VERSION "created by canmatrix"

NS_ :

BS_:

BU_: BDC_Body CHC DME1 EME FLA NiVi ZGW Kombi Kombi_Basis Diagnosetool_FA_CAN CDC_ZGW DME2 ELV Gliwa_T1_Host FA_CAN_Dummy

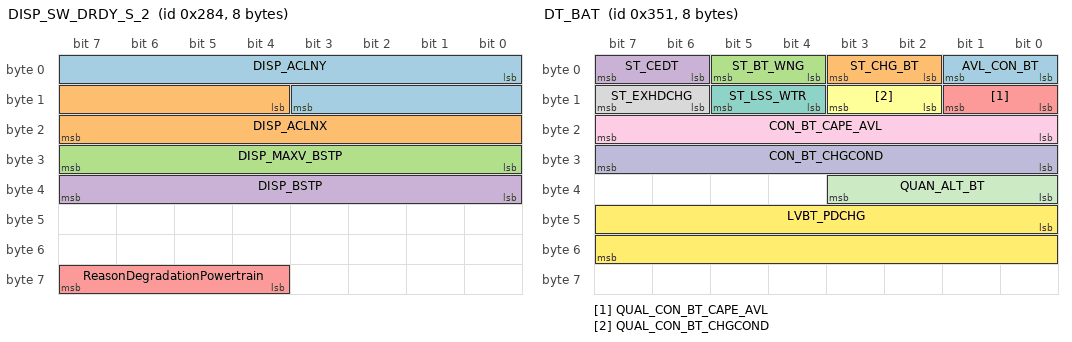
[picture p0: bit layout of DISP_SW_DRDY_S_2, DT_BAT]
BO_ 644 DISP_SW_DRDY_S_2: 8 DME1
 SG_ DISP_ACLNY : 0|12@1+ (0.5,-100) [-150|-50] "%" ZGW
 SG_ DISP_ACLNX : 12|12@1+ (0.5,-100) [-150|-50] "%" ZGW
 SG_ DISP_MAXV_BSTP : 24|8@1+ (0.05,0) [0.00|0.635] "bar" ZGW
 SG_ DISP_BSTP : 32|8@1+ (0.5,0) [0|50] "%" ZGW
 SG_ ReasonDegradationPowertrain : 60|4@1+ (1,0) [0|15] "" Kombi

BO_ 1062 DISP_SW_DRDY_TECGY_EXPI: 4 ZGW
 SG_ ST_SAIL_DRV : 24|4@1+ (1,0) [0|15] "" Kombi,Kombi_Basis

BO_ 1080 DISP_SW_DRDY_TECGY_EXPI_B: 4 ZGW
 SG_ ST_SAIL_DRV : 24|4@1+ (1,0) [0|15] "" Kombi

BO_ 849 DT_BAT: 8 DME1
 SG_ AVL_CON_BT : 0|2@1+ (1,0) [0|3] "" BDC_Body
 SG_ ST_CHG_BT : 2|2@1+ (1,0) [0|3] "" ZGW,BDC_Body
 SG_ ST_BT_WNG : 4|2@1+ (1,0) [0|3] "" ZGW,BDC_Body
 SG_ ST_CEDT : 6|2@1+ (1,0) [0|3] "" BDC_Body
 SG_ QUAL_CON_BT_CAPE_AVL : 8|2@1+ (1,0) [0|3] "" BDC_Body
 SG_ QUAL_CON_BT_CHGCOND : 10|2@1+ (1,0) [0|3] "" ZGW,BDC_Body
 SG_ ST_LSS_WTR : 12|2@1+ (1,0) [0|3] "" BDC_Body
 SG_ ST_EXHDCHG : 14|2@1+ (1,0) [0|3] "" ZGW,BDC_Body
 SG_ CON_BT_CAPE_AVL : 16|8@1+ (1,0) [0|150] "%" ZGW,BDC_Body
 SG_ CON_BT_CHGCOND : 24|8@1+ (1,0) [0|150] "%" ZGW,BDC_Body
 SG_ QUAN_ALT_BT : 32|4@1+ (1,0) [0|14] "This unit fulfills the required AUTOSAR reference to a unit. No real unit is defined." ZGW,BDC_Body
 SG_ LVBT_PDCHG : 40|16@1+ (0.001,-32.766) [-32.798766|-32.733234] "Ah" BDC_Body

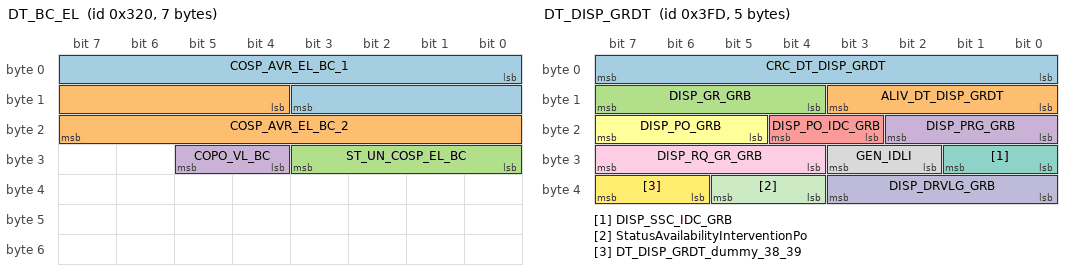
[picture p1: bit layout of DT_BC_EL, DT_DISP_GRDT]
BO_ 800 DT_BC_EL: 7 Kombi
 SG_ COSP_AVR_EL_BC_1 : 0|12@1+ (1,-999) [-1998|0] "This unit fulfills the required AUTOSAR reference to a unit. No real unit is defined." ZGW
 SG_ COSP_AVR_EL_BC_2 : 12|12@1+ (1,-999) [-1998|0] "This unit fulfills the required AUTOSAR reference to a unit. No real unit is defined." ZGW
 SG_ ST_UN_COSP_EL_BC : 24|4@1+ (1,0) [0|15] "" ZGW
 SG_ COPO_VL_BC : 28|2@1+ (1,0) [0|3] "" ZGW

BO_ 1021 DT_DISP_GRDT: 5 DME1
 SG_ CRC_DT_DISP_GRDT : 0|8@1+ (1,0) [0|255] "This unit fulfills the required AUTOSAR reference to a unit. No real unit is defined." Vector__XXX
 SG_ ALIV_DT_DISP_GRDT : 8|4@1+ (1,0) [0|14] "This unit fulfills the required AUTOSAR reference to a unit. No real unit is defined." Vector__XXX
 SG_ DISP_GR_GRB : 12|4@1+ (1,0) [0|15] "" Vector__XXX
 SG_ DISP_PRG_GRB : 16|3@1+ (1,0) [0|7] "" Vector__XXX
 SG_ DISP_PO_IDC_GRB : 19|2@1+ (1,0) [0|3] "" Vector__XXX
 SG_ DISP_PO_GRB : 21|3@1+ (1,0) [0|7] "" Vector__XXX
 SG_ DISP_SSC_IDC_GRB : 24|2@1+ (1,0) [0|3] "" Vector__XXX
 SG_ GEN_IDLI : 26|2@1+ (1,0) [0|3] "" Vector__XXX
 SG_ DISP_RQ_GR_GRB : 28|4@1+ (1,0) [0|15] "" Vector__XXX
 SG_ DISP_DRVLG_GRB : 32|4@1+ (1,0) [0|15] "" Vector__XXX
 SG_ StatusAvailabilityInterventionPo : 36|2@1+ (1,0) [0|3] "" Vector__XXX
 SG_ DT_DISP_GRDT_dummy_38_39 : 38|2@1+ (1,0) [-2|1] "" Vector__XXX

BO_ 996 DT_EL_GEY: 6 ZGW
 SG_ AVL_PWR_EL_GEY : 0|8@1+ (0.04,0) [0.00|0.4064] "kW" DME2,EME,DME1
 SG_ AVL_I_EL_GEY : 8|8@1+ (0.2,0) [0|10.16] "A" CDC_ZGW,EME

BO_ 1042 DT_EWS_1: 8 BDC_Body
 SG_ EWS_COMM_1_1 : 0|32@1+ (1,0) [0|4294967295] "This unit fulfills the required AUTOSAR reference to a unit. No real unit is defined." DME2,DME1
 SG_ EWS_COMM_1_2 : 32|32@1+ (1,0) [0|4294967295] "This unit fulfills the required AUTOSAR reference to a unit. No real unit is defined." DME2,DME1

BO_ 1043 DT_EWS_2: 8 DME1
 SG_ EWS_COMM_2_1 : 0|32@1+ (1,0) [0|4294967295] "This unit fulfills the required AUTOSAR reference to a unit. No real unit is defined." BDC_Body
 SG_ EWS_COMM_2_2 : 32|32@1+ (1,0) [0|4294967295] "This unit fulfills the required AUTOSAR reference to a unit. No real unit is defined." BDC_Body

BO_ 1044 DT_EWS_7: 8 BDC_Body
 SG_ EWS_COMM_7_1 : 0|32@1+ (1,0) [0|4294967295] "This unit fulfills the required AUTOSAR reference to a unit. No real unit is defined." ELV
 SG_ EWS_COMM_7_2 : 32|32@1+ (1,0) [0|4294967295] "This unit fulfills the required AUTOSAR reference to a unit. No real unit is defined." ELV

BO_ 1045 DT_EWS_8: 8 ELV
 SG_ EWS_COMM_8_1 : 0|32@1+ (1,0) [0|4294967295] "This unit fulfills the required AUTOSAR reference to a unit. No real unit is defined." BDC_Body
 SG_ EWS_COMM_8_2 : 32|32@1+ (1,0) [0|4294967295] "This unit fulfills the required AUTOSAR reference to a unit. No real unit is defined." BDC_Body

BO_ 200 DT_FN_HDC: 8 ZGW
 SG_ QU_FN_HDC : 0|8@1+ (1,0) [0|255] "" BDC_Body

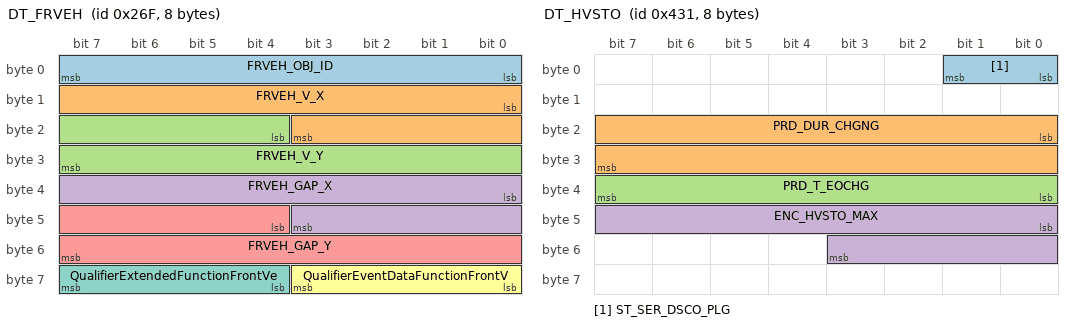
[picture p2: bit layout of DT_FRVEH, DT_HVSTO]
BO_ 623 DT_FRVEH: 8 ZGW
 SG_ FRVEH_OBJ_ID : 0|8@1+ (1,0) [0|252] "This unit fulfills the required AUTOSAR reference to a unit. No real unit is defined." DME2,DME1
 SG_ FRVEH_V_X : 8|12@1+ (0.1,-150) [-165|-135] "m/s" DME2,DME1
 SG_ FRVEH_V_Y : 20|12@1+ (0.1,-150) [-165|-135] "m/s" DME2,DME1
 SG_ FRVEH_GAP_X : 32|12@1+ (0.1,0) [0|30] "m" DME2,DME1
 SG_ FRVEH_GAP_Y : 44|12@1+ (0.2,-300) [-360|-240] "m" DME2,DME1
 SG_ QualifierEventDataFunctionFrontV : 56|4@1+ (1,0) [0|15] "" DME1
 SG_ QualifierExtendedFunctionFrontVe : 60|4@1+ (1,0) [0|15] "" DME1

BO_ 624 DT_FRVEH_EXT: 8 ZGW
 SG_ FRVEH_EXT_OBJ_ID : 0|8@1+ (1,0) [0|252] "This unit fulfills the required AUTOSAR reference to a unit. No real unit is defined." DME2,DME1
 SG_ FRVEH_EXT_OBJ_TYP : 8|8@1+ (1,0) [0|255] "" DME2,DME1
 SG_ FRVEH_EXT_ST_MOV : 16|8@1+ (1,0) [0|255] "" DME2,DME1
 SG_ FRVEH_EXT_WID : 24|8@1+ (0.1,0) [0|2.52] "m" DME2,DME1

BO_ 1073 DT_HVSTO: 8 EME
 SG_ ST_SER_DSCO_PLG : 0|2@1+ (1,0) [0|3] "" CDC_ZGW,ZGW
 SG_ PRD_DUR_CHGNG : 16|16@1+ (1,0) [0|65532] "min" ZGW
 SG_ PRD_T_EOCHG : 32|8@1+ (5,0) [0|6350] "min" ZGW
 SG_ ENC_HVSTO_MAX : 40|12@1+ (0.02,0) [0.00|1.6376] "kWh" ZGW

BO_ 569 DT_HVSTO_2: 8 EME
 SG_ PRD_ENERG_CHGCOND_2_COS : 8|16@1+ (1,0) [0|65534] "Wh" CDC_ZGW,ZGW
 SG_ PRD_ENERG_CHGTAR_2_HVSTO : 24|16@1+ (0.02,0) [0.00|26.2128] "kWh" ZGW
 SG_ AVL_ISRE : 40|8@1+ (10,0) [0|20470] "kOhm" CDC_ZGW

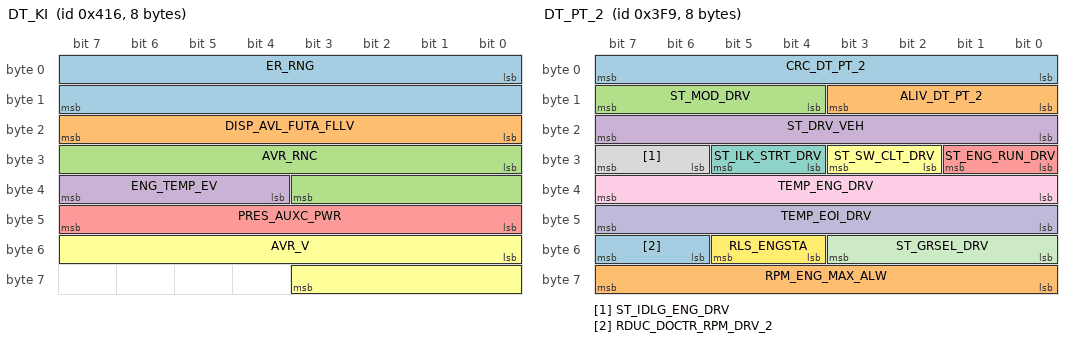
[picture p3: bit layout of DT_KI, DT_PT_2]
BO_ 1046 DT_KI: 8 Kombi
 SG_ ER_RNG : 0|16@1+ (1,0) [0|4000] "km" ZGW
 SG_ DISP_AVL_FUTA_FLLV : 16|8@1+ (0.5,0) [0|50] "%" ZGW,BDC_Body
 SG_ AVR_RNC : 24|12@1+ (0.05,0) [0.00|5.00] "kWh/100km" ZGW
 SG_ ENG_TEMP_EV : 36|4@1+ (1,0) [0|15] "" ZGW
 SG_ PRES_AUXC_PWR : 40|8@1+ (0.25,0) [0.00|5.00] "kW" ZGW
 SG_ AVR_V : 48|12@1+ (0.1,0) [0|30] "km/h" ZGW

BO_ 1017 DT_PT_2: 8 DME1
 SG_ CRC_DT_PT_2 : 0|8@1+ (1,0) [0|255] "This unit fulfills the required AUTOSAR reference to a unit. No real unit is defined." Vector__XXX
 SG_ ALIV_DT_PT_2 : 8|4@1+ (1,0) [0|14] "This unit fulfills the required AUTOSAR reference to a unit. No real unit is defined." Vector__XXX
 SG_ ST_MOD_DRV : 12|4@1+ (1,0) [0|15] "" Vector__XXX
 SG_ ST_DRV_VEH : 16|8@1+ (1,0) [0|255] "" Vector__XXX
 SG_ ST_ENG_RUN_DRV : 24|2@1+ (1,0) [0|3] "" Vector__XXX
 SG_ ST_SW_CLT_DRV : 26|2@1+ (1,0) [0|3] "" Vector__XXX
 SG_ ST_ILK_STRT_DRV : 28|2@1+ (1,0) [0|3] "" Vector__XXX
 SG_ ST_IDLG_ENG_DRV : 30|2@1+ (1,0) [0|3] "" Vector__XXX
 SG_ TEMP_ENG_DRV : 32|8@1+ (1,-48) [-48|144] "°C" Vector__XXX
 SG_ TEMP_EOI_DRV : 40|8@1+ (1,-48) [-48|170] "°C" Vector__XXX
 SG_ ST_GRSEL_DRV : 48|4@1+ (1,0) [0|15] "" Vector__XXX
 SG_ RLS_ENGSTA : 52|2@1+ (1,0) [0|3] "" Vector__XXX
 SG_ RDUC_DOCTR_RPM_DRV_2 : 54|2@1+ (1,0) [0|3] "" Vector__XXX
 SG_ RPM_ENG_MAX_ALW : 56|8@1+ (50,0) [0|635000] "1/min" Vector__XXX

BO_ 811 DT_RNG_CALC: 8 EME
 SG_ AVL_ENERG_COSP_MOT_TRCT : 0|16@1+ (100,0) [0|655340000] "Ws" Kombi
 SG_ AVL_ENERG_MOT_RECUP : 16|16@1+ (1,0) [0|65534] "Ws" Kombi

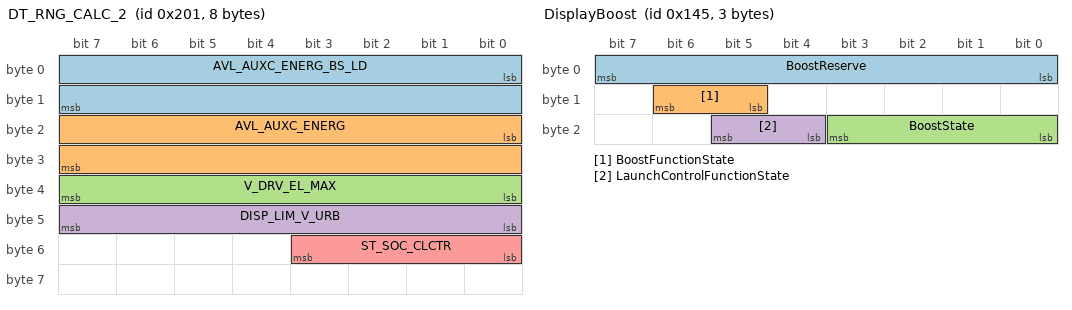
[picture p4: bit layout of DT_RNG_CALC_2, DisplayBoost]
BO_ 513 DT_RNG_CALC_2: 8 EME
 SG_ AVL_AUXC_ENERG_BS_LD : 0|16@1+ (1,0) [0|65534] "Ws" Kombi
 SG_ AVL_AUXC_ENERG : 16|16@1+ (1,0) [0|65534] "Ws" Kombi
 SG_ V_DRV_EL_MAX : 32|8@1+ (1,0) [0|252] "km/h" Kombi
 SG_ DISP_LIM_V_URB : 40|8@1+ (0.5,0) [0|62.5] "km/h" Kombi
 SG_ ST_SOC_CLCTR : 48|4@1+ (1,0) [0|15] "" Kombi,Kombi_Basis

BO_ 984 DXP_MOD: 8 ZGW
 SG_ RQ_SW_DXP_KDIS : 4|2@1+ (1,0) [0|3] "" Kombi,Kombi_Basis
 SG_ AVL_MOD_DXP : 8|6@1+ (1,0) [0|63] "" Kombi,Kombi_Basis

BO_ 325 DisplayBoost: 3 DME1
 SG_ BoostReserve : 0|8@1+ (0.5,0) [0|50] "%" Kombi
 SG_ BoostFunctionState : 13|2@1+ (1,0) [0|3] "" Kombi
 SG_ BoostState : 16|4@1+ (1,0) [0|15] "" Kombi
 SG_ LaunchControlFunctionState : 20|2@1+ (1,0) [0|3] "" Kombi

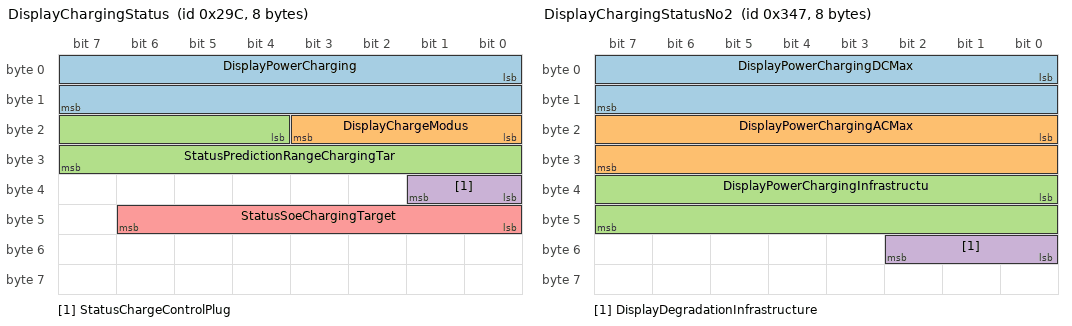
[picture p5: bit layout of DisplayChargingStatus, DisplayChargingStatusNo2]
BO_ 668 DisplayChargingStatus: 8 Diagnosetool_FA_CAN
 SG_ DisplayPowerCharging : 0|16@1+ (10,0) [0|6553200] "W" ZGW,Kombi
 SG_ DisplayChargeModus : 16|4@1+ (1,0) [0|15] "" Kombi
 SG_ StatusPredictionRangeChargingTar : 20|12@1+ (1,0) [0|4092] "km" Kombi
 SG_ StatusChargeControlPlug : 32|2@1+ (1,0) [0|3] "" Kombi
 SG_ StatusSoeChargingTarget : 40|7@1+ (1,0) [0|100] "%" Kombi

BO_ 839 DisplayChargingStatusNo2: 8 EME
 SG_ DisplayPowerChargingDCMax : 0|16@1+ (10,0) [0|6553200] "W" Kombi
 SG_ DisplayPowerChargingACMax : 16|16@1+ (1,0) [0|65532] "W" Kombi
 SG_ DisplayPowerChargingInfrastructu : 32|16@1+ (10,0) [0|6553200] "W" Kombi
 SG_ DisplayDegradationInfrastructure : 48|3@1+ (1,0) [0|7] "" Kombi

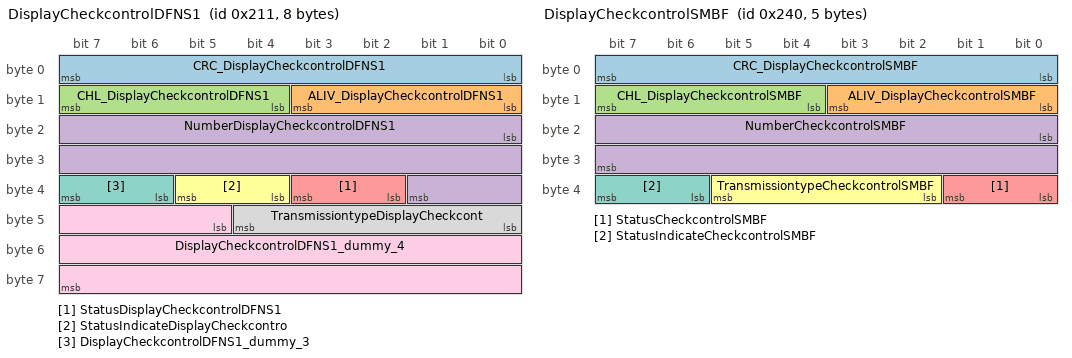
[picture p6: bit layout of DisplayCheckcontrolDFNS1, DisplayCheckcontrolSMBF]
BO_ 529 DisplayCheckcontrolDFNS1: 8 DME1
 SG_ CRC_DisplayCheckcontrolDFNS1 : 0|8@1+ (1,0) [0|255] "This unit fulfills the required AUTOSAR reference to a unit. No real unit is defined." Vector__XXX
 SG_ ALIV_DisplayCheckcontrolDFNS1 : 8|4@1+ (1,0) [0|14] "This unit fulfills the required AUTOSAR reference to a unit. No real unit is defined." Vector__XXX
 SG_ CHL_DisplayCheckcontrolDFNS1 : 12|4@1+ (1,0) [0|14] "This unit fulfills the required AUTOSAR reference to a unit. No real unit is defined." Vector__XXX
 SG_ NumberDisplayCheckcontrolDFNS1 : 16|18@1+ (1,0) [0|65534] "This unit fulfills the required AUTOSAR reference to a unit. No real unit is defined." Vector__XXX
 SG_ StatusDisplayCheckcontrolDFNS1 : 34|2@1+ (1,0) [0|3] "" Vector__XXX
 SG_ StatusIndicateDisplayCheckcontro : 36|2@1+ (1,0) [0|3] "" Vector__XXX
 SG_ DisplayCheckcontrolDFNS1_dummy_3 : 38|2@1+ (1,0) [-2|1] "" Vector__XXX
 SG_ TransmissiontypeDisplayCheckcont : 40|5@1+ (1,0) [0|14] "s" Vector__XXX
 SG_ DisplayCheckcontrolDFNS1_dummy_4 : 45|19@1+ (1,0) [-262144|262143] "" Vector__XXX

BO_ 576 DisplayCheckcontrolSMBF: 5 ZGW
 SG_ CRC_DisplayCheckcontrolSMBF : 0|8@1+ (1,0) [0|255] "This unit fulfills the required AUTOSAR reference to a unit. No real unit is defined." Vector__XXX
 SG_ ALIV_DisplayCheckcontrolSMBF : 8|4@1+ (1,0) [0|14] "This unit fulfills the required AUTOSAR reference to a unit. No real unit is defined." Vector__XXX
 SG_ CHL_DisplayCheckcontrolSMBF : 12|4@1+ (1,0) [0|14] "This unit fulfills the required AUTOSAR reference to a unit. No real unit is defined." Vector__XXX
 SG_ NumberCheckcontrolSMBF : 16|16@1+ (1,0) [0|65534] "This unit fulfills the required AUTOSAR reference to a unit. No real unit is defined." Vector__XXX
 SG_ StatusCheckcontrolSMBF : 32|2@1+ (1,0) [0|3] "" Vector__XXX
 SG_ TransmissiontypeCheckcontrolSMBF : 34|4@1+ (1,0) [0|14] "s" Vector__XXX
 SG_ StatusIndicateCheckcontrolSMBF : 38|2@1+ (1,0) [0|3] "" Vector__XXX

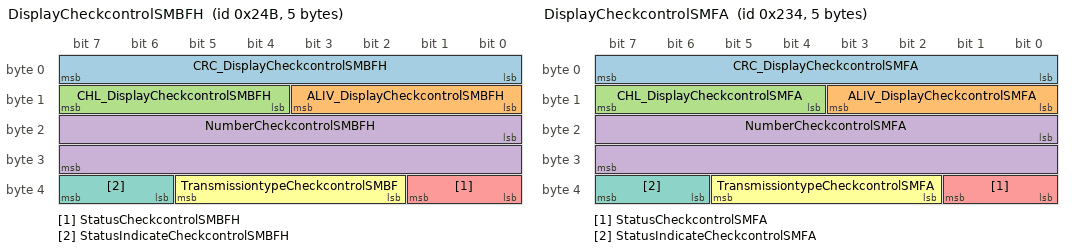
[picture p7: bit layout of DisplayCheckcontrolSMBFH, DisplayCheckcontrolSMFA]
BO_ 587 DisplayCheckcontrolSMBFH: 5 ZGW
 SG_ CRC_DisplayCheckcontrolSMBFH : 0|8@1+ (1,0) [0|255] "This unit fulfills the required AUTOSAR reference to a unit. No real unit is defined." Vector__XXX
 SG_ ALIV_DisplayCheckcontrolSMBFH : 8|4@1+ (1,0) [0|14] "This unit fulfills the required AUTOSAR reference to a unit. No real unit is defined." Vector__XXX
 SG_ CHL_DisplayCheckcontrolSMBFH : 12|4@1+ (1,0) [0|14] "This unit fulfills the required AUTOSAR reference to a unit. No real unit is defined." Vector__XXX
 SG_ NumberCheckcontrolSMBFH : 16|16@1+ (1,0) [0|65534] "This unit fulfills the required AUTOSAR reference to a unit. No real unit is defined." Vector__XXX
 SG_ StatusCheckcontrolSMBFH : 32|2@1+ (1,0) [0|3] "" Vector__XXX
 SG_ TransmissiontypeCheckcontrolSMBF : 34|4@1+ (1,0) [0|14] "s" Vector__XXX
 SG_ StatusIndicateCheckcontrolSMBFH : 38|2@1+ (1,0) [0|3] "" Vector__XXX

BO_ 564 DisplayCheckcontrolSMFA: 5 ZGW
 SG_ CRC_DisplayCheckcontrolSMFA : 0|8@1+ (1,0) [0|255] "This unit fulfills the required AUTOSAR reference to a unit. No real unit is defined." Vector__XXX
 SG_ ALIV_DisplayCheckcontrolSMFA : 8|4@1+ (1,0) [0|14] "This unit fulfills the required AUTOSAR reference to a unit. No real unit is defined." Vector__XXX
 SG_ CHL_DisplayCheckcontrolSMFA : 12|4@1+ (1,0) [0|14] "This unit fulfills the required AUTOSAR reference to a unit. No real unit is defined." Vector__XXX
 SG_ NumberCheckcontrolSMFA : 16|16@1+ (1,0) [0|65534] "This unit fulfills the required AUTOSAR reference to a unit. No real unit is defined." Vector__XXX
 SG_ StatusCheckcontrolSMFA : 32|2@1+ (1,0) [0|3] "" Vector__XXX
 SG_ TransmissiontypeCheckcontrolSMFA : 34|4@1+ (1,0) [0|14] "s" Vector__XXX
 SG_ StatusIndicateCheckcontrolSMFA : 38|2@1+ (1,0) [0|3] "" Vector__XXX

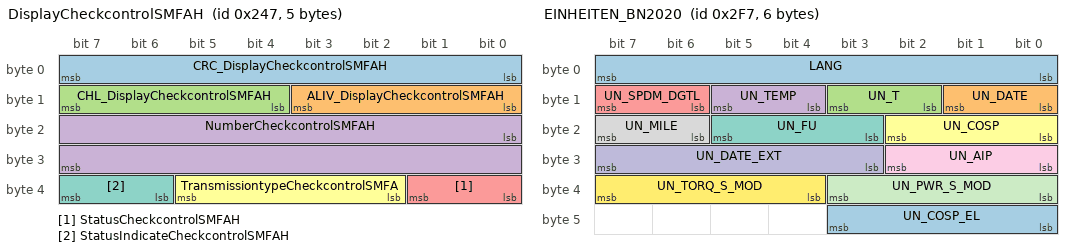
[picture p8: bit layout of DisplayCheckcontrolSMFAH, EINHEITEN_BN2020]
BO_ 583 DisplayCheckcontrolSMFAH: 5 ZGW
 SG_ CRC_DisplayCheckcontrolSMFAH : 0|8@1+ (1,0) [0|255] "This unit fulfills the required AUTOSAR reference to a unit. No real unit is defined." Vector__XXX
 SG_ ALIV_DisplayCheckcontrolSMFAH : 8|4@1+ (1,0) [0|14] "This unit fulfills the required AUTOSAR reference to a unit. No real unit is defined." Vector__XXX
 SG_ CHL_DisplayCheckcontrolSMFAH : 12|4@1+ (1,0) [0|14] "This unit fulfills the required AUTOSAR reference to a unit. No real unit is defined." Vector__XXX
 SG_ NumberCheckcontrolSMFAH : 16|16@1+ (1,0) [0|65534] "This unit fulfills the required AUTOSAR reference to a unit. No real unit is defined." Vector__XXX
 SG_ StatusCheckcontrolSMFAH : 32|2@1+ (1,0) [0|3] "" Vector__XXX
 SG_ TransmissiontypeCheckcontrolSMFA : 34|4@1+ (1,0) [0|14] "s" Vector__XXX
 SG_ StatusIndicateCheckcontrolSMFAH : 38|2@1+ (1,0) [0|3] "" Vector__XXX

BO_ 1174 DisplayDataWaterInjection: 4 DME1
 SG_ DisplayRefillVolumeWaterInjectio : 0|8@1+ (0.1,0) [0|2.5] "l" ZGW
 SG_ DisplayFluidLevelWaterInjection : 8|4@1+ (10,0) [0|1200] "%" ZGW
 SG_ DispAvailabilityWaterInjection : 14|10@1+ (1,0) [0|1023] "" ZGW

BO_ 180 ECU_DOM_CHAS: 4 ZGW
 SG_ CTR_ECU_CHAS : 0|32@1+ (1,0) [0|4294967295] "" FLA,ELV,Kombi_Basis,Diagnosetool_FA_CAN,CHC,Kombi

BO_ 182 ECU_DOM_ENTAI: 8 ZGW
 SG_ CTR_ECU_ENTAI : 0|24@1+ (1,0) [0|16777215] "" Diagnosetool_FA_CAN

BO_ 806 EFFY_INFO_DT: 8 Kombi
 SG_ Multiplexor M : 0|8@1+ (1,0) [-128|127] "" Vector__XXX

BO_ 759 EINHEITEN_BN2020: 6 Kombi
 SG_ LANG : 0|8@1+ (1,0) [0|255] "" ZGW,BDC_Body
 SG_ UN_DATE : 8|2@1+ (1,0) [0|3] "" ZGW
 SG_ UN_T : 10|2@1+ (1,0) [0|3] "" ZGW,BDC_Body
 SG_ UN_TEMP : 12|2@1+ (1,0) [0|3] "" ZGW,BDC_Body
 SG_ UN_SPDM_DGTL : 14|2@1+ (1,0) [0|3] "" ZGW
 SG_ UN_COSP : 16|3@1+ (1,0) [0|7] "" ZGW,BDC_Body
 SG_ UN_FU : 19|3@1+ (1,0) [0|7] "" ZGW,BDC_Body
 SG_ UN_MILE : 22|2@1+ (1,0) [0|3] "" ZGW,BDC_Body
 SG_ UN_AIP : 24|3@1+ (1,0) [0|7] "" ZGW,BDC_Body
 SG_ UN_DATE_EXT : 27|5@1+ (1,0) [0|31] "" ZGW,BDC_Body
 SG_ UN_PWR_S_MOD : 32|4@1+ (1,0) [0|15] "" ZGW
 SG_ UN_TORQ_S_MOD : 36|4@1+ (1,0) [0|15] "" ZGW
 SG_ UN_COSP_EL : 40|4@1+ (1,0) [0|15] "" ZGW,BDC_Body

BO_ 589 ERRM_BN_U: 2 ZGW
 SG_ CTR_ERRM_BN_U : 0|6@1+ (1,0) [0|63] "" CDC_ZGW,ELV

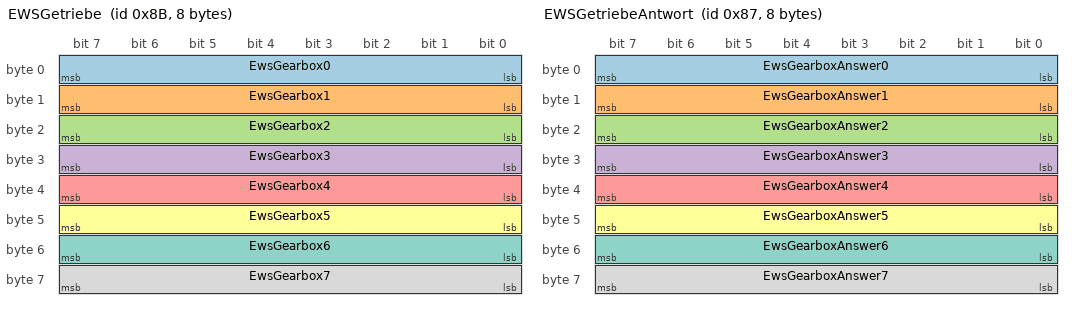
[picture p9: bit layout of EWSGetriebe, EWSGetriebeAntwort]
BO_ 139 EWSGetriebe: 8 DME1
 SG_ EwsGearbox0 : 0|8@1+ (1,0) [0|255] "This unit fulfills the required AUTOSAR reference to a unit. No real unit is defined." BDC_Body
 SG_ EwsGearbox1 : 8|8@1+ (1,0) [0|255] "This unit fulfills the required AUTOSAR reference to a unit. No real unit is defined." BDC_Body
 SG_ EwsGearbox2 : 16|8@1+ (1,0) [0|255] "This unit fulfills the required AUTOSAR reference to a unit. No real unit is defined." BDC_Body
 SG_ EwsGearbox3 : 24|8@1+ (1,0) [0|255] "This unit fulfills the required AUTOSAR reference to a unit. No real unit is defined." BDC_Body
 SG_ EwsGearbox4 : 32|8@1+ (1,0) [0|255] "This unit fulfills the required AUTOSAR reference to a unit. No real unit is defined." BDC_Body
 SG_ EwsGearbox5 : 40|8@1+ (1,0) [0|255] "This unit fulfills the required AUTOSAR reference to a unit. No real unit is defined." BDC_Body
 SG_ EwsGearbox6 : 48|8@1+ (1,0) [0|255] "This unit fulfills the required AUTOSAR reference to a unit. No real unit is defined." BDC_Body
 SG_ EwsGearbox7 : 56|8@1+ (1,0) [0|255] "This unit fulfills the required AUTOSAR reference to a unit. No real unit is defined." BDC_Body

BO_ 135 EWSGetriebeAntwort: 8 BDC_Body
 SG_ EwsGearboxAnswer0 : 0|8@1+ (1,0) [0|255] "This unit fulfills the required AUTOSAR reference to a unit. No real unit is defined." DME1
 SG_ EwsGearboxAnswer1 : 8|8@1+ (1,0) [0|255] "This unit fulfills the required AUTOSAR reference to a unit. No real unit is defined." DME1
 SG_ EwsGearboxAnswer2 : 16|8@1+ (1,0) [0|255] "This unit fulfills the required AUTOSAR reference to a unit. No real unit is defined." DME1
 SG_ EwsGearboxAnswer3 : 24|8@1+ (1,0) [0|255] "This unit fulfills the required AUTOSAR reference to a unit. No real unit is defined." DME1
 SG_ EwsGearboxAnswer4 : 32|8@1+ (1,0) [0|255] "This unit fulfills the required AUTOSAR reference to a unit. No real unit is defined." DME1
 SG_ EwsGearboxAnswer5 : 40|8@1+ (1,0) [0|255] "This unit fulfills the required AUTOSAR reference to a unit. No real unit is defined." DME1
 SG_ EwsGearboxAnswer6 : 48|8@1+ (1,0) [0|255] "This unit fulfills the required AUTOSAR reference to a unit. No real unit is defined." DME1
 SG_ EwsGearboxAnswer7 : 56|8@1+ (1,0) [0|255] "This unit fulfills the required AUTOSAR reference to a unit. No real unit is defined." DME1

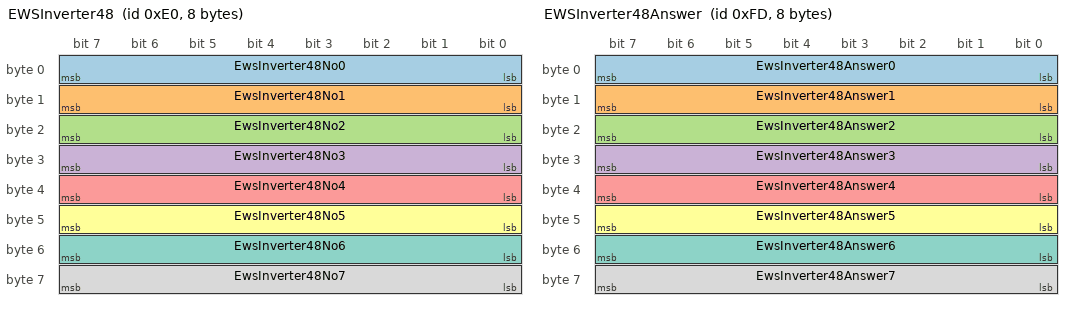
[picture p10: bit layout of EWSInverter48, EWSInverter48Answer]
BO_ 224 EWSInverter48: 8 DME1
 SG_ EwsInverter48No0 : 0|8@1+ (1,0) [0|255] "This unit fulfills the required AUTOSAR reference to a unit. No real unit is defined." BDC_Body
 SG_ EwsInverter48No1 : 8|8@1+ (1,0) [0|255] "This unit fulfills the required AUTOSAR reference to a unit. No real unit is defined." BDC_Body
 SG_ EwsInverter48No2 : 16|8@1+ (1,0) [0|255] "This unit fulfills the required AUTOSAR reference to a unit. No real unit is defined." BDC_Body
 SG_ EwsInverter48No3 : 24|8@1+ (1,0) [0|255] "This unit fulfills the required AUTOSAR reference to a unit. No real unit is defined." BDC_Body
 SG_ EwsInverter48No4 : 32|8@1+ (1,0) [0|255] "This unit fulfills the required AUTOSAR reference to a unit. No real unit is defined." BDC_Body
 SG_ EwsInverter48No5 : 40|8@1+ (1,0) [0|255] "This unit fulfills the required AUTOSAR reference to a unit. No real unit is defined." BDC_Body
 SG_ EwsInverter48No6 : 48|8@1+ (1,0) [0|255] "This unit fulfills the required AUTOSAR reference to a unit. No real unit is defined." BDC_Body
 SG_ EwsInverter48No7 : 56|8@1+ (1,0) [0|255] "This unit fulfills the required AUTOSAR reference to a unit. No real unit is defined." BDC_Body

BO_ 253 EWSInverter48Answer: 8 BDC_Body
 SG_ EwsInverter48Answer0 : 0|8@1+ (1,0) [0|255] "This unit fulfills the required AUTOSAR reference to a unit. No real unit is defined." DME1
 SG_ EwsInverter48Answer1 : 8|8@1+ (1,0) [0|255] "This unit fulfills the required AUTOSAR reference to a unit. No real unit is defined." DME1
 SG_ EwsInverter48Answer2 : 16|8@1+ (1,0) [0|255] "This unit fulfills the required AUTOSAR reference to a unit. No real unit is defined." DME1
 SG_ EwsInverter48Answer3 : 24|8@1+ (1,0) [0|255] "This unit fulfills the required AUTOSAR reference to a unit. No real unit is defined." DME1
 SG_ EwsInverter48Answer4 : 32|8@1+ (1,0) [0|255] "This unit fulfills the required AUTOSAR reference to a unit. No real unit is defined." DME1
 SG_ EwsInverter48Answer5 : 40|8@1+ (1,0) [0|255] "This unit fulfills the required AUTOSAR reference to a unit. No real unit is defined." DME1
 SG_ EwsInverter48Answer6 : 48|8@1+ (1,0) [0|255] "This unit fulfills the required AUTOSAR reference to a unit. No real unit is defined." DME1
 SG_ EwsInverter48Answer7 : 56|8@1+ (1,0) [0|255] "This unit fulfills the required AUTOSAR reference to a unit. No real unit is defined." DME1

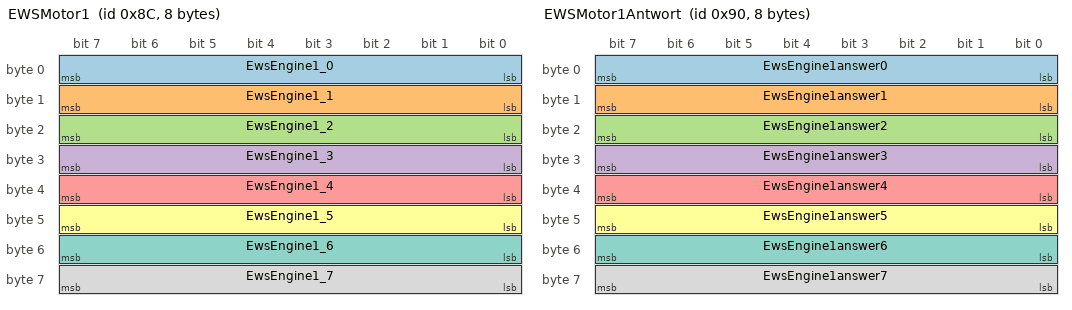
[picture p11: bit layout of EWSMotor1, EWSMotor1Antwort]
BO_ 140 EWSMotor1: 8 DME1
 SG_ EwsEngine1_0 : 0|8@1+ (1,0) [0|255] "This unit fulfills the required AUTOSAR reference to a unit. No real unit is defined." BDC_Body
 SG_ EwsEngine1_1 : 8|8@1+ (1,0) [0|255] "This unit fulfills the required AUTOSAR reference to a unit. No real unit is defined." BDC_Body
 SG_ EwsEngine1_2 : 16|8@1+ (1,0) [0|255] "This unit fulfills the required AUTOSAR reference to a unit. No real unit is defined." BDC_Body
 SG_ EwsEngine1_3 : 24|8@1+ (1,0) [0|255] "This unit fulfills the required AUTOSAR reference to a unit. No real unit is defined." BDC_Body
 SG_ EwsEngine1_4 : 32|8@1+ (1,0) [0|255] "This unit fulfills the required AUTOSAR reference to a unit. No real unit is defined." BDC_Body
 SG_ EwsEngine1_5 : 40|8@1+ (1,0) [0|255] "This unit fulfills the required AUTOSAR reference to a unit. No real unit is defined." BDC_Body
 SG_ EwsEngine1_6 : 48|8@1+ (1,0) [0|255] "This unit fulfills the required AUTOSAR reference to a unit. No real unit is defined." BDC_Body
 SG_ EwsEngine1_7 : 56|8@1+ (1,0) [0|255] "This unit fulfills the required AUTOSAR reference to a unit. No real unit is defined." BDC_Body

BO_ 144 EWSMotor1Antwort: 8 BDC_Body
 SG_ EwsEngine1answer0 : 0|8@1+ (1,0) [0|255] "This unit fulfills the required AUTOSAR reference to a unit. No real unit is defined." DME1
 SG_ EwsEngine1answer1 : 8|8@1+ (1,0) [0|255] "This unit fulfills the required AUTOSAR reference to a unit. No real unit is defined." DME1
 SG_ EwsEngine1answer2 : 16|8@1+ (1,0) [0|255] "This unit fulfills the required AUTOSAR reference to a unit. No real unit is defined." DME1
 SG_ EwsEngine1answer3 : 24|8@1+ (1,0) [0|255] "This unit fulfills the required AUTOSAR reference to a unit. No real unit is defined." DME1
 SG_ EwsEngine1answer4 : 32|8@1+ (1,0) [0|255] "This unit fulfills the required AUTOSAR reference to a unit. No real unit is defined." DME1
 SG_ EwsEngine1answer5 : 40|8@1+ (1,0) [0|255] "This unit fulfills the required AUTOSAR reference to a unit. No real unit is defined." DME1
 SG_ EwsEngine1answer6 : 48|8@1+ (1,0) [0|255] "This unit fulfills the required AUTOSAR reference to a unit. No real unit is defined." DME1
 SG_ EwsEngine1answer7 : 56|8@1+ (1,0) [0|255] "This unit fulfills the required AUTOSAR reference to a unit. No real unit is defined." DME1

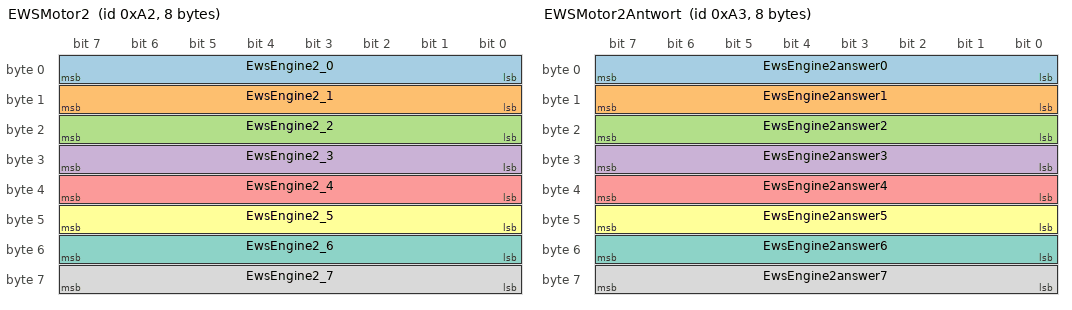
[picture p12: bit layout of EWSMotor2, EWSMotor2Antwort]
BO_ 162 EWSMotor2: 8 DME2
 SG_ EwsEngine2_0 : 0|8@1+ (1,0) [0|255] "This unit fulfills the required AUTOSAR reference to a unit. No real unit is defined." BDC_Body
 SG_ EwsEngine2_1 : 8|8@1+ (1,0) [0|255] "This unit fulfills the required AUTOSAR reference to a unit. No real unit is defined." BDC_Body
 SG_ EwsEngine2_2 : 16|8@1+ (1,0) [0|255] "This unit fulfills the required AUTOSAR reference to a unit. No real unit is defined." BDC_Body
 SG_ EwsEngine2_3 : 24|8@1+ (1,0) [0|255] "This unit fulfills the required AUTOSAR reference to a unit. No real unit is defined." BDC_Body
 SG_ EwsEngine2_4 : 32|8@1+ (1,0) [0|255] "This unit fulfills the required AUTOSAR reference to a unit. No real unit is defined." BDC_Body
 SG_ EwsEngine2_5 : 40|8@1+ (1,0) [0|255] "This unit fulfills the required AUTOSAR reference to a unit. No real unit is defined." BDC_Body
 SG_ EwsEngine2_6 : 48|8@1+ (1,0) [0|255] "This unit fulfills the required AUTOSAR reference to a unit. No real unit is defined." BDC_Body
 SG_ EwsEngine2_7 : 56|8@1+ (1,0) [0|255] "This unit fulfills the required AUTOSAR reference to a unit. No real unit is defined." BDC_Body

BO_ 163 EWSMotor2Antwort: 8 BDC_Body
 SG_ EwsEngine2answer0 : 0|8@1+ (1,0) [0|255] "This unit fulfills the required AUTOSAR reference to a unit. No real unit is defined." DME2
 SG_ EwsEngine2answer1 : 8|8@1+ (1,0) [0|255] "This unit fulfills the required AUTOSAR reference to a unit. No real unit is defined." DME2
 SG_ EwsEngine2answer2 : 16|8@1+ (1,0) [0|255] "This unit fulfills the required AUTOSAR reference to a unit. No real unit is defined." DME2
 SG_ EwsEngine2answer3 : 24|8@1+ (1,0) [0|255] "This unit fulfills the required AUTOSAR reference to a unit. No real unit is defined." DME2
 SG_ EwsEngine2answer4 : 32|8@1+ (1,0) [0|255] "This unit fulfills the required AUTOSAR reference to a unit. No real unit is defined." DME2
 SG_ EwsEngine2answer5 : 40|8@1+ (1,0) [0|255] "This unit fulfills the required AUTOSAR reference to a unit. No real unit is defined." DME2
 SG_ EwsEngine2answer6 : 48|8@1+ (1,0) [0|255] "This unit fulfills the required AUTOSAR reference to a unit. No real unit is defined." DME2
 SG_ EwsEngine2answer7 : 56|8@1+ (1,0) [0|255] "This unit fulfills the required AUTOSAR reference to a unit. No real unit is defined." DME2

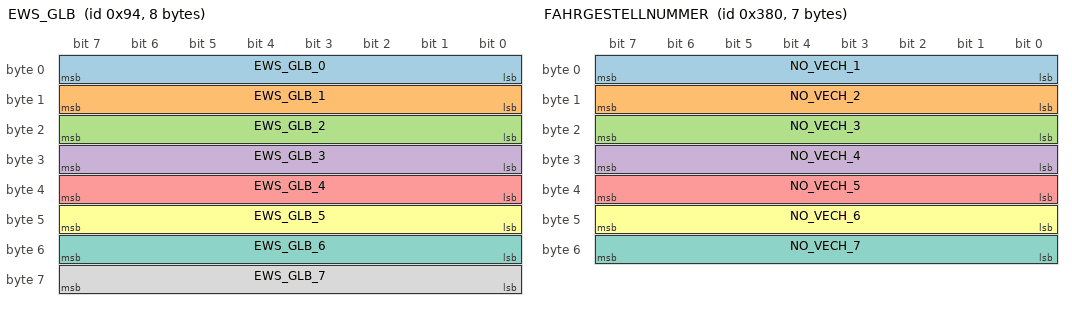
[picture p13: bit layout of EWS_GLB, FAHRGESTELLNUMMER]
BO_ 148 EWS_GLB: 8 BDC_Body
 SG_ EWS_GLB_0 : 0|8@1+ (1,0) [0|255] "This unit fulfills the required AUTOSAR reference to a unit. No real unit is defined." DME2,DME1
 SG_ EWS_GLB_1 : 8|8@1+ (1,0) [0|255] "This unit fulfills the required AUTOSAR reference to a unit. No real unit is defined." DME2,DME1
 SG_ EWS_GLB_2 : 16|8@1+ (1,0) [0|255] "This unit fulfills the required AUTOSAR reference to a unit. No real unit is defined." DME2,DME1
 SG_ EWS_GLB_3 : 24|8@1+ (1,0) [0|255] "This unit fulfills the required AUTOSAR reference to a unit. No real unit is defined." DME2,DME1
 SG_ EWS_GLB_4 : 32|8@1+ (1,0) [0|255] "This unit fulfills the required AUTOSAR reference to a unit. No real unit is defined." DME2,DME1
 SG_ EWS_GLB_5 : 40|8@1+ (1,0) [0|255] "This unit fulfills the required AUTOSAR reference to a unit. No real unit is defined." DME2,DME1
 SG_ EWS_GLB_6 : 48|8@1+ (1,0) [0|255] "This unit fulfills the required AUTOSAR reference to a unit. No real unit is defined." DME2,DME1
 SG_ EWS_GLB_7 : 56|8@1+ (1,0) [0|255] "This unit fulfills the required AUTOSAR reference to a unit. No real unit is defined." DME2,DME1

BO_ 896 FAHRGESTELLNUMMER: 7 BDC_Body
 SG_ NO_VECH_1 : 0|8@1+ (1,0) [0|255] "This unit fulfills the required AUTOSAR reference to a unit. No real unit is defined." Vector__XXX
 SG_ NO_VECH_2 : 8|8@1+ (1,0) [0|255] "This unit fulfills the required AUTOSAR reference to a unit. No real unit is defined." Vector__XXX
 SG_ NO_VECH_3 : 16|8@1+ (1,0) [0|255] "This unit fulfills the required AUTOSAR reference to a unit. No real unit is defined." Vector__XXX
 SG_ NO_VECH_4 : 24|8@1+ (1,0) [0|255] "This unit fulfills the required AUTOSAR reference to a unit. No real unit is defined." Vector__XXX
 SG_ NO_VECH_5 : 32|8@1+ (1,0) [0|255] "This unit fulfills the required AUTOSAR reference to a unit. No real unit is defined." Vector__XXX
 SG_ NO_VECH_6 : 40|8@1+ (1,0) [0|255] "This unit fulfills the required AUTOSAR reference to a unit. No real unit is defined." Vector__XXX
 SG_ NO_VECH_7 : 48|8@1+ (1,0) [0|255] "This unit fulfills the required AUTOSAR reference to a unit. No real unit is defined." Vector__XXX

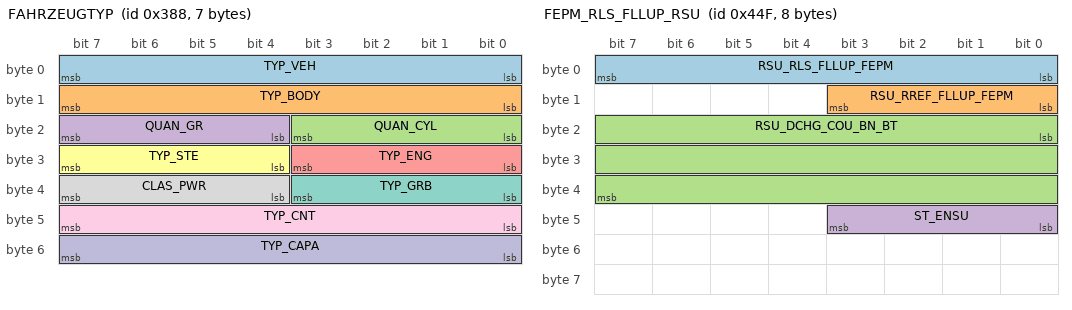
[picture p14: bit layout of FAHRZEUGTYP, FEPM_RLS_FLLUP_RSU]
BO_ 904 FAHRZEUGTYP: 7 BDC_Body
 SG_ TYP_VEH : 0|8@1+ (1,0) [0|255] "" ZGW,DME2,DME1
 SG_ TYP_BODY : 8|8@1+ (1,0) [0|255] "" ZGW,DME2,DME1
 SG_ QUAN_CYL : 16|4@1+ (1,0) [0|15] "" ZGW
 SG_ QUAN_GR : 20|4@1+ (1,0) [0|15] "" ZGW
 SG_ TYP_ENG : 24|4@1+ (1,0) [0|15] "" ZGW
 SG_ TYP_STE : 28|4@1+ (1,0) [0|15] "" ZGW
 SG_ TYP_GRB : 32|4@1+ (1,0) [0|15] "" ZGW
 SG_ CLAS_PWR : 36|4@1+ (1,0) [0|15] "" DME2,DME1
 SG_ TYP_CNT : 40|8@1+ (1,0) [0|255] "" ZGW,DME2,DME1
 SG_ TYP_CAPA : 48|8@1+ (100,0) [0|2540000] "cm³" ZGW,DME1

BO_ 1103 FEPM_RLS_FLLUP_RSU: 8 DME1
 SG_ RSU_RLS_FLLUP_FEPM : 0|8@1+ (1,0) [1|250] "min" ZGW
 SG_ RSU_RREF_FLLUP_FEPM : 8|4@1+ (1,0) [0|15] "" ZGW
 SG_ RSU_DCHG_COU_BN_BT : 16|24@1+ (1,0) [1|16777212] "Ah" ZGW
 SG_ ST_ENSU : 40|4@1+ (1,0) [0|15] "" ZGW

BO_ 1102 FEPM_RQ_FLLUP_RSU: 4 ZGW
 SG_ RSU_RQ_FLLUP_FEPM : 0|8@1+ (1,0) [1|250] "min" DME2,DME1
 SG_ RSU_ST_FLSH_RSLT : 8|3@1+ (1,0) [0|7] "" DME2,DME1

BO_ 958 FLLUPT_GPWSUP: 3 BDC_Body
 SG_ FLLUPT_GPWSUP : 0|12@1+ (10,0) [0|409300] "s" ZGW,DME2,EME,DME1

BO_ 940 FLLUPT_KLEMME_30G_F: 2 BDC_Body
 SG_ FLLUPT_KL_30_ERCTR : 0|12@1+ (10,0) [0|409400] "s" ZGW
 SG_ TYP_DSCO_KL_30_ERCTR : 12|2@1+ (1,0) [0|3] "" Vector__XXX

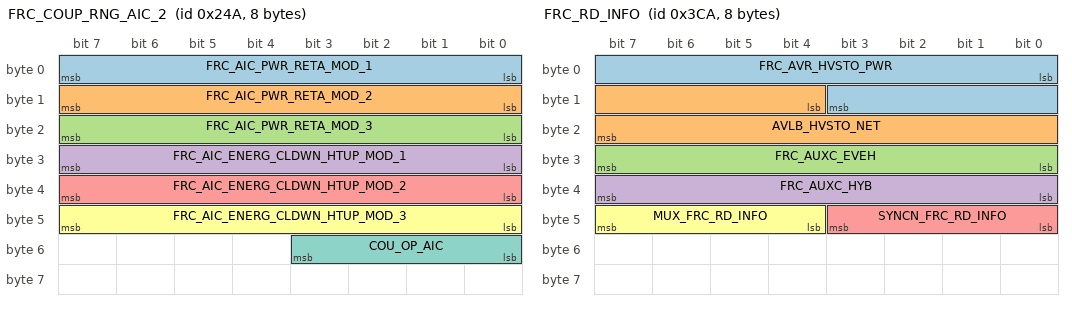
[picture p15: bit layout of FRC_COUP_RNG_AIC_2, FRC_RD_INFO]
BO_ 586 FRC_COUP_RNG_AIC_2: 8 ZGW
 SG_ FRC_AIC_PWR_RETA_MOD_1 : 0|8@1+ (0.05,0) [0.00|0.630] "kW" Kombi
 SG_ FRC_AIC_PWR_RETA_MOD_2 : 8|8@1+ (0.05,0) [0.00|0.630] "kW" Kombi
 SG_ FRC_AIC_PWR_RETA_MOD_3 : 16|8@1+ (0.05,0) [0.00|0.630] "kW" Kombi
 SG_ FRC_AIC_ENERG_CLDWN_HTUP_MOD_1 : 24|8@1+ (0.05,0) [0.00|0.630] "kW" Kombi
 SG_ FRC_AIC_ENERG_CLDWN_HTUP_MOD_2 : 32|8@1+ (0.05,0) [0.00|0.630] "kW" Kombi
 SG_ FRC_AIC_ENERG_CLDWN_HTUP_MOD_3 : 40|8@1+ (0.05,0) [0.00|0.630] "kW" Kombi
 SG_ COU_OP_AIC : 48|4@1+ (1,0) [0|14] "This unit fulfills the required AUTOSAR reference to a unit. No real unit is defined." Kombi

BO_ 970 FRC_RD_INFO: 8 Kombi
 SG_ FRC_AVR_HVSTO_PWR : 0|12@1+ (0.05,0) [0.00|10.235] "kW" ZGW,EME
 SG_ AVLB_HVSTO_NET : 12|12@1+ (20,0) [0|1637600] "Wh" ZGW
 SG_ FRC_AUXC_EVEH : 24|8@1+ (0.05,0) [0.00|0.635] "kW" ZGW
 SG_ FRC_AUXC_HYB : 32|8@1+ (0.05,0) [0.00|0.635] "This unit fulfills the required AUTOSAR reference to a unit. No real unit is defined." ZGW
 SG_ SYNCN_FRC_RD_INFO : 40|4@1+ (1,0) [0|14] "This unit fulfills the required AUTOSAR reference to a unit. No real unit is defined." ZGW,EME
 SG_ MUX_FRC_RD_INFO : 44|4@1+ (1,0) [0|15] "" ZGW,EME

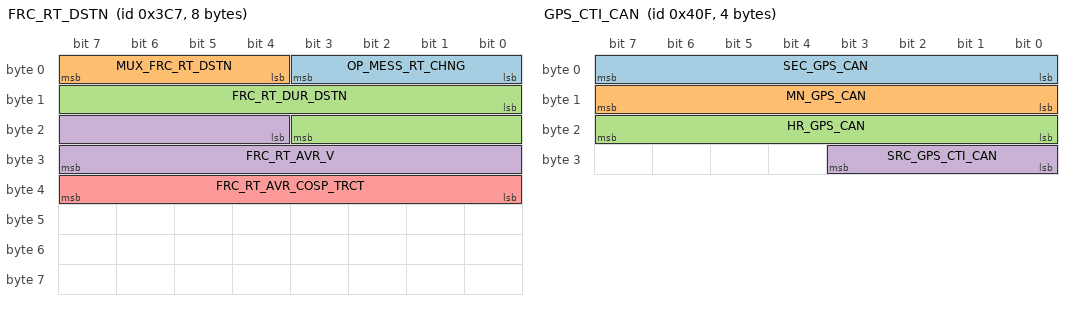
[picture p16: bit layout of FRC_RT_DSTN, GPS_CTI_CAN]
BO_ 967 FRC_RT_DSTN: 8 ZGW
 SG_ OP_MESS_RT_CHNG : 0|4@1+ (1,0) [0|14] "This unit fulfills the required AUTOSAR reference to a unit. No real unit is defined." Kombi,Kombi_Basis
 SG_ MUX_FRC_RT_DSTN : 4|4@1+ (1,0) [0|15] "" Kombi,Kombi_Basis
 SG_ FRC_RT_DUR_DSTN : 8|12@1+ (0.5,0) [0|1023.5] "min" Kombi,Kombi_Basis
 SG_ FRC_RT_AVR_V : 20|12@1+ (0.1,0) [0|32] "km/h" Kombi,Kombi_Basis
 SG_ FRC_RT_AVR_COSP_TRCT : 32|8@1+ (5,0) [0|6350] "Wh/km" Kombi,Kombi_Basis

BO_ 250 FRSG_STREET: 8 ZGW
 SG_ Multiplexor M : 0|8@1+ (1,0) [-128|127] "" Vector__XXX

BO_ 928 FZZSTD: 8 ZGW
 SG_ ST_ENERG_FZM : 16|4@1+ (1,0) [0|15] "" BDC_Body,FLA,EME,DME2,DME1,NiVi
 SG_ ST_ILK_ERRM_FZM : 56|2@1+ (1,0) [0|3] "" BDC_Body,NiVi,FLA,ELV,EME,DME2,DME1,Kombi_Basis,Kombi

BO_ 620 GO_PY_AVAI: 8 ZGW
 SG_ GO_PY_AVAI : 16|2@1+ (1,0) [0|3] "" Kombi,Kombi_Basis

BO_ 1039 GPS_CTI_CAN: 4 ZGW
 SG_ SEC_GPS_CAN : 0|8@1+ (1,0) [0|59] "s" Kombi,Kombi_Basis
 SG_ MN_GPS_CAN : 8|8@1+ (1,0) [0|59] "min" Kombi,Kombi_Basis
 SG_ HR_GPS_CAN : 16|8@1+ (1,0) [0|23] "h" Kombi,Kombi_Basis
 SG_ SRC_GPS_CTI_CAN : 24|4@1+ (1,0) [0|15] "" Kombi,Kombi_Basis

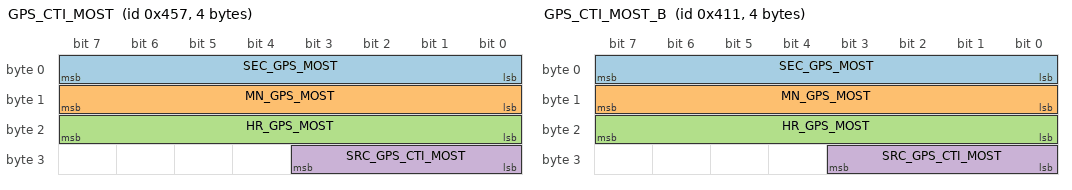
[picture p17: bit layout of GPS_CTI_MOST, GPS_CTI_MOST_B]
BO_ 1111 GPS_CTI_MOST: 4 ZGW
 SG_ SEC_GPS_MOST : 0|8@1+ (1,0) [0|59] "s" Kombi,Kombi_Basis
 SG_ MN_GPS_MOST : 8|8@1+ (1,0) [0|59] "min" Kombi,Kombi_Basis
 SG_ HR_GPS_MOST : 16|8@1+ (1,0) [0|23] "h" Kombi,Kombi_Basis
 SG_ SRC_GPS_CTI_MOST : 24|4@1+ (1,0) [0|15] "" Kombi,Kombi_Basis

BO_ 1041 GPS_CTI_MOST_B: 4 ZGW
 SG_ SEC_GPS_MOST : 0|8@1+ (1,0) [0|59] "s" Kombi
 SG_ MN_GPS_MOST : 8|8@1+ (1,0) [0|59] "min" Kombi
 SG_ HR_GPS_MOST : 16|8@1+ (1,0) [0|23] "h" Kombi
 SG_ SRC_GPS_CTI_MOST : 24|4@1+ (1,0) [0|15] "" Kombi

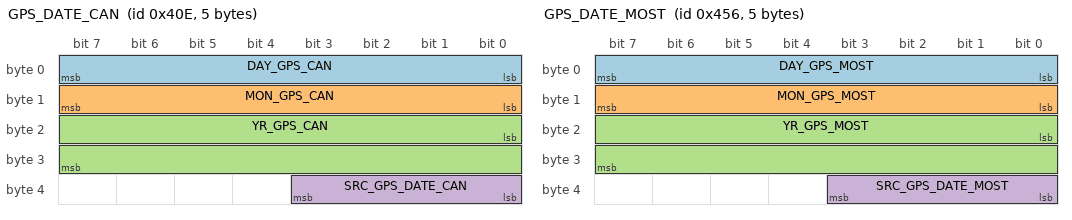
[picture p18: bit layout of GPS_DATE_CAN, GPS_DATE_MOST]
BO_ 1038 GPS_DATE_CAN: 5 ZGW
 SG_ DAY_GPS_CAN : 0|8@1+ (1,0) [0|31] "d" Kombi,Kombi_Basis
 SG_ MON_GPS_CAN : 8|8@1+ (1,0) [0|12] "mon" Kombi,Kombi_Basis
 SG_ YR_GPS_CAN : 16|16@1+ (1,0) [0|65535] "a" Kombi,Kombi_Basis
 SG_ SRC_GPS_DATE_CAN : 32|4@1+ (1,0) [0|15] "" Kombi,Kombi_Basis

BO_ 1110 GPS_DATE_MOST: 5 ZGW
 SG_ DAY_GPS_MOST : 0|8@1+ (1,0) [0|31] "d" Kombi,Kombi_Basis
 SG_ MON_GPS_MOST : 8|8@1+ (1,0) [0|12] "mon" Kombi,Kombi_Basis
 SG_ YR_GPS_MOST : 16|16@1+ (1,0) [0|65535] "a" Kombi,Kombi_Basis
 SG_ SRC_GPS_DATE_MOST : 32|4@1+ (1,0) [0|15] "" Kombi,Kombi_Basis

BO_ 1040 GPS_DATE_MOST_B: 5 ZGW
 SG_ DAY_GPS_MOST : 0|8@1+ (1,0) [0|31] "d" Kombi
 SG_ MON_GPS_MOST : 8|8@1+ (1,0) [0|12] "mon" Kombi
 SG_ YR_GPS_MOST : 16|16@1+ (1,0) [0|65535] "a" Kombi
 SG_ SRC_GPS_DATE_MOST : 32|4@1+ (1,0) [0|15] "" Kombi

BO_ 2675460105 GliwaT1DME1HostTx: 8 Gliwa_T1_Host
 SG_ GliwaDME1HostTxDummysignal : 0|8@1+ (1,0) [0|252] "This unit fulfills the required AUTOSAR reference to a unit. No real unit is defined." DME1

BO_ 2675460106 GliwaT1DME1Tx: 8 DME1
 SG_ GliwaDME1TxDummysignal : 0|8@1+ (1,0) [0|252] "This unit fulfills the required AUTOSAR reference to a unit. No real unit is defined." Gliwa_T1_Host

BO_ 2675461120 GliwaT1DME2HostTx: 8 Gliwa_T1_Host
 SG_ GliwaDME2HostTxDummysignal : 0|8@1+ (1,0) [0|252] "This unit fulfills the required AUTOSAR reference to a unit. No real unit is defined." DME2

BO_ 2675461121 GliwaT1DME2Tx: 8 DME2
 SG_ GliwaDME2TxDummysignal : 0|8@1+ (1,0) [0|252] "This unit fulfills the required AUTOSAR reference to a unit. No real unit is defined." Gliwa_T1_Host

BO_ 207 HDWOBS_FCM: 8 ZGW
 SG_ QU_FN_FCM : 16|4@1+ (1,0) [0|15] "" DME2,DME1

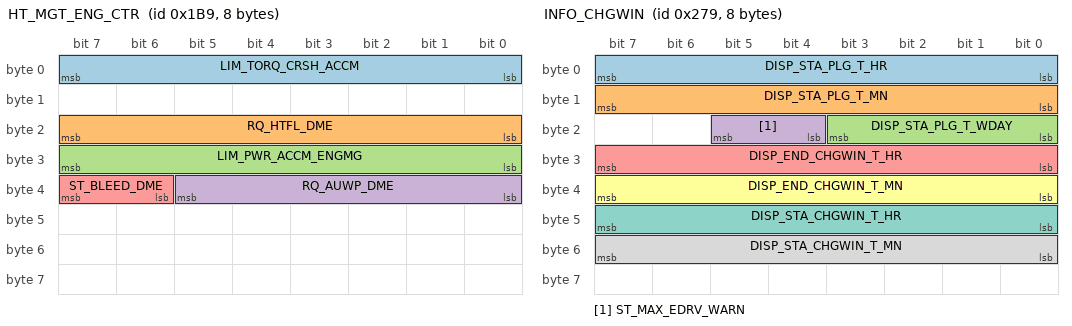
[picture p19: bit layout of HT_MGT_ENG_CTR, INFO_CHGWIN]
BO_ 441 HT_MGT_ENG_CTR: 8 DME1
 SG_ LIM_TORQ_CRSH_ACCM : 0|8@1+ (0.5,0) [0|15] "Nm" ZGW,BDC_Body
 SG_ RQ_HTFL_DME : 16|8@1+ (0.5,0) [0|50] "%" ZGW
 SG_ LIM_PWR_ACCM_ENGMG : 24|8@1+ (0.5,0) [0|63] "kW" ZGW
 SG_ RQ_AUWP_DME : 32|6@1+ (2.5,0) [0|250] "%" ZGW
 SG_ ST_BLEED_DME : 38|2@1+ (1,0) [0|3] "" ZGW

BO_ 1067 HighVoltageStorageInfoToExternal: 4 Vector__XXX
 SG_ EnergyDischargeHighVoltageStorag0 : 0|16@1+ (0.01,-50) [-50.50|-44.00] "kWh" Kombi
 SG_ EnergyDischargeHighVoltageStorag1 : 16|16@1+ (0.01,-50) [-50.50|-44.00] "kWh" Kombi

BO_ 633 INFO_CHGWIN: 8 EME
 SG_ DISP_STA_PLG_T_HR : 0|8@1+ (1,0) [0|23] "h" ZGW
 SG_ DISP_STA_PLG_T_MN : 8|8@1+ (1,0) [0|59] "min" ZGW
 SG_ DISP_STA_PLG_T_WDAY : 16|4@1+ (1,0) [0|15] "" ZGW
 SG_ ST_MAX_EDRV_WARN : 20|2@1+ (1,0) [0|3] "" ZGW
 SG_ DISP_END_CHGWIN_T_HR : 24|8@1+ (1,0) [0|23] "h" ZGW
 SG_ DISP_END_CHGWIN_T_MN : 32|8@1+ (1,0) [0|59] "min" ZGW
 SG_ DISP_STA_CHGWIN_T_HR : 40|8@1+ (1,0) [0|23] "h" ZGW
 SG_ DISP_STA_CHGWIN_T_MN : 48|8@1+ (1,0) [0|59] "min" ZGW

BO_TX_BU_ 800 : Kombi,Kombi_Basis;
BO_TX_BU_ 1021 : DME1,EME;
BO_TX_BU_ 1046 : Kombi,Kombi_Basis;
BO_TX_BU_ 668 : Diagnosetool_FA_CAN,EME;
BO_TX_BU_ 806 : Kombi,Kombi_Basis;
BO_TX_BU_ 759 : Kombi,Kombi_Basis;
CM_ BO_ 800  "In dieser Nachricht werden Bordcomputer-Daten des Elektroantriebes �bertragen.
==========
This message transmits onboard computer data for the electric drive.";
CM_ BO_ 576  "Abgesicherte Checkcontrol Meldungen der Sitzmodul-Beifahrer Funktion an das Kombi Instrument.
Um eine Alive-�berwachung des Sendersteuerger�ts zu erm�glichen ist die Botschaft mit Alive-Z�hler und CRC ausgestattet.
Die Funktionsidentifikation \"SM_BF\" entspricht der Senderfunktion \"Sitzmodul Beifahrer\".
Soll eine CC Meldung auf dem zyklischen Kanal versendet werden, so wird die entsprechende CC ID als NumberCheckcontrolSMBF, mit dem Wert \"Setzen\" als StatusCheckcontrolSMBF und mit einer im Signal TransmissiontypeCheckcontrolSMBF festgelegten \"Wiederholrate\" in Sekunden versendet. Die folgenden Botschaften bis zum Ablauf der als \"Wiederholrate\" festgelegten Zeitspanne werden mit dem Wert \"0xFFFE\" als NumberCheckcontrolSMBF und dem Wert \"R�cksetzen\" als StatusCheckontrolSMBF.
==========
Validated Check Control messages of the front passenger seat module function to the instrument cluster.
To enable Alive monitoring of the electronic sender ECU, the message is equipped with an Alive counter and a CRC.
The function identification \"SM_BF\" corresponds to the sender function \"front passenger seat module\".
If a CC message is to be sent on the cyclical channel, the corresponding CC ID shall be sent as NumberCheckcontrolSMBF with the value \"setting\" as StatusCheckcontrolSMBF and with a \"repetition rate\" defined in seconds in the signal TransmissiontypeCheckcontrolSMBF. The following messages up to the end of the time period defined as \"repetition rate\" are sent with the value \"0xFFFE\" as NumberCheckcontrolSMBF and the value \"reset\" as StatusCheckontrolSMBF.";
CM_ BO_ 587  "Abgesicherte Checkcontrol Meldungen der Sitzmodul-Beifahrer-hinten Funktion an das Kombi Instrument.
Um eine Alive-�berwachung des Sendersteuerger�ts zu erm�glichen ist die Botschaft mit Alive-Z�hler und CRC ausgestattet.
Die Funktionsidentifikation \"SM_BFH\" entspricht der Senderfunktion \"Sitzmodul Beifahrer hinten\".
Soll eine CC Meldung auf dem zyklischen Kanal versendet werden, so wird die entsprechende CC ID als NumberCheckcontrolSMBFH, mit dem Wert \"Setzen\" als StatusCheckcontrolSMBFH und mit einer im Signal TransmissiontypeCheckcontrolSMBFH festgelegten \"Wiederholrate\" in Sekunden versendet. Die folgenden Botschaften bis zum Ablauf der als \"Wiederholrate\" festgelegten Zeitspanne werden mit dem Wert \"0xFFFE\" als NumberCheckcontrolSMBFH und dem Wert \"R�cksetzen\" als StatusCheckontrolSMBFH.
==========
Validated Check Control messages of the passenger side rear passenger seat module function to the instrument cluster.
To enable Alive monitoring of the electronic sender ECU, the message is equipped with an Alive counter and a CRC.
The function identification \"SM_BFH\" corresponds to the sender function \"passenger side rear passenger seat module\".
If a CC message is to be sent on the cyclical channel, the corresponding CC ID shall be sent as NumberCheckcontrolSMBFH, with the value \"setting\" as StatusCheckcontrolSMBFH and with a \"repetition rate\" defined in seconds in the signal TransmissiontypeCheckcontrolSMBFH. The following messages up to the end of the time period defined as \"repetition rate\" are sent as NumberCheckcontrolSMBFH with the value \"0xFFFE\" and with the value \"reset\" as StatusCheckontrolSMBFH.";
CM_ BO_ 564  "Abgesicherte Checkcontrol Meldungen der Sitzmodul-Fahrer Funktion an das Kombi Instrument.
Um eine Alive-�berwachung des Sendersteuerger�ts zu erm�glichen ist die Botschaft mit Alive-Z�hler und CRC ausgestattet.
Die Funktionsidentifikation \"SM_FA\" entspricht der Senderfunktion \"Sitzmodul Fahrer\".
Soll eine CC Meldung auf dem zyklischen Kanal versendet werden, so wird die entsprechende CC ID als NumberCheckcontrolSMFA, mit dem Wert \"Setzen\" als StatusCheckcontrolSMFA und mit einer im Signal TrasmissiontypeCheckcontrolSMFA festgelegten \"Wiederholrate\" in Sekunden versendet. Die folgenden Botschaften bis zum Ablauf der als \"Wiederholrate\" festgelegten Zeitspanne werden mit dem Wert \"0xFFFE\" als NumberCheckcontrolSMFA und dem Wert \"R�cksetzen\" als StatusCheckcontrolSMFA.
==========
Validated Check Control messages of the driver seat module function to the instrument cluster.
To enable Alive monitoring of the electronic sender ECU, the message is equipped with an Alive counter and a CRC.
The function identification \"SM_FA\" corresponds to the sender function \"driver seat module\".
If a CC message is to be sent on the cyclical channel, the corresponding CC ID shall be sent as NumberCheckcontrolSMFA, with the value \"setting\" as StatusCheckcontrolSMFA and with a \"repetition rate\" defined in seconds in the signal TransmissiontypeCheckcontrolSMFA. The following messages up to the end of the time period defined as \"repetition rate\" are sent with the value \"0xFFFE\" as NumberCheckcontrolSMFA and the value \"reset\" as StatusCheckcontrolSMFA.";
CM_ BO_ 583  "Abgesicherte Checkcontrol Meldungen der Sitzmodul-Fahrer-hinten Funktion an das Kombi Instrument.
Um eine Alive-�berwachung des Sendersteuerger�ts zu erm�glichen ist die Botschaft mit Alive-Z�hler und CRC ausgestattet.
Die Funktionsidentifikation \"SM_FAH\" entspricht der Senderfunktion \"Sitzmodul Fahrer hinten\".
Soll eine CC Meldung auf dem zyklischen Kanal versendet werden, so wird die entsprechende CC ID als NumberCheckcontrolSMFAH, mit dem Wert \"Setzen\" als StatusCheckcontrolSMFAH und mit einer im Signal TrasmissiontypeCheckcontrolSMFAH festgelegten \"Wiederholrate\" in Sekunden versendet. Die folgenden Botschaften bis zum Ablauf der als \"Wiederholrate\" festgelegten Zeitspanne werden mit dem Wert \"0xFFFE\" als NumberCheckcontrolSMFAH und dem Wert \"R�cksetzen\" als StatusCheckcontrolSMFAH.
==========
Validated Check Control messages of the driver's side rear passenger seat module function to the instrument cluster.
To enable Alive monitoring of the electronic sender ECU, the message is equipped with an Alive counter and a CRC.
The function identification \"SM_FAH\" corresponds to the sender function \"driver's side rear passenger seat module\".
If a CC message is to be sent on the cyclical channel, the corresponding CC ID shall be sent as NumberCheckcontrolSMFAH, with the value \"setting\" as StatusCheckcontrolSMFAH and with a \"repetition rate\" defined in seconds in the signal TransmissiontypeCheckcontrolSMFAH. The following messages up to the end of the time period defined as \"repetition rate\" are sent with the value \"0xFFFE\" as NumberCheckcontrolSMFAH and the value \"reset\" as StatusCheckcontrolSMFAH.";
CM_ BO_ 1039  "Die Nachricht korrespondiert mit der Nachricht \"GPS Uhrzeit MOST\".
Je nach Verbauvariante des Fahrzeuges werden die Navi-Daten vom MOST in den CAN (Fahrzeug mit Navigation, Signalnamen enth�lt MOST) oder vom CAN in den MOST (Fahrzeug ohne Navigation, Signalnamen enth�lt CAN) gesendet.
Nachricht wird beim Aufstarten, bei erster g�ltiger Signalverf�gbarkeit und anschlie�end bei jedem Wechsel bei den Minuten gesendet (sobald die Sekunde den Wert 00 durchlaufen hat).
Ab ATM2: Die Botschaft enth�lt die Schaltsekunden.
The message corresponds with the message \"GPS Uhrzeit MOST\".
Depending on vehicle option variants, the positioning data is either sent from MOST to CAN (vehicles with navigation, Signal name includes MOST), or from CAN to MOST (vehicles with Telematics but no navigation, Signal name includes CAN).
==========
The message corresponds to the message \"GPS Uhrzeit MOST\".
Depending on the installation variant of the vehicle, the navigation data are sent from the MOST to the CAN (vehicle with navigation system, signal name contains \"MOST\") or from the CAN to the MOST (vehicle without navigation system, signal name contains CAN).
Message is sent during start-up upon first valid signal availability and subsequently upon each minute change (as soon as the second has passed the value 00).
From ATM2: The message contains the switching seconds.
The message corresponds to the message \"GPS Uhrzeit MOST\".
Depending on vehicle option variants, the positioning data is either sent from MOST to CAN (vehicles with navigation, Signal name includes MOST), or from CAN to MOST (vehicles with Telematics but no navigation, Signal name includes CAN).";
CM_ BO_ 1111  "Die Nachricht korrespondiert mit der Nachricht \"GPS Uhrzeit CAN\".
Je nach Verbauvariante des Fahrzeuges werden die Navi-Daten vom MOST in den CAN (Fahrzeug mit Navigation, Signalnamen enth�lt MOST) oder vom CAN in den MOST (Fahrzeug ohne Navigation, Signalnamen enth�lt CAN) gesendet.
Nachricht wird beim Aufstarten, bei erster g�ltiger Signalverf�gbarkeit und anschlie�end bei jedem Wechsel bei den Minuten gesendet (sobald die Sekunde den Wert 00 durchlaufen hat).
The message corresponds with the message \"GPS Datum CAN\".
Depending on vehicle option variants, the positioning data is either sent from MOST to CAN (vehicles with navigation, Signal name includes MOST), or from CAN to MOST (vehicles with Telematics but no navigation, Signal name includes CAN).
MGU: Die Botschaft enth�lt die Schaltsekunden.
==========
The message corresponds to the message \"GPS Uhrzeit MOST\".
Depending on the installation variant of the vehicle, the navigation data are sent from the MOST to the CAN (vehicle with navigation system, signal name contains \"MOST\") or from the CAN to the MOST (vehicle without navigation system, signal name contains CAN).
Message is sent during start-up upon first valid signal availability and subsequently upon each minute change (as soon as the second has passed the value 00).
The message corresponds with the message \"GPS Datum CAN\".
Depending on vehicle option variants, the positioning data is either sent from MOST to CAN (vehicles with navigation, Signal name includes MOST), or from CAN to MOST (vehicles with Telematics but no navigation, Signal name includes CAN).
MGU: The message contains the switching seconds.";
CM_ BO_ 1041  "Die Nachricht korrespondiert mit der Nachricht \"GPS Uhrzeit CAN\".
Je nach Verbauvariante des Fahrzeuges werden die Navi-Daten vom MOST in den CAN (Fahrzeug mit Navigation, Signalnamen enth�lt MOST) oder vom CAN in den MOST (Fahrzeug ohne Navigation, Signalnamen enth�lt CAN) gesendet.
Nachricht wird beim Aufstarten, bei erster g�ltiger Signalverf�gbarkeit und anschlie�end bei jedem Wechsel bei den Minuten gesendet (sobald die Sekunde den Wert 00 durchlaufen hat).
The message corresponds with the message \"GPS Datum CAN\".
Depending on vehicle option variants, the positioning data is either sent from MOST to CAN (vehicles with navigation, Signal name includes MOST), or from CAN to MOST (vehicles with Telematics but no navigation, Signal name includes CAN).
MGU: Die Botschaft enth�lt die Schaltsekunden.";
CM_ BO_ 1038  "Die Nachricht korrespondiert mit der Nachricht \"GPS Datum MOST\".
Je nach Verbauvariante des Fahrzeuges werden die Navi-Daten vom MOST in den CAN (Fahrzeug mit Navigation, Signalnamen enth�lt MOST) oder vom CAN in den MOST (Fahrzeug ohne Navigation, Signalnamen enth�lt CAN) gesendet.
Nachricht wird beim Aufstarten und anschlie�end bei jedem Wechsel beim Tag gesendet.
Ab ATM2: Die Botschaft enth�lt die Schaltsekunden.
The message corresponds with the message \"GPS Datum MOST\".
Depending on vehicle option variants, the positioning data is either sent from MOST to CAN (vehicles with navigation, Signal name includes MOST), or from CAN to MOST (vehicles with Telematics but no navigation, Signal name includes CAN).
==========
The message corresponds with the message \"GPS Datum MOST\".
Depending on the installation variant of the vehicle, the navigation data are sent from the MOST to the CAN (vehicle with navigation system, signal name contains \"MOST\") or from the CAN to the MOST (vehicle without navigation system, signal name contains CAN).
The message is sent upon start-up and subsequently upon each change of the tag.
From ATM2: The message contains the switching seconds.
The message corresponds with the message \"GPS Datum MOST\".
Depending on vehicle option variants, the positioning data is either sent from MOST to CAN (vehicles with navigation, Signal name includes MOST), or from CAN to MOST (vehicles with Telematics but no navigation, Signal name includes CAN).";
CM_ BO_ 1110  "Die Nachricht korrespondiert mit der Nachricht \"GPS Datum CAN\".
Je nach Verbauvariante des Fahrzeuges werden die Navi-Daten vom MOST in den CAN (Fahrzeug mit Navigation, Signalnamen enth�lt MOST) oder vom CAN in den MOST (Fahrzeug ohne Navigation, Signalnamen enth�lt CAN) gesendet.
Nachricht wird beim Aufstarten und anschlie�end bei jedem Wechsel beim Tag gesendet.
The message corresponds with the message \"GPS Datum CAN\".
Depending on vehicle option variants, the positioning data is either sent from MOST to CAN (vehicles with navigation, Signal name includes MOST), or from CAN to MOST (vehicles with Telematics but no navigation, Signal name includes CAN).
MGU: Die Botschaft enth�lt die Schaltsekunden.
==========
The message corresponds to the message \"GPS Datum CAN\".
Depending on the installation variant of the vehicle, the navigation data are sent from the MOST to the CAN (vehicle with navigation system, signal name contains \"MOST\") or from the CAN to the MOST (vehicle without navigation system, signal name contains CAN).
The message is sent upon start-up and subsequently upon each change of the tag.
The message corresponds with the message \"GPS Datum CAN\".
Depending on vehicle option variants, the positioning data is either sent from MOST to CAN (vehicles with navigation, Signal name includes MOST), or from CAN to MOST (vehicles with Telematics but no navigation, Signal name includes CAN).
MGU: The message contains the switching seconds.";
CM_ BO_ 1040  "Die Nachricht korrespondiert mit der Nachricht \"GPS Datum CAN\".
Je nach Verbauvariante des Fahrzeuges werden die Navi-Daten vom MOST in den CAN (Fahrzeug mit Navigation, Signalnamen enth�lt MOST) oder vom CAN in den MOST (Fahrzeug ohne Navigation, Signalnamen enth�lt CAN) gesendet.
Nachricht wird beim Aufstarten und anschlie�end bei jedem Wechsel beim Tag gesendet.
The message corresponds with the message \"GPS Datum CAN\".
Depending on vehicle option variants, the positioning data is either sent from MOST to CAN (vehicles with navigation, Signal name includes MOST), or from CAN to MOST (vehicles with Telematics but no navigation, Signal name includes CAN).
MGU: Die Botschaft enth�lt die Schaltsekunden.";
CM_ BO_ 2675460105  "Gliwa T1 Kommunikation von der T1 Host-SW zu dem DME1 SG
==========
Gliwa T1 communication from the T1 host software to the ECU DME1";
CM_ BO_ 2675460106  "Gliwa T1 Kommunikation von der DME1 zu der T1 Host-SW
==========
Gliwa T1 communication from the DME1 to the T1 host software";
CM_ BO_ 2675461120  "Gliwa T1 Kommunikation von der T1 Host-SW zu dem DME2 SG
==========
Gliwa T1 communication from the T1 host software to the ECU DME2";
CM_ BO_ 2675461121  "Gliwa T1 Kommunikation von der DME2 zu der T1 Host-SW
==========
Gliwa T1 communication from the DME2 to the T1 host software";
CM_ BO_ 1067  "Dieser Frame dient als Empfangsframe zur Aufnahme von Signalen vom AE_CAN_FD / AP_CAN_FD.
==========
This frame is used as a reception frame for recording signals from AE_CAN_FD / AP_CAN_FD.";

BA_DEF_ BO_ "FrameTriggeringName" STRING;
BA_DEF_ BO_ "GenMsgCycleTime" INT 0 65535;
BA_DEF_ BO_ "GenMsgDelayTime" INT 0 65535;
BA_DEF_ BO_ "GenMsgSendType" ENUM  "cyclicX","spontanX","cyclicIfActiveX","spontanWithDelay","cyclicAndSpontanX","cyclicAndSpontanWithDelay","spontanWithRepitition","cyclicIfActiveAndSpontanWD","cyclicIfActiveFast","cyclicWithRepeatOnDemand","none";
BA_DEF_ BO_ "GenMsgStartValue" STRING;
BA_DEF_ BO_ "PduName" STRING;
BA_DEF_ BO_ "SystemMessageLongSymbol" STRING;
BA_DEF_ SG_ "CompuMethodName" STRING;
BA_DEF_ SG_ "GenSigStartValue" FLOAT 0 100000000000;
BA_DEF_ SG_ "ISignalName" STRING;
BA_DEF_ SG_ "LongName" STRING;
BA_DEF_ SG_ "SysSignalName" STRING;
BA_DEF_ SG_ "SystemSignalLongSymbol" STRING;
BA_ "FrameTriggeringName" BO_ 644 "frTrig_CAN_963412151_644_963389585_963411732_963424759_FA_CAN";
BA_ "GenMsgCycleTime" BO_ 644 100;
BA_ "GenMsgSendType" BO_ 644 0;
BA_ "GenMsgStartValue" BO_ 644 "9ccff90000000000";
BA_ "PduName" BO_ 644 "DISP_SW_DRDY_S_2";
BA_ "FrameTriggeringName" BO_ 1062 "frTrig_CAN_963411787_1062_963402910_963411732_963424759_FA_CAN";
BA_ "GenMsgCycleTime" BO_ 1062 1000;
BA_ "GenMsgDelayTime" BO_ 1062 200;
BA_ "GenMsgSendType" BO_ 1062 4;
BA_ "GenMsgStartValue" BO_ 1062 "00000000";
BA_ "PduName" BO_ 1062 "DISP_SW_DRDY_TECGY_EXPI";
BA_ "FrameTriggeringName" BO_ 1080 "frTrig_CAN_963411836_1080_963398899_963411732_963424759_FA_CAN";
BA_ "GenMsgCycleTime" BO_ 1080 1000;
BA_ "GenMsgDelayTime" BO_ 1080 200;
BA_ "GenMsgSendType" BO_ 1080 4;
BA_ "GenMsgStartValue" BO_ 1080 "00000000";
BA_ "PduName" BO_ 1080 "DISP_SW_DRDY_TECGY_EXPI";
BA_ "FrameTriggeringName" BO_ 849 "frTrig_CAN_963411764_849_963391747_963411732_963424759_FA_CAN";
BA_ "GenMsgDelayTime" BO_ 849 100;
BA_ "GenMsgSendType" BO_ 849 1;
BA_ "GenMsgStartValue" BO_ 849 "0000000000dfff00";
BA_ "PduName" BO_ 849 "DT_BAT";
BA_ "FrameTriggeringName" BO_ 800 "frTrig_CAN_963411763_800_963396476_963411732_963424759_FA_CAN";
BA_ "GenMsgCycleTime" BO_ 800 5000;
BA_ "GenMsgDelayTime" BO_ 800 200;
BA_ "GenMsgSendType" BO_ 800 4;
BA_ "GenMsgStartValue" BO_ 800 "e7733e00000000";
BA_ "PduName" BO_ 800 "DT_BC_EL";
BA_ "FrameTriggeringName" BO_ 1021 "frTrig_CAN_963412165_1021_963405069_963411732_963424759_FA_CAN";
BA_ "GenMsgCycleTime" BO_ 1021 100;
BA_ "GenMsgDelayTime" BO_ 1021 50;
BA_ "GenMsgSendType" BO_ 1021 4;
BA_ "GenMsgStartValue" BO_ 1021 "0000000080";
BA_ "PduName" BO_ 1021 "DT_DISP_GRDT";
BA_ "FrameTriggeringName" BO_ 996 "frTrig_CAN_963411998_996_963396681_963411732_963424759_FA_CAN";
BA_ "GenMsgCycleTime" BO_ 996 10000;
BA_ "GenMsgDelayTime" BO_ 996 200;
BA_ "GenMsgSendType" BO_ 996 4;
BA_ "GenMsgStartValue" BO_ 996 "000000000000";
BA_ "PduName" BO_ 996 "DT_EL_GEY";
BA_ "FrameTriggeringName" BO_ 1042 "frTrig_CAN_963411909_1042_963403404_963411732_963424759_FA_CAN";
BA_ "GenMsgCycleTime" BO_ 1042 1000;
BA_ "GenMsgDelayTime" BO_ 1042 0;
BA_ "GenMsgSendType" BO_ 1042 4;
BA_ "GenMsgStartValue" BO_ 1042 "0000000000000000";
BA_ "PduName" BO_ 1042 "DT_EWS_1";
BA_ "FrameTriggeringName" BO_ 1043 "frTrig_CAN_963411808_1043_963398887_963411732_963424759_FA_CAN";
BA_ "GenMsgDelayTime" BO_ 1043 0;
BA_ "GenMsgSendType" BO_ 1043 1;
BA_ "GenMsgStartValue" BO_ 1043 "0000000000000000";
BA_ "PduName" BO_ 1043 "DT_EWS_2";
BA_ "FrameTriggeringName" BO_ 1044 "frTrig_CAN_963411918_1044_963399068_963411732_963424759_FA_CAN";
BA_ "GenMsgCycleTime" BO_ 1044 1000;
BA_ "GenMsgDelayTime" BO_ 1044 0;
BA_ "GenMsgSendType" BO_ 1044 4;
BA_ "GenMsgStartValue" BO_ 1044 "0000000000000000";
BA_ "PduName" BO_ 1044 "DT_EWS_7";
BA_ "FrameTriggeringName" BO_ 1045 "frTrig_CAN_963411775_1045_963398879_963411732_963424759_FA_CAN";
BA_ "GenMsgDelayTime" BO_ 1045 0;
BA_ "GenMsgSendType" BO_ 1045 1;
BA_ "GenMsgStartValue" BO_ 1045 "0000000000000000";
BA_ "PduName" BO_ 1045 "DT_EWS_8";
BA_ "FrameTriggeringName" BO_ 200 "frTrig_CAN_963411805_200_963395910_963411732_963424759_FA_CAN";
BA_ "GenMsgCycleTime" BO_ 200 1000;
BA_ "GenMsgDelayTime" BO_ 200 20;
BA_ "GenMsgSendType" BO_ 200 4;
BA_ "GenMsgStartValue" BO_ 200 "0000000000000000";
BA_ "PduName" BO_ 200 "DT_FN_HDC";
BA_ "FrameTriggeringName" BO_ 623 "frTrig_CAN_963412011_623_963405832_963411732_963424759_FA_CAN";
BA_ "GenMsgCycleTime" BO_ 623 60;
BA_ "GenMsgSendType" BO_ 623 0;
BA_ "GenMsgStartValue" BO_ 623 "006aaff60040ed00";
BA_ "PduName" BO_ 623 "DT_FRVEH";
BA_ "FrameTriggeringName" BO_ 624 "frTrig_CAN_963411895_624_963391931_963411732_963424759_FA_CAN";
BA_ "GenMsgCycleTime" BO_ 624 60;
BA_ "GenMsgSendType" BO_ 624 0;
BA_ "GenMsgStartValue" BO_ 624 "0000000000000000";
BA_ "PduName" BO_ 624 "DT_FRVEH_EXT";
BA_ "FrameTriggeringName" BO_ 1073 "frTrig_CAN_963411793_1073_963401073_963411732_963424759_FA_CAN";
BA_ "GenMsgCycleTime" BO_ 1073 200;
BA_ "GenMsgDelayTime" BO_ 1073 40;
BA_ "GenMsgSendType" BO_ 1073 4;
BA_ "GenMsgStartValue" BO_ 1073 "0000000000000000";
BA_ "PduName" BO_ 1073 "DT_HVSTO";
BA_ "FrameTriggeringName" BO_ 569 "frTrig_CAN_963412000_569_963391952_963411732_963424759_FA_CAN";
BA_ "GenMsgCycleTime" BO_ 569 200;
BA_ "GenMsgDelayTime" BO_ 569 40;
BA_ "GenMsgSendType" BO_ 569 4;
BA_ "GenMsgStartValue" BO_ 569 "0000000000000000";
BA_ "PduName" BO_ 569 "DT_HVSTO_2";
BA_ "FrameTriggeringName" BO_ 1046 "frTrig_CAN_963411923_1046_963394345_963411732_963424759_FA_CAN";
BA_ "GenMsgCycleTime" BO_ 1046 1000;
BA_ "GenMsgDelayTime" BO_ 1046 200;
BA_ "GenMsgSendType" BO_ 1046 4;
BA_ "GenMsgStartValue" BO_ 1046 "0000000000000000";
BA_ "PduName" BO_ 1046 "DT_KI";
BA_ "FrameTriggeringName" BO_ 1017 "frTrig_CAN_963411795_1017_963393645_963411732_963424759_FA_CAN";
BA_ "GenMsgCycleTime" BO_ 1017 1000;
BA_ "GenMsgDelayTime" BO_ 1017 10;
BA_ "GenMsgSendType" BO_ 1017 4;
BA_ "GenMsgStartValue" BO_ 1017 "0000000030300000";
BA_ "PduName" BO_ 1017 "DT_PT_2";
BA_ "FrameTriggeringName" BO_ 811 "frTrig_CAN_963411749_811_963391739_963411732_963424759_FA_CAN";
BA_ "GenMsgCycleTime" BO_ 811 200;
BA_ "GenMsgDelayTime" BO_ 811 100;
BA_ "GenMsgSendType" BO_ 811 4;
BA_ "GenMsgStartValue" BO_ 811 "0000000000000000";
BA_ "PduName" BO_ 811 "DT_RNG_CALC";
BA_ "FrameTriggeringName" BO_ 513 "frTrig_CAN_963412019_513_963401202_963411732_963424759_FA_CAN";
BA_ "GenMsgCycleTime" BO_ 513 250;
BA_ "GenMsgDelayTime" BO_ 513 50;
BA_ "GenMsgSendType" BO_ 513 4;
BA_ "GenMsgStartValue" BO_ 513 "0000000000000000";
BA_ "PduName" BO_ 513 "DT_RNG_CALC_2";
BA_ "FrameTriggeringName" BO_ 984 "frTrig_CAN_963412132_984_963391421_963411732_963424759_FA_CAN";
BA_ "GenMsgCycleTime" BO_ 984 1000;
BA_ "GenMsgDelayTime" BO_ 984 200;
BA_ "GenMsgSendType" BO_ 984 4;
BA_ "GenMsgStartValue" BO_ 984 "0000000000000000";
BA_ "PduName" BO_ 984 "DXP_MOD";
BA_ "FrameTriggeringName" BO_ 325 "frTrig_CAN_963411834_325_963405611_963411732_963424759_FA_CAN";
BA_ "GenMsgCycleTime" BO_ 325 200;
BA_ "GenMsgSendType" BO_ 325 0;
BA_ "GenMsgStartValue" BO_ 325 "000000";
BA_ "PduName" BO_ 325 "DisplayBoost";
BA_ "FrameTriggeringName" BO_ 668 "frTrig_CAN_963411945_668_963396563_963411732_963424759_FA_CAN";
BA_ "GenMsgCycleTime" BO_ 668 1000;
BA_ "GenMsgDelayTime" BO_ 668 100;
BA_ "GenMsgSendType" BO_ 668 4;
BA_ "GenMsgStartValue" BO_ 668 "0000000000000000";
BA_ "PduName" BO_ 668 "DisplayChargingStatus";
BA_ "FrameTriggeringName" BO_ 839 "frTrig_CAN_963411825_839_963391759_963411732_963424759_FA_CAN";
BA_ "GenMsgCycleTime" BO_ 839 1000;
BA_ "GenMsgDelayTime" BO_ 839 100;
BA_ "GenMsgSendType" BO_ 839 4;
BA_ "GenMsgStartValue" BO_ 839 "0000000000000000";
BA_ "PduName" BO_ 839 "DisplayChargingStatusNo2";
BA_ "FrameTriggeringName" BO_ 529 "frTrig_CAN_963412063_529_963405699_963411732_963424759_FA_CAN";
BA_ "GenMsgCycleTime" BO_ 529 2000;
BA_ "GenMsgDelayTime" BO_ 529 50;
BA_ "GenMsgSendType" BO_ 529 4;
BA_ "GenMsgStartValue" BO_ 529 "0000000080000080";
BA_ "PduName" BO_ 529 "DisplayCheckcontrolDFNS1";
BA_ "FrameTriggeringName" BO_ 576 "frTrig_CAN_963411985_576_963388974_963411732_963424759_FA_CAN";
BA_ "GenMsgCycleTime" BO_ 576 2000;
BA_ "GenMsgDelayTime" BO_ 576 60;
BA_ "GenMsgSendType" BO_ 576 4;
BA_ "GenMsgStartValue" BO_ 576 "0000000000";
BA_ "PduName" BO_ 576 "DisplayCheckcontrolSMBF";
BA_ "FrameTriggeringName" BO_ 587 "frTrig_CAN_963411799_587_963405160_963411732_963424759_FA_CAN";
BA_ "GenMsgCycleTime" BO_ 587 2000;
BA_ "GenMsgDelayTime" BO_ 587 60;
BA_ "GenMsgSendType" BO_ 587 4;
BA_ "GenMsgStartValue" BO_ 587 "0000000000";
BA_ "PduName" BO_ 587 "DisplayCheckcontrolSMBFH";
BA_ "FrameTriggeringName" BO_ 564 "frTrig_CAN_963412048_564_963398236_963411732_963424759_FA_CAN";
BA_ "GenMsgCycleTime" BO_ 564 2000;
BA_ "GenMsgDelayTime" BO_ 564 60;
BA_ "GenMsgSendType" BO_ 564 4;
BA_ "GenMsgStartValue" BO_ 564 "0000000000";
BA_ "PduName" BO_ 564 "DisplayCheckcontrolSMFA";
BA_ "FrameTriggeringName" BO_ 583 "frTrig_CAN_963412166_583_963398295_963411732_963424759_FA_CAN";
BA_ "GenMsgCycleTime" BO_ 583 2000;
BA_ "GenMsgDelayTime" BO_ 583 60;
BA_ "GenMsgSendType" BO_ 583 4;
BA_ "GenMsgStartValue" BO_ 583 "0000000000";
BA_ "PduName" BO_ 583 "DisplayCheckcontrolSMFAH";
BA_ "FrameTriggeringName" BO_ 1174 "frTrig_CAN_963412016_1174_963396356_963411732_963424759_FA_CAN";
BA_ "GenMsgCycleTime" BO_ 1174 5000;
BA_ "GenMsgDelayTime" BO_ 1174 500;
BA_ "GenMsgSendType" BO_ 1174 4;
BA_ "GenMsgStartValue" BO_ 1174 "00000000";
BA_ "PduName" BO_ 1174 "DisplayDataWaterInjection";
BA_ "FrameTriggeringName" BO_ 180 "frTrig_CAN_963411784_180_963402775_963411732_963424759_FA_CAN";
BA_ "GenMsgCycleTime" BO_ 180 1000;
BA_ "GenMsgDelayTime" BO_ 180 20;
BA_ "GenMsgSendType" BO_ 180 4;
BA_ "GenMsgStartValue" BO_ 180 "00000000";
BA_ "PduName" BO_ 180 "ECU_DOM_CHAS";
BA_ "FrameTriggeringName" BO_ 182 "frTrig_CAN_963411823_182_963398386_963411732_963424759_FA_CAN";
BA_ "GenMsgCycleTime" BO_ 182 1000;
BA_ "GenMsgDelayTime" BO_ 182 20;
BA_ "GenMsgSendType" BO_ 182 4;
BA_ "GenMsgStartValue" BO_ 182 "0000000000000000";
BA_ "PduName" BO_ 182 "ECU_DOM_ENTAI";
BA_ "FrameTriggeringName" BO_ 806 "frTrig_CAN_963412034_806_963396689_963411732_963424759_FA_CAN";
BA_ "GenMsgSendType" BO_ 806 1;
BA_ "GenMsgStartValue" BO_ 806 "0000000000000000";
BA_ "PduName" BO_ 806 "EFFY_INFO_DT";
BA_ "FrameTriggeringName" BO_ 759 "frTrig_CAN_963412071_759_963389004_963411732_963424759_FA_CAN";
BA_ "GenMsgCycleTime" BO_ 759 1000;
BA_ "GenMsgDelayTime" BO_ 759 100;
BA_ "GenMsgSendType" BO_ 759 4;
BA_ "GenMsgStartValue" BO_ 759 "000000000000";
BA_ "PduName" BO_ 759 "EINHEITEN_BN2020";
BA_ "FrameTriggeringName" BO_ 589 "frTrig_CAN_963411956_589_963395934_963411732_963424759_FA_CAN";
BA_ "GenMsgCycleTime" BO_ 589 5000;
BA_ "GenMsgDelayTime" BO_ 589 10;
BA_ "GenMsgSendType" BO_ 589 4;
BA_ "GenMsgStartValue" BO_ 589 "0000";
BA_ "PduName" BO_ 589 "ERRM_BN_U";
BA_ "FrameTriggeringName" BO_ 139 "frTrig_CAN_963411959_139_963405816_963411732_963424759_FA_CAN";
BA_ "GenMsgDelayTime" BO_ 139 10;
BA_ "GenMsgSendType" BO_ 139 1;
BA_ "GenMsgStartValue" BO_ 139 "0000000000000000";
BA_ "PduName" BO_ 139 "EWSGetriebe";
BA_ "FrameTriggeringName" BO_ 135 "frTrig_CAN_963411883_135_963405807_963411732_963424759_FA_CAN";
BA_ "GenMsgDelayTime" BO_ 135 10;
BA_ "GenMsgSendType" BO_ 135 1;
BA_ "GenMsgStartValue" BO_ 135 "0000000000000000";
BA_ "PduName" BO_ 135 "EWSGetriebeAntwort";
BA_ "FrameTriggeringName" BO_ 224 "frTrig_CAN_963411854_224_963403231_963411732_963424759_FA_CAN";
BA_ "GenMsgDelayTime" BO_ 224 10;
BA_ "GenMsgSendType" BO_ 224 1;
BA_ "GenMsgStartValue" BO_ 224 "0000000000000000";
BA_ "PduName" BO_ 224 "EWSInverter48";
BA_ "FrameTriggeringName" BO_ 253 "frTrig_CAN_963412102_253_963401221_963411732_963424759_FA_CAN";
BA_ "GenMsgDelayTime" BO_ 253 10;
BA_ "GenMsgSendType" BO_ 253 1;
BA_ "GenMsgStartValue" BO_ 253 "0000000000000000";
BA_ "PduName" BO_ 253 "EWSInverter48Answer";
BA_ "FrameTriggeringName" BO_ 140 "frTrig_CAN_963412042_140_963405840_963411732_963424759_FA_CAN";
BA_ "GenMsgDelayTime" BO_ 140 10;
BA_ "GenMsgSendType" BO_ 140 1;
BA_ "GenMsgStartValue" BO_ 140 "0000000000000000";
BA_ "PduName" BO_ 140 "EWSMotor1";
BA_ "FrameTriggeringName" BO_ 144 "frTrig_CAN_963411894_144_963403396_963411732_963424759_FA_CAN";
BA_ "GenMsgDelayTime" BO_ 144 10;
BA_ "GenMsgSendType" BO_ 144 1;
BA_ "GenMsgStartValue" BO_ 144 "0000000000000000";
BA_ "PduName" BO_ 144 "EWSMotor1Antwort";
BA_ "FrameTriggeringName" BO_ 162 "frTrig_CAN_963412079_162_963403431_963411732_963424759_FA_CAN";
BA_ "GenMsgDelayTime" BO_ 162 10;
BA_ "GenMsgSendType" BO_ 162 1;
BA_ "GenMsgStartValue" BO_ 162 "0000000000000000";
BA_ "PduName" BO_ 162 "EWSMotor2";
BA_ "FrameTriggeringName" BO_ 163 "frTrig_CAN_963412148_163_963399101_963411732_963424759_FA_CAN";
BA_ "GenMsgDelayTime" BO_ 163 10;
BA_ "GenMsgSendType" BO_ 163 1;
BA_ "GenMsgStartValue" BO_ 163 "0000000000000000";
BA_ "PduName" BO_ 163 "EWSMotor2Antwort";
BA_ "FrameTriggeringName" BO_ 148 "frTrig_CAN_963411819_148_963405605_963411732_963424759_FA_CAN";
BA_ "GenMsgCycleTime" BO_ 148 1000;
BA_ "GenMsgDelayTime" BO_ 148 10;
BA_ "GenMsgSendType" BO_ 148 4;
BA_ "GenMsgStartValue" BO_ 148 "0000000000000000";
BA_ "PduName" BO_ 148 "EWS_GLB";
BA_ "FrameTriggeringName" BO_ 896 "frTrig_CAN_963411880_896_963388979_963411732_963424759_FA_CAN";
BA_ "GenMsgDelayTime" BO_ 896 100;
BA_ "GenMsgSendType" BO_ 896 1;
BA_ "GenMsgStartValue" BO_ 896 "00000000000000";
BA_ "PduName" BO_ 896 "FAHRGESTELLNUMMER";
BA_ "FrameTriggeringName" BO_ 904 "frTrig_CAN_963411902_904_963395906_963411732_963424759_FA_CAN";
BA_ "GenMsgDelayTime" BO_ 904 100;
BA_ "GenMsgSendType" BO_ 904 1;
BA_ "GenMsgStartValue" BO_ 904 "00000000000000";
BA_ "PduName" BO_ 904 "FAHRZEUGTYP";
BA_ "FrameTriggeringName" BO_ 1103 "frTrig_CAN_963412026_1103_963389535_963411732_963424759_FA_CAN";
BA_ "GenMsgCycleTime" BO_ 1103 10000;
BA_ "GenMsgDelayTime" BO_ 1103 200;
BA_ "GenMsgSendType" BO_ 1103 4;
BA_ "GenMsgStartValue" BO_ 1103 "0100010000000000";
BA_ "PduName" BO_ 1103 "FEPM_RLS_FLLUP_RSU";
BA_ "FrameTriggeringName" BO_ 1102 "frTrig_CAN_963411951_1102_963396637_963411732_963424759_FA_CAN";
BA_ "GenMsgCycleTime" BO_ 1102 10000;
BA_ "GenMsgDelayTime" BO_ 1102 200;
BA_ "GenMsgSendType" BO_ 1102 4;
BA_ "GenMsgStartValue" BO_ 1102 "01000000";
BA_ "PduName" BO_ 1102 "FEPM_RQ_FLLUP_RSU";
BA_ "FrameTriggeringName" BO_ 958 "frTrig_CAN_963411990_958_963391127_963411732_963424759_FA_CAN";
BA_ "GenMsgCycleTime" BO_ 958 10000;
BA_ "GenMsgDelayTime" BO_ 958 100;
BA_ "GenMsgSendType" BO_ 958 4;
BA_ "GenMsgStartValue" BO_ 958 "000000";
BA_ "PduName" BO_ 958 "FLLUPT_GPWSUP";
BA_ "FrameTriggeringName" BO_ 940 "frTrig_CAN_963412138_940_963402613_963411732_963424759_FA_CAN";
BA_ "GenMsgCycleTime" BO_ 940 10000;
BA_ "GenMsgDelayTime" BO_ 940 100;
BA_ "GenMsgSendType" BO_ 940 4;
BA_ "GenMsgStartValue" BO_ 940 "0000";
BA_ "PduName" BO_ 940 "FLLUPT_KLEMME_30G_F";
BA_ "FrameTriggeringName" BO_ 586 "frTrig_CAN_963412116_586_963391810_963411732_963424759_FA_CAN";
BA_ "GenMsgCycleTime" BO_ 586 500;
BA_ "GenMsgDelayTime" BO_ 586 50;
BA_ "GenMsgSendType" BO_ 586 4;
BA_ "GenMsgStartValue" BO_ 586 "0000000000000000";
BA_ "PduName" BO_ 586 "FRC_COUP_RNG_AIC_2";
BA_ "FrameTriggeringName" BO_ 970 "frTrig_CAN_963411843_970_963396502_963411732_963424759_FA_CAN";
BA_ "GenMsgCycleTime" BO_ 970 1000;
BA_ "GenMsgDelayTime" BO_ 970 50;
BA_ "GenMsgSendType" BO_ 970 4;
BA_ "GenMsgStartValue" BO_ 970 "0000000000000000";
BA_ "PduName" BO_ 970 "FRC_RD_INFO";
BA_ "FrameTriggeringName" BO_ 967 "frTrig_CAN_963411779_967_963389413_963411732_963424759_FA_CAN";
BA_ "GenMsgDelayTime" BO_ 967 200;
BA_ "GenMsgSendType" BO_ 967 1;
BA_ "GenMsgStartValue" BO_ 967 "0000000000000000";
BA_ "PduName" BO_ 967 "FRC_RT_DSTN";
BA_ "FrameTriggeringName" BO_ 250 "frTrig_CAN_963411938_250_963391939_963411732_963424759_FA_CAN";
BA_ "GenMsgSendType" BO_ 250 1;
BA_ "GenMsgStartValue" BO_ 250 "0000000000000000";
BA_ "PduName" BO_ 250 "FRSG_STREET";
BA_ "FrameTriggeringName" BO_ 928 "frTrig_CAN_963411877_928_963402627_963411732_963424759_FA_CAN";
BA_ "GenMsgCycleTime" BO_ 928 5000;
BA_ "GenMsgDelayTime" BO_ 928 100;
BA_ "GenMsgSendType" BO_ 928 4;
BA_ "GenMsgStartValue" BO_ 928 "0000000000000000";
BA_ "PduName" BO_ 928 "FZZSTD";
BA_ "FrameTriggeringName" BO_ 620 "frTrig_CAN_963411966_620_963405820_963411732_963424759_FA_CAN";
BA_ "GenMsgCycleTime" BO_ 620 400;
BA_ "GenMsgSendType" BO_ 620 0;
BA_ "GenMsgStartValue" BO_ 620 "0000000000000000";
BA_ "PduName" BO_ 620 "GO_PY_AVAI";
BA_ "FrameTriggeringName" BO_ 1039 "frTrig_CAN_963411994_1039_963401194_963411732_963424759_FA_CAN";
BA_ "GenMsgDelayTime" BO_ 1039 1000;
BA_ "GenMsgSendType" BO_ 1039 1;
BA_ "GenMsgStartValue" BO_ 1039 "00000000";
BA_ "PduName" BO_ 1039 "GPS_CTI_CAN";
BA_ "FrameTriggeringName" BO_ 1111 "frTrig_CAN_963412010_1111_963405827_963411732_963424759_FA_CAN";
BA_ "GenMsgDelayTime" BO_ 1111 1000;
BA_ "GenMsgSendType" BO_ 1111 1;
BA_ "GenMsgStartValue" BO_ 1111 "00000000";
BA_ "PduName" BO_ 1111 "GPS_CTI_MOST";
BA_ "FrameTriggeringName" BO_ 1041 "frTrig_CAN_963411838_1041_963394169_963411732_963424759_FA_CAN";
BA_ "GenMsgDelayTime" BO_ 1041 1000;
BA_ "GenMsgSendType" BO_ 1041 1;
BA_ "GenMsgStartValue" BO_ 1041 "00000000";
BA_ "PduName" BO_ 1041 "GPS_CTI_MOST";
BA_ "FrameTriggeringName" BO_ 1038 "frTrig_CAN_963411865_1038_963405623_963411732_963424759_FA_CAN";
BA_ "GenMsgCycleTime" BO_ 1038 600000;
BA_ "GenMsgDelayTime" BO_ 1038 1000;
BA_ "GenMsgSendType" BO_ 1038 4;
BA_ "GenMsgStartValue" BO_ 1038 "0000000000";
BA_ "PduName" BO_ 1038 "GPS_DATE_CAN";
BA_ "FrameTriggeringName" BO_ 1110 "frTrig_CAN_963412037_1110_963394204_963411732_963424759_FA_CAN";
BA_ "GenMsgDelayTime" BO_ 1110 1000;
BA_ "GenMsgSendType" BO_ 1110 1;
BA_ "GenMsgStartValue" BO_ 1110 "0000000000";
BA_ "PduName" BO_ 1110 "GPS_DATE_MOST";
BA_ "FrameTriggeringName" BO_ 1040 "frTrig_CAN_963411837_1040_963405615_963411732_963424759_FA_CAN";
BA_ "GenMsgDelayTime" BO_ 1040 1000;
BA_ "GenMsgSendType" BO_ 1040 1;
BA_ "GenMsgStartValue" BO_ 1040 "0000000000";
BA_ "PduName" BO_ 1040 "GPS_DATE_MOST";
BA_ "FrameTriggeringName" BO_ 2675460105 "frTrig_CAN_963412117_527976457_963391968_963411732_963424759_FA_CAN";
BA_ "GenMsgDelayTime" BO_ 2675460105 10;
BA_ "GenMsgSendType" BO_ 2675460105 1;
BA_ "GenMsgStartValue" BO_ 2675460105 "0000000000000000";
BA_ "PduName" BO_ 2675460105 "GliwaT1DME1HostTx";
BA_ "FrameTriggeringName" BO_ 2675460106 "frTrig_CAN_963412118_527976458_963396708_963411732_963424759_FA_CAN";
BA_ "GenMsgDelayTime" BO_ 2675460106 10;
BA_ "GenMsgSendType" BO_ 2675460106 1;
BA_ "GenMsgStartValue" BO_ 2675460106 "0000000000000000";
BA_ "PduName" BO_ 2675460106 "GliwaT1DME1Tx";
BA_ "FrameTriggeringName" BO_ 2675461120 "frTrig_CAN_963412119_527977472_963396713_963411732_963424759_FA_CAN";
BA_ "GenMsgDelayTime" BO_ 2675461120 10;
BA_ "GenMsgSendType" BO_ 2675461120 1;
BA_ "GenMsgStartValue" BO_ 2675461120 "0000000000000000";
BA_ "PduName" BO_ 2675461120 "GliwaT1DME2HostTx";
BA_ "FrameTriggeringName" BO_ 2675461121 "frTrig_CAN_963412120_527977473_963396718_963411732_963424759_FA_CAN";
BA_ "GenMsgDelayTime" BO_ 2675461121 10;
BA_ "GenMsgSendType" BO_ 2675461121 1;
BA_ "GenMsgStartValue" BO_ 2675461121 "0000000000000000";
BA_ "PduName" BO_ 2675461121 "GliwaT1DME2Tx";
BA_ "FrameTriggeringName" BO_ 207 "frTrig_CAN_963412020_207_963396624_963411732_963424759_FA_CAN";
BA_ "GenMsgCycleTime" BO_ 207 320;
BA_ "GenMsgDelayTime" BO_ 207 20;
BA_ "GenMsgSendType" BO_ 207 4;
BA_ "GenMsgStartValue" BO_ 207 "0000000000000000";
BA_ "PduName" BO_ 207 "HDWOBS_FCM";
BA_ "FrameTriggeringName" BO_ 441 "frTrig_CAN_963412168_441_963394200_963411732_963424759_FA_CAN";
BA_ "GenMsgCycleTime" BO_ 441 1000;
BA_ "GenMsgDelayTime" BO_ 441 50;
BA_ "GenMsgSendType" BO_ 441 4;
BA_ "GenMsgStartValue" BO_ 441 "0000000000000000";
BA_ "PduName" BO_ 441 "HT_MGT_ENG_CTR";
BA_ "FrameTriggeringName" BO_ 1067 "frTrig_CAN_963411978_1067_963391795_963411732_963424759_FA_CAN";
BA_ "GenMsgSendType" BO_ 1067 1;
BA_ "GenMsgStartValue" BO_ 1067 "ceffceff";
BA_ "PduName" BO_ 1067 "HighVoltageStorageInfoToExternal";
BA_ "FrameTriggeringName" BO_ 633 "frTrig_CAN_963411851_633_963405620_963411732_963424759_FA_CAN";
BA_ "GenMsgCycleTime" BO_ 633 1000;
BA_ "GenMsgDelayTime" BO_ 633 100;
BA_ "GenMsgSendType" BO_ 633 4;
BA_ "GenMsgStartValue" BO_ 633 "0000000000000000";
BA_ "PduName" BO_ 633 "INFO_CHGWIN";
BA_ "CompuMethodName" SG_ 644 DISP_ACLNY "DISP_ACLNY_ACLNX";
BA_ "GenSigStartValue" SG_ 644 DISP_ACLNY -100;
BA_ "ISignalName" SG_ 644 DISP_ACLNY "DISP_ACLNY";
BA_ "LongName" SG_ 644 DISP_ACLNY "Anzeige_Querbeschleunigung";
BA_ "SysSignalName" SG_ 644 DISP_ACLNY "DISP_ACLNY";
BA_ "CompuMethodName" SG_ 644 DISP_ACLNX "DISP_ACLNY_ACLNX";
BA_ "GenSigStartValue" SG_ 644 DISP_ACLNX -100;
BA_ "ISignalName" SG_ 644 DISP_ACLNX "DISP_ACLNX";
BA_ "LongName" SG_ 644 DISP_ACLNX "Anzeige_Längsbeschleunigung";
BA_ "SysSignalName" SG_ 644 DISP_ACLNX "DISP_ACLNX";
BA_ "CompuMethodName" SG_ 644 DISP_MAXV_BSTP "DISP_MAXV_BSTP";
BA_ "ISignalName" SG_ 644 DISP_MAXV_BSTP "DISP_MAXV_BSTP";
BA_ "LongName" SG_ 644 DISP_MAXV_BSTP "Anzeige_Maximalwert_Ladedruck";
BA_ "SysSignalName" SG_ 644 DISP_MAXV_BSTP "DISP_MAXV_BSTP";
BA_ "CompuMethodName" SG_ 644 DISP_BSTP "DISP_BSTP";
BA_ "ISignalName" SG_ 644 DISP_BSTP "DISP_BSTP";
BA_ "LongName" SG_ 644 DISP_BSTP "Anzeige_Ladedruck";
BA_ "SysSignalName" SG_ 644 DISP_BSTP "DISP_BSTP";
BA_ "CompuMethodName" SG_ 644 ReasonDegradationPowertrain "ReasonDegradationPowertrain";
BA_ "ISignalName" SG_ 644 ReasonDegradationPowertrain "ReasonDegradationPowertrain";
BA_ "LongName" SG_ 644 ReasonDegradationPowertrain "ReasonDegradationPowertrain";
BA_ "SysSignalName" SG_ 644 ReasonDegradationPowertrain "ReasonDegradationPowertrain";
BA_ "CompuMethodName" SG_ 1062 ST_SAIL_DRV "ST_SAIL";
BA_ "ISignalName" SG_ 1062 ST_SAIL_DRV "ST_SAIL_DRV";
BA_ "LongName" SG_ 1062 ST_SAIL_DRV "Status_Segeln_Antrieb";
BA_ "SysSignalName" SG_ 1062 ST_SAIL_DRV "ST_SAIL_DRV";
BA_ "CompuMethodName" SG_ 1080 ST_SAIL_DRV "ST_SAIL";
BA_ "ISignalName" SG_ 1080 ST_SAIL_DRV "ST_SAIL_DRV";
BA_ "LongName" SG_ 1080 ST_SAIL_DRV "Status_Segeln_Antrieb";
BA_ "SysSignalName" SG_ 1080 ST_SAIL_DRV "ST_SAIL_DRV";
BA_ "CompuMethodName" SG_ 849 AVL_CON_BT "AVL_CON_BT";
BA_ "ISignalName" SG_ 849 AVL_CON_BT "AVL_CON_BT";
BA_ "LongName" SG_ 849 AVL_CON_BT "Ist_Zustand_Batterie";
BA_ "SysSignalName" SG_ 849 AVL_CON_BT "AVL_CON_BT";
BA_ "CompuMethodName" SG_ 849 ST_CHG_BT "ST_CHG_BT";
BA_ "ISignalName" SG_ 849 ST_CHG_BT "ST_CHG_BT";
BA_ "LongName" SG_ 849 ST_CHG_BT "Status_Ladung_Batterie";
BA_ "SysSignalName" SG_ 849 ST_CHG_BT "ST_CHG_BT";
BA_ "CompuMethodName" SG_ 849 ST_BT_WNG "ST_BT_WNG";
BA_ "ISignalName" SG_ 849 ST_BT_WNG "ST_BT_WNG";
BA_ "LongName" SG_ 849 ST_BT_WNG "Status_Batterie_Falsch";
BA_ "SysSignalName" SG_ 849 ST_BT_WNG "ST_BT_WNG";
BA_ "CompuMethodName" SG_ 849 ST_CEDT "ST_CEDT";
BA_ "ISignalName" SG_ 849 ST_CEDT "ST_CEDT";
BA_ "LongName" SG_ 849 ST_CEDT "Status_Zelldefekt";
BA_ "SysSignalName" SG_ 849 ST_CEDT "ST_CEDT";
BA_ "CompuMethodName" SG_ 849 QUAL_CON_BT_CAPE_AVL "QUAL_CON_BT_CAPE_AVL";
BA_ "ISignalName" SG_ 849 QUAL_CON_BT_CAPE_AVL "QUAL_CON_BT_CAPE_AVL";
BA_ "LongName" SG_ 849 QUAL_CON_BT_CAPE_AVL "Qualität_Zustand_Batterie_Kapazität_Ist";
BA_ "SysSignalName" SG_ 849 QUAL_CON_BT_CAPE_AVL "QUAL_CON_BT_CAPE_AVL";
BA_ "CompuMethodName" SG_ 849 QUAL_CON_BT_CHGCOND "QUAL_CON_BT_CHGCOND";
BA_ "ISignalName" SG_ 849 QUAL_CON_BT_CHGCOND "QUAL_CON_BT_CHGCOND";
BA_ "LongName" SG_ 849 QUAL_CON_BT_CHGCOND "Qualität_Zustand_Batterie_Ladezustand";
BA_ "SysSignalName" SG_ 849 QUAL_CON_BT_CHGCOND "QUAL_CON_BT_CHGCOND";
BA_ "CompuMethodName" SG_ 849 ST_LSS_WTR "ST_LSS_WTR";
BA_ "ISignalName" SG_ 849 ST_LSS_WTR "ST_LSS_WTR";
BA_ "LongName" SG_ 849 ST_LSS_WTR "Status_Verlust_Wasser";
BA_ "SysSignalName" SG_ 849 ST_LSS_WTR "ST_LSS_WTR";
BA_ "CompuMethodName" SG_ 849 ST_EXHDCHG "ST_EXHDCHG";
BA_ "ISignalName" SG_ 849 ST_EXHDCHG "ST_EXHDCHG";
BA_ "LongName" SG_ 849 ST_EXHDCHG "Status_Tiefentladung";
BA_ "SysSignalName" SG_ 849 ST_EXHDCHG "ST_EXHDCHG";
BA_ "CompuMethodName" SG_ 849 CON_BT_CAPE_AVL "CON_BT_CAPE_AVL";
BA_ "ISignalName" SG_ 849 CON_BT_CAPE_AVL "CON_BT_CAPE_AVL";
BA_ "LongName" SG_ 849 CON_BT_CAPE_AVL "Zustand_Batterie_Kapazität_Ist";
BA_ "SysSignalName" SG_ 849 CON_BT_CAPE_AVL "CON_BT_CAPE_AVL";
BA_ "CompuMethodName" SG_ 849 CON_BT_CHGCOND "CON_BT_CHGCOND";
BA_ "ISignalName" SG_ 849 CON_BT_CHGCOND "CON_BT_CHGCOND";
BA_ "LongName" SG_ 849 CON_BT_CHGCOND "Zustand_Batterie_Ladezustand";
BA_ "SysSignalName" SG_ 849 CON_BT_CHGCOND "CON_BT_CHGCOND";
BA_ "CompuMethodName" SG_ 849 QUAN_ALT_BT "QUAN_ALT_BT";
BA_ "ISignalName" SG_ 849 QUAN_ALT_BT "QUAN_ALT_BT";
BA_ "LongName" SG_ 849 QUAN_ALT_BT "Anzahl_Wechsel_Batterie";
BA_ "SysSignalName" SG_ 849 QUAN_ALT_BT "QUAN_ALT_BT";
BA_ "CompuMethodName" SG_ 849 LVBT_PDCHG "LVBT_PDCHG";
BA_ "GenSigStartValue" SG_ 849 LVBT_PDCHG -33;
BA_ "ISignalName" SG_ 849 LVBT_PDCHG "LVBT_PDCHG";
BA_ "LongName" SG_ 849 LVBT_PDCHG "Niedervoltbatterie_Standentladung";
BA_ "SysSignalName" SG_ 849 LVBT_PDCHG "LVBT_PDCHG";
BA_ "CompuMethodName" SG_ 800 COSP_AVR_EL_BC_1 "COSP_AVR_EL_BC_1";
BA_ "GenSigStartValue" SG_ 800 COSP_AVR_EL_BC_1 999;
BA_ "ISignalName" SG_ 800 COSP_AVR_EL_BC_1 "COSP_AVR_EL_BC_1";
BA_ "LongName" SG_ 800 COSP_AVR_EL_BC_1 "Verbrauch_Durchschnitt_Elektrisch_BC_1";
BA_ "SysSignalName" SG_ 800 COSP_AVR_EL_BC_1 "COSP_AVR_EL_BC_1";
BA_ "CompuMethodName" SG_ 800 COSP_AVR_EL_BC_2 "COSP_AVR_EL_BC_2";
BA_ "GenSigStartValue" SG_ 800 COSP_AVR_EL_BC_2 999;
BA_ "ISignalName" SG_ 800 COSP_AVR_EL_BC_2 "COSP_AVR_EL_BC_2";
BA_ "LongName" SG_ 800 COSP_AVR_EL_BC_2 "Verbrauch_Durchschnitt_Elektrisch_BC_2";
BA_ "SysSignalName" SG_ 800 COSP_AVR_EL_BC_2 "COSP_AVR_EL_BC_2";
BA_ "CompuMethodName" SG_ 800 ST_UN_COSP_EL_BC "ST_UN_COSP_EL_BC";
BA_ "ISignalName" SG_ 800 ST_UN_COSP_EL_BC "ST_UN_COSP_EL_BC";
BA_ "LongName" SG_ 800 ST_UN_COSP_EL_BC "Status_Einheit_Verbrauch_Elektrisch_BC";
BA_ "SysSignalName" SG_ 800 ST_UN_COSP_EL_BC "ST_UN_COSP_EL_BC";
BA_ "CompuMethodName" SG_ 800 COPO_VL_BC "COPO_VL_BC";
BA_ "ISignalName" SG_ 800 COPO_VL_BC "COPO_VL_BC";
BA_ "LongName" SG_ 800 COPO_VL_BC "Kommaposition_Wert_BC";
BA_ "SysSignalName" SG_ 800 COPO_VL_BC "COPO_VL_BC";
BA_ "CompuMethodName" SG_ 1021 CRC_DT_DISP_GRDT "CRC8";
BA_ "ISignalName" SG_ 1021 CRC_DT_DISP_GRDT "CRC_DT_DISP_GRDT";
BA_ "LongName" SG_ 1021 CRC_DT_DISP_GRDT "CRC_data_display_gearbox-drive-train";
BA_ "SysSignalName" SG_ 1021 CRC_DT_DISP_GRDT "CRC_DT_DISP_GRDT";
BA_ "CompuMethodName" SG_ 1021 ALIV_DT_DISP_GRDT "Aliv_4";
BA_ "ISignalName" SG_ 1021 ALIV_DT_DISP_GRDT "ALIV_DT_DISP_GRDT";
BA_ "LongName" SG_ 1021 ALIV_DT_DISP_GRDT "Alive_Daten_Anzeige_Getriebestrang";
BA_ "SysSignalName" SG_ 1021 ALIV_DT_DISP_GRDT "ALIV_DT_DISP_GRDT";
BA_ "CompuMethodName" SG_ 1021 DISP_GR_GRB "DISP_GR";
BA_ "ISignalName" SG_ 1021 DISP_GR_GRB "DISP_GR_GRB";
BA_ "LongName" SG_ 1021 DISP_GR_GRB "Anzeige_Gang_Getriebe";
BA_ "SysSignalName" SG_ 1021 DISP_GR_GRB "DISP_GR_GRB";
BA_ "CompuMethodName" SG_ 1021 DISP_PRG_GRB "DISP_PRG_GRB";
BA_ "ISignalName" SG_ 1021 DISP_PRG_GRB "DISP_PRG_GRB";
BA_ "LongName" SG_ 1021 DISP_PRG_GRB "Anzeige_Programm_Getriebe";
BA_ "SysSignalName" SG_ 1021 DISP_PRG_GRB "DISP_PRG_GRB";
BA_ "CompuMethodName" SG_ 1021 DISP_PO_IDC_GRB "DISP_IDC_GRB";
BA_ "ISignalName" SG_ 1021 DISP_PO_IDC_GRB "DISP_PO_IDC_GRB";
BA_ "LongName" SG_ 1021 DISP_PO_IDC_GRB "Anzeige_Position_Blinken_Getriebe";
BA_ "SysSignalName" SG_ 1021 DISP_PO_IDC_GRB "DISP_PO_IDC_GRB";
BA_ "CompuMethodName" SG_ 1021 DISP_PO_GRB "DISP_PO_GRB";
BA_ "ISignalName" SG_ 1021 DISP_PO_GRB "DISP_PO_GRB";
BA_ "LongName" SG_ 1021 DISP_PO_GRB "Anzeige_Position_Getriebe";
BA_ "SysSignalName" SG_ 1021 DISP_PO_GRB "DISP_PO_GRB";
BA_ "CompuMethodName" SG_ 1021 DISP_SSC_IDC_GRB "DISP_IDC_GRB";
BA_ "ISignalName" SG_ 1021 DISP_SSC_IDC_GRB "DISP_SSC_IDC_GRB";
BA_ "LongName" SG_ 1021 DISP_SSC_IDC_GRB "Anzeige_Schaltschema_Blinken_Getriebe";
BA_ "SysSignalName" SG_ 1021 DISP_SSC_IDC_GRB "DISP_SSC_IDC_GRB";
BA_ "CompuMethodName" SG_ 1021 GEN_IDLI "IDLI_GEN";
BA_ "ISignalName" SG_ 1021 GEN_IDLI "GEN_IDLI";
BA_ "LongName" SG_ 1021 GEN_IDLI "Generator_Kontrolleuchte";
BA_ "SysSignalName" SG_ 1021 GEN_IDLI "GEN_IDLI";
BA_ "CompuMethodName" SG_ 1021 DISP_RQ_GR_GRB "DISP_RQ_GR_GRB";
BA_ "ISignalName" SG_ 1021 DISP_RQ_GR_GRB "DISP_RQ_GR_GRB";
BA_ "LongName" SG_ 1021 DISP_RQ_GR_GRB "Anzeige_Anforderung_Gang_Getriebe";
BA_ "SysSignalName" SG_ 1021 DISP_RQ_GR_GRB "DISP_RQ_GR_GRB";
BA_ "CompuMethodName" SG_ 1021 DISP_DRVLG_GRB "DISP_DRVLG_GRB";
BA_ "ISignalName" SG_ 1021 DISP_DRVLG_GRB "DISP_DRVLG_GRB";
BA_ "LongName" SG_ 1021 DISP_DRVLG_GRB "Anzeige_Drive-Logic_Getriebe";
BA_ "SysSignalName" SG_ 1021 DISP_DRVLG_GRB "DISP_DRVLG_GRB";
BA_ "CompuMethodName" SG_ 1021 StatusAvailabilityInterventionPo "StatusAvailabilityInterventionPowertrainGearbox";
BA_ "ISignalName" SG_ 1021 StatusAvailabilityInterventionPo "StatusAvailabilityInterventionPowertrainGearbox";
BA_ "LongName" SG_ 1021 StatusAvailabilityInterventionPo "StatusAvailabilityInterventionPowertrainGearbox";
BA_ "SysSignalName" SG_ 1021 StatusAvailabilityInterventionPo "StatusAvailabilityInterventionPowertrainGearbox";
BA_ "SystemSignalLongSymbol" SG_ 1021 StatusAvailabilityInterventionPo "StatusAvailabilityInterventionPowertrainGearbox";
BA_ "ISignalName" SG_ 1021 DT_DISP_GRDT_dummy_38_39 "DT_DISP_GRDT_dummy_38_39";
BA_ "LongName" SG_ 1021 DT_DISP_GRDT_dummy_38_39 "DT_DISP_GRDT_dummy_38_39";
BA_ "SysSignalName" SG_ 1021 DT_DISP_GRDT_dummy_38_39 "DT_DISP_GRDT_dummy_38_39";
BA_ "CompuMethodName" SG_ 996 AVL_PWR_EL_GEY "AVL_PWR_EL_GEY";
BA_ "ISignalName" SG_ 996 AVL_PWR_EL_GEY "AVL_PWR_EL_GEY";
BA_ "LongName" SG_ 996 AVL_PWR_EL_GEY "Ist_Leistung_Elektrisch_Durchlauferhitzer";
BA_ "SysSignalName" SG_ 996 AVL_PWR_EL_GEY "AVL_PWR_EL_GEY";
BA_ "CompuMethodName" SG_ 996 AVL_I_EL_GEY "AVL_I_EL_GEY";
BA_ "ISignalName" SG_ 996 AVL_I_EL_GEY "AVL_I_EL_GEY";
BA_ "LongName" SG_ 996 AVL_I_EL_GEY "Ist_Strom_Elektrisch_Durchlauferhitzer";
BA_ "SysSignalName" SG_ 996 AVL_I_EL_GEY "AVL_I_EL_GEY";
BA_ "CompuMethodName" SG_ 1042 EWS_COMM_1_1 "EWS_COMM";
BA_ "ISignalName" SG_ 1042 EWS_COMM_1_1 "EWS_COMM_1_1";
BA_ "LongName" SG_ 1042 EWS_COMM_1_1 "EWS_Kommunikation_1_1";
BA_ "SysSignalName" SG_ 1042 EWS_COMM_1_1 "EWS_COMM_1_1";
BA_ "CompuMethodName" SG_ 1042 EWS_COMM_1_2 "EWS_COMM";
BA_ "ISignalName" SG_ 1042 EWS_COMM_1_2 "EWS_COMM_1_2";
BA_ "LongName" SG_ 1042 EWS_COMM_1_2 "EWS_Kommunikation_1_2";
BA_ "SysSignalName" SG_ 1042 EWS_COMM_1_2 "EWS_COMM_1_2";
BA_ "CompuMethodName" SG_ 1043 EWS_COMM_2_1 "EWS_COMM";
BA_ "ISignalName" SG_ 1043 EWS_COMM_2_1 "EWS_COMM_2_1";
BA_ "LongName" SG_ 1043 EWS_COMM_2_1 "EWS_Kommunikation_2_1";
BA_ "SysSignalName" SG_ 1043 EWS_COMM_2_1 "EWS_COMM_2_1";
BA_ "CompuMethodName" SG_ 1043 EWS_COMM_2_2 "EWS_COMM";
BA_ "ISignalName" SG_ 1043 EWS_COMM_2_2 "EWS_COMM_2_2";
BA_ "LongName" SG_ 1043 EWS_COMM_2_2 "EWS_Kommunikation_2_2";
BA_ "SysSignalName" SG_ 1043 EWS_COMM_2_2 "EWS_COMM_2_2";
BA_ "CompuMethodName" SG_ 1044 EWS_COMM_7_1 "EWS_COMM";
BA_ "ISignalName" SG_ 1044 EWS_COMM_7_1 "EWS_COMM_7_1";
BA_ "LongName" SG_ 1044 EWS_COMM_7_1 "EWS_Kommunikation_7_1";
BA_ "SysSignalName" SG_ 1044 EWS_COMM_7_1 "EWS_COMM_7_1";
BA_ "CompuMethodName" SG_ 1044 EWS_COMM_7_2 "EWS_COMM";
BA_ "ISignalName" SG_ 1044 EWS_COMM_7_2 "EWS_COMM_7_2";
BA_ "LongName" SG_ 1044 EWS_COMM_7_2 "EWS_Kommunikation_7_2";
BA_ "SysSignalName" SG_ 1044 EWS_COMM_7_2 "EWS_COMM_7_2";
BA_ "CompuMethodName" SG_ 1045 EWS_COMM_8_1 "EWS_COMM";
BA_ "ISignalName" SG_ 1045 EWS_COMM_8_1 "EWS_COMM_8_1";
BA_ "LongName" SG_ 1045 EWS_COMM_8_1 "EWS_Kommunikation_8_1";
BA_ "SysSignalName" SG_ 1045 EWS_COMM_8_1 "EWS_COMM_8_1";
BA_ "CompuMethodName" SG_ 1045 EWS_COMM_8_2 "EWS_COMM";
BA_ "ISignalName" SG_ 1045 EWS_COMM_8_2 "EWS_COMM_8_2";
BA_ "LongName" SG_ 1045 EWS_COMM_8_2 "EWS_Kommunikation_8_2";
BA_ "SysSignalName" SG_ 1045 EWS_COMM_8_2 "EWS_COMM_8_2";
BA_ "CompuMethodName" SG_ 200 QU_FN_HDC "QU_FN_HDC";
BA_ "ISignalName" SG_ 200 QU_FN_HDC "QU_FN_HDC";
BA_ "LongName" SG_ 200 QU_FN_HDC "Qualifier_function_HDC";
BA_ "SysSignalName" SG_ 200 QU_FN_HDC "QU_FN_HDC";
BA_ "CompuMethodName" SG_ 623 FRVEH_OBJ_ID "FRVEH_OBJ_ID";
BA_ "ISignalName" SG_ 623 FRVEH_OBJ_ID "FRVEH_OBJ_ID";
BA_ "LongName" SG_ 623 FRVEH_OBJ_ID "Vorderfahrzeug_Objekt_ID";
BA_ "SysSignalName" SG_ 623 FRVEH_OBJ_ID "FRVEH_OBJ_ID";
BA_ "CompuMethodName" SG_ 623 FRVEH_V_X "FRVEH_V";
BA_ "GenSigStartValue" SG_ 623 FRVEH_V_X -150;
BA_ "ISignalName" SG_ 623 FRVEH_V_X "FRVEH_V_X";
BA_ "LongName" SG_ 623 FRVEH_V_X "Vorderfahrzeug_Geschwindigkeit_X";
BA_ "SysSignalName" SG_ 623 FRVEH_V_X "FRVEH_V_X";
BA_ "CompuMethodName" SG_ 623 FRVEH_V_Y "FRVEH_V";
BA_ "GenSigStartValue" SG_ 623 FRVEH_V_Y -150;
BA_ "ISignalName" SG_ 623 FRVEH_V_Y "FRVEH_V_Y";
BA_ "LongName" SG_ 623 FRVEH_V_Y "Vorderfahrzeug_Geschwindigkeit_Y";
BA_ "SysSignalName" SG_ 623 FRVEH_V_Y "FRVEH_V_Y";
BA_ "CompuMethodName" SG_ 623 FRVEH_GAP_X "FRVEH_GAP_X";
BA_ "ISignalName" SG_ 623 FRVEH_GAP_X "FRVEH_GAP_X";
BA_ "LongName" SG_ 623 FRVEH_GAP_X "Vorderfahrzeug_Abstand_X";
BA_ "SysSignalName" SG_ 623 FRVEH_GAP_X "FRVEH_GAP_X";
BA_ "CompuMethodName" SG_ 623 FRVEH_GAP_Y "FRVEH_GAP_Y";
BA_ "GenSigStartValue" SG_ 623 FRVEH_GAP_Y -300;
BA_ "ISignalName" SG_ 623 FRVEH_GAP_Y "FRVEH_GAP_Y";
BA_ "LongName" SG_ 623 FRVEH_GAP_Y "Vorderfahrzeug_Abstand_Y";
BA_ "SysSignalName" SG_ 623 FRVEH_GAP_Y "FRVEH_GAP_Y";
BA_ "CompuMethodName" SG_ 623 QualifierEventDataFunctionFrontV "QualifierEventDataFunctionFrontVehicle";
BA_ "ISignalName" SG_ 623 QualifierEventDataFunctionFrontV "QualifierEventDataFunctionFrontVehicle";
BA_ "LongName" SG_ 623 QualifierEventDataFunctionFrontV "QualifierEventDataFunctionFrontVehicle";
BA_ "SysSignalName" SG_ 623 QualifierEventDataFunctionFrontV "QualifierEventDataFunctionFrontVehicle";
BA_ "SystemSignalLongSymbol" SG_ 623 QualifierEventDataFunctionFrontV "QualifierEventDataFunctionFrontVehicle";
BA_ "CompuMethodName" SG_ 623 QualifierExtendedFunctionFrontVe "QualifierExtendedFunctionFrontVehicle";
BA_ "ISignalName" SG_ 623 QualifierExtendedFunctionFrontVe "QualifierExtendedFunctionFrontVehicle";
BA_ "LongName" SG_ 623 QualifierExtendedFunctionFrontVe "QualifierExtendedFunctionFrontVehicle";
BA_ "SysSignalName" SG_ 623 QualifierExtendedFunctionFrontVe "QualifierExtendedFunctionFrontVehicle";
BA_ "SystemSignalLongSymbol" SG_ 623 QualifierExtendedFunctionFrontVe "QualifierExtendedFunctionFrontVehicle";
BA_ "CompuMethodName" SG_ 624 FRVEH_EXT_OBJ_ID "FRVEH_OBJ_ID";
BA_ "ISignalName" SG_ 624 FRVEH_EXT_OBJ_ID "FRVEH_EXT_OBJ_ID";
BA_ "LongName" SG_ 624 FRVEH_EXT_OBJ_ID "Vorderfahrzeug_Erweitert_Objekt_ID";
BA_ "SysSignalName" SG_ 624 FRVEH_EXT_OBJ_ID "FRVEH_EXT_OBJ_ID";
BA_ "CompuMethodName" SG_ 624 FRVEH_EXT_OBJ_TYP "FRVEH_EXT_OBJ_TYP";
BA_ "ISignalName" SG_ 624 FRVEH_EXT_OBJ_TYP "FRVEH_EXT_OBJ_TYP";
BA_ "LongName" SG_ 624 FRVEH_EXT_OBJ_TYP "Vorderfahrzeug_Erweitert_Objekt_Typ";
BA_ "SysSignalName" SG_ 624 FRVEH_EXT_OBJ_TYP "FRVEH_EXT_OBJ_TYP";
BA_ "CompuMethodName" SG_ 624 FRVEH_EXT_ST_MOV "FRVEH_EXT_ST_MOV";
BA_ "ISignalName" SG_ 624 FRVEH_EXT_ST_MOV "FRVEH_EXT_ST_MOV";
BA_ "LongName" SG_ 624 FRVEH_EXT_ST_MOV "Vorderfahrzeug_Erweitert_Status_Bewegung";
BA_ "SysSignalName" SG_ 624 FRVEH_EXT_ST_MOV "FRVEH_EXT_ST_MOV";
BA_ "CompuMethodName" SG_ 624 FRVEH_EXT_WID "FRVEH_EXT_WID";
BA_ "ISignalName" SG_ 624 FRVEH_EXT_WID "FRVEH_EXT_WID";
BA_ "LongName" SG_ 624 FRVEH_EXT_WID "Vorderfahrzeug_Erweitert_Breite";
BA_ "SysSignalName" SG_ 624 FRVEH_EXT_WID "FRVEH_EXT_WID";
BA_ "CompuMethodName" SG_ 1073 ST_SER_DSCO_PLG "ST_SER_DSCO_PLG";
BA_ "ISignalName" SG_ 1073 ST_SER_DSCO_PLG "ST_SER_DSCO_PLG";
BA_ "LongName" SG_ 1073 ST_SER_DSCO_PLG "Status_Service_Trennung_Stecker";
BA_ "SysSignalName" SG_ 1073 ST_SER_DSCO_PLG "ST_SER_DSCO_PLG";
BA_ "CompuMethodName" SG_ 1073 PRD_DUR_CHGNG "PRD_DUR_CHGNG";
BA_ "ISignalName" SG_ 1073 PRD_DUR_CHGNG "PRD_DUR_CHGNG";
BA_ "LongName" SG_ 1073 PRD_DUR_CHGNG "Voraussage_Dauer_Laden";
BA_ "SysSignalName" SG_ 1073 PRD_DUR_CHGNG "PRD_DUR_CHGNG";
BA_ "CompuMethodName" SG_ 1073 PRD_T_EOCHG "PRD_T_EOCHG";
BA_ "ISignalName" SG_ 1073 PRD_T_EOCHG "PRD_T_EOCHG";
BA_ "LongName" SG_ 1073 PRD_T_EOCHG "Voraussage_Zeit_Ladeende";
BA_ "SysSignalName" SG_ 1073 PRD_T_EOCHG "PRD_T_EOCHG";
BA_ "CompuMethodName" SG_ 1073 ENC_HVSTO_MAX "Energieinhalt_HVSTO_MAX";
BA_ "ISignalName" SG_ 1073 ENC_HVSTO_MAX "ENC_HVSTO_MAX";
BA_ "LongName" SG_ 1073 ENC_HVSTO_MAX "Energieinhalt_Hochvoltspeicher_Maximal";
BA_ "SysSignalName" SG_ 1073 ENC_HVSTO_MAX "ENC_HVSTO_MAX";
BA_ "CompuMethodName" SG_ 569 PRD_ENERG_CHGCOND_2_COS "PRD_ENERG_CHGCOND_COSP";
BA_ "ISignalName" SG_ 569 PRD_ENERG_CHGCOND_2_COS "PRD_ENERG_CHGCOND_2_COS";
BA_ "LongName" SG_ 569 PRD_ENERG_CHGCOND_2_COS "Voraussage_Energie_Ladezustand_2_Verbraucher";
BA_ "SysSignalName" SG_ 569 PRD_ENERG_CHGCOND_2_COS "PRD_ENERG_CHGCOND_2_COS";
BA_ "CompuMethodName" SG_ 569 PRD_ENERG_CHGTAR_2_HVSTO "PRD_ENERG_CHGTAR_2_HVSTO";
BA_ "ISignalName" SG_ 569 PRD_ENERG_CHGTAR_2_HVSTO "PRD_ENERG_CHGTAR_2_HVSTO";
BA_ "LongName" SG_ 569 PRD_ENERG_CHGTAR_2_HVSTO "Voraussage_Energie_Ladeziel_2_Hochvoltspeicher";
BA_ "SysSignalName" SG_ 569 PRD_ENERG_CHGTAR_2_HVSTO "PRD_ENERG_CHGTAR_2_HVSTO";
BA_ "CompuMethodName" SG_ 569 AVL_ISRE "AVL_ISRE";
BA_ "ISignalName" SG_ 569 AVL_ISRE "AVL_ISRE";
BA_ "LongName" SG_ 569 AVL_ISRE "Ist_Isolationswiderstand";
BA_ "SysSignalName" SG_ 569 AVL_ISRE "AVL_ISRE";
BA_ "CompuMethodName" SG_ 1046 ER_RNG "ER_RNG";
BA_ "ISignalName" SG_ 1046 ER_RNG "ER_RNG";
BA_ "LongName" SG_ 1046 ER_RNG "Elektrische_Reichweite";
BA_ "SysSignalName" SG_ 1046 ER_RNG "ER_RNG";
BA_ "CompuMethodName" SG_ 1046 DISP_AVL_FUTA_FLLV "DISP_AVL_FUTA_FLLV";
BA_ "ISignalName" SG_ 1046 DISP_AVL_FUTA_FLLV "DISP_AVL_FUTA_FLLV";
BA_ "LongName" SG_ 1046 DISP_AVL_FUTA_FLLV "Anzeige_Ist_Tank_Füllstand";
BA_ "SysSignalName" SG_ 1046 DISP_AVL_FUTA_FLLV "DISP_AVL_FUTA_FLLV";
BA_ "CompuMethodName" SG_ 1046 AVR_RNC "AVR_RNC";
BA_ "ISignalName" SG_ 1046 AVR_RNC "AVR_RNC";
BA_ "LongName" SG_ 1046 AVR_RNC "Durchschnitt_Reichweitenverbrauch";
BA_ "SysSignalName" SG_ 1046 AVR_RNC "AVR_RNC";
BA_ "CompuMethodName" SG_ 1046 ENG_TEMP_EV "ENG_TEMP_EV";
BA_ "ISignalName" SG_ 1046 ENG_TEMP_EV "ENG_TEMP_EV";
BA_ "LongName" SG_ 1046 ENG_TEMP_EV "Motor_Temperatur_Bewertet";
BA_ "SysSignalName" SG_ 1046 ENG_TEMP_EV "ENG_TEMP_EV";
BA_ "CompuMethodName" SG_ 1046 PRES_AUXC_PWR "PRES_AUXC_PWR";
BA_ "ISignalName" SG_ 1046 PRES_AUXC_PWR "PRES_AUXC_PWR";
BA_ "LongName" SG_ 1046 PRES_AUXC_PWR "present_auxiliary-consumer_power";
BA_ "SysSignalName" SG_ 1046 PRES_AUXC_PWR "PRES_AUXC_PWR";
BA_ "CompuMethodName" SG_ 1046 AVR_V "AVR_V";
BA_ "ISignalName" SG_ 1046 AVR_V "AVR_V";
BA_ "LongName" SG_ 1046 AVR_V "Durchschnitt_Geschwindigkeit";
BA_ "SysSignalName" SG_ 1046 AVR_V "AVR_V";
BA_ "CompuMethodName" SG_ 1017 CRC_DT_PT_2 "CRC8";
BA_ "ISignalName" SG_ 1017 CRC_DT_PT_2 "CRC_DT_PT_2";
BA_ "LongName" SG_ 1017 CRC_DT_PT_2 "CRC_Daten_Antriebsstrang_2";
BA_ "SysSignalName" SG_ 1017 CRC_DT_PT_2 "CRC_DT_PT_2";
BA_ "CompuMethodName" SG_ 1017 ALIV_DT_PT_2 "Aliv_4";
BA_ "ISignalName" SG_ 1017 ALIV_DT_PT_2 "ALIV_DT_PT_2";
BA_ "LongName" SG_ 1017 ALIV_DT_PT_2 "Alive_Daten_Antriebsstrang_2";
BA_ "SysSignalName" SG_ 1017 ALIV_DT_PT_2 "ALIV_DT_PT_2";
BA_ "CompuMethodName" SG_ 1017 ST_MOD_DRV "ST_CHC_DRV";
BA_ "ISignalName" SG_ 1017 ST_MOD_DRV "ST_MOD_DRV";
BA_ "LongName" SG_ 1017 ST_MOD_DRV "Status_Modus_Antrieb";
BA_ "SysSignalName" SG_ 1017 ST_MOD_DRV "ST_MOD_DRV";
BA_ "CompuMethodName" SG_ 1017 ST_DRV_VEH "ST_DRV_VEH";
BA_ "ISignalName" SG_ 1017 ST_DRV_VEH "ST_DRV_VEH";
BA_ "LongName" SG_ 1017 ST_DRV_VEH "Status_Antrieb_Fahrzeug";
BA_ "SysSignalName" SG_ 1017 ST_DRV_VEH "ST_DRV_VEH";
BA_ "CompuMethodName" SG_ 1017 ST_ENG_RUN_DRV "ST_ENG_RUN_DRV";
BA_ "ISignalName" SG_ 1017 ST_ENG_RUN_DRV "ST_ENG_RUN_DRV";
BA_ "LongName" SG_ 1017 ST_ENG_RUN_DRV "Status_Motor_Läuft_Antrieb";
BA_ "SysSignalName" SG_ 1017 ST_ENG_RUN_DRV "ST_ENG_RUN_DRV";
BA_ "CompuMethodName" SG_ 1017 ST_SW_CLT_DRV "ST_SW_CLT";
BA_ "ISignalName" SG_ 1017 ST_SW_CLT_DRV "ST_SW_CLT_DRV";
BA_ "LongName" SG_ 1017 ST_SW_CLT_DRV "Status_Schalter_Kupplung_Antrieb";
BA_ "SysSignalName" SG_ 1017 ST_SW_CLT_DRV "ST_SW_CLT_DRV";
BA_ "CompuMethodName" SG_ 1017 ST_ILK_STRT_DRV "ST_ILK_STRT_DRV";
BA_ "ISignalName" SG_ 1017 ST_ILK_STRT_DRV "ST_ILK_STRT_DRV";
BA_ "LongName" SG_ 1017 ST_ILK_STRT_DRV "Status_Sperre_Anlasser_Antrieb";
BA_ "SysSignalName" SG_ 1017 ST_ILK_STRT_DRV "ST_ILK_STRT_DRV";
BA_ "CompuMethodName" SG_ 1017 ST_IDLG_ENG_DRV "ST_IDLG_ENG";
BA_ "ISignalName" SG_ 1017 ST_IDLG_ENG_DRV "ST_IDLG_ENG_DRV";
BA_ "LongName" SG_ 1017 ST_IDLG_ENG_DRV "Status_Leerlauf_Motor_Antrieb";
BA_ "SysSignalName" SG_ 1017 ST_IDLG_ENG_DRV "ST_IDLG_ENG_DRV";
BA_ "CompuMethodName" SG_ 1017 TEMP_ENG_DRV "UI_8_noIniVal_noDflVal_255_1_MI_48_noEnc_hasRng";
BA_ "GenSigStartValue" SG_ 1017 TEMP_ENG_DRV 48;
BA_ "ISignalName" SG_ 1017 TEMP_ENG_DRV "TEMP_ENG_DRV";
BA_ "LongName" SG_ 1017 TEMP_ENG_DRV "Temperatur_Motor_Antrieb";
BA_ "SysSignalName" SG_ 1017 TEMP_ENG_DRV "TEMP_ENG_DRV";
BA_ "CompuMethodName" SG_ 1017 TEMP_EOI_DRV "UI_8_noIniVal_noDflVal_255_1_MI_48_noEnc_hasRng_1";
BA_ "GenSigStartValue" SG_ 1017 TEMP_EOI_DRV 48;
BA_ "ISignalName" SG_ 1017 TEMP_EOI_DRV "TEMP_EOI_DRV";
BA_ "LongName" SG_ 1017 TEMP_EOI_DRV "Temperatur_Motoröl_Antrieb";
BA_ "SysSignalName" SG_ 1017 TEMP_EOI_DRV "TEMP_EOI_DRV";
BA_ "CompuMethodName" SG_ 1017 ST_GRSEL_DRV "ST_GRSEL_DRV";
BA_ "ISignalName" SG_ 1017 ST_GRSEL_DRV "ST_GRSEL_DRV";
BA_ "LongName" SG_ 1017 ST_GRSEL_DRV "Status_Gangwahl_Antrieb";
BA_ "SysSignalName" SG_ 1017 ST_GRSEL_DRV "ST_GRSEL_DRV";
BA_ "CompuMethodName" SG_ 1017 RLS_ENGSTA "RLS_ENGSTA";
BA_ "ISignalName" SG_ 1017 RLS_ENGSTA "RLS_ENGSTA";
BA_ "LongName" SG_ 1017 RLS_ENGSTA "Freigabe_Motorstart";
BA_ "SysSignalName" SG_ 1017 RLS_ENGSTA "RLS_ENGSTA";
BA_ "CompuMethodName" SG_ 1017 RDUC_DOCTR_RPM_DRV_2 "RDUC_DOCTR_RPM_DRV_2";
BA_ "ISignalName" SG_ 1017 RDUC_DOCTR_RPM_DRV_2 "RDUC_DOCTR_RPM_DRV_2";
BA_ "LongName" SG_ 1017 RDUC_DOCTR_RPM_DRV_2 "reduction_down-control_RPM_drive_2";
BA_ "SysSignalName" SG_ 1017 RDUC_DOCTR_RPM_DRV_2 "RDUC_DOCTR_RPM_DRV_2";
BA_ "CompuMethodName" SG_ 1017 RPM_ENG_MAX_ALW "RPM_ENG_MAX_ALW";
BA_ "ISignalName" SG_ 1017 RPM_ENG_MAX_ALW "RPM_ENG_MAX_ALW";
BA_ "LongName" SG_ 1017 RPM_ENG_MAX_ALW "Drehzahl_Motor_Maximal_zulässig";
BA_ "SysSignalName" SG_ 1017 RPM_ENG_MAX_ALW "RPM_ENG_MAX_ALW";
BA_ "CompuMethodName" SG_ 811 AVL_ENERG_COSP_MOT_TRCT "AVL_ENERG_COSP_MOT_TRCT";
BA_ "ISignalName" SG_ 811 AVL_ENERG_COSP_MOT_TRCT "AVL_ENERG_COSP_MOT_TRCT";
BA_ "LongName" SG_ 811 AVL_ENERG_COSP_MOT_TRCT "Ist_Energie_Verbrauch_E-Motor_Traktion";
BA_ "SysSignalName" SG_ 811 AVL_ENERG_COSP_MOT_TRCT "AVL_ENERG_COSP_MOT_TRCT";
BA_ "CompuMethodName" SG_ 811 AVL_ENERG_MOT_RECUP "AVL_ENERG_COSP_LV_COS";
BA_ "ISignalName" SG_ 811 AVL_ENERG_MOT_RECUP "AVL_ENERG_MOT_RECUP";
BA_ "LongName" SG_ 811 AVL_ENERG_MOT_RECUP "Ist_Energie_E-Motor_Rekuperation";
BA_ "SysSignalName" SG_ 811 AVL_ENERG_MOT_RECUP "AVL_ENERG_MOT_RECUP";
BA_ "CompuMethodName" SG_ 513 AVL_AUXC_ENERG_BS_LD "AVL_AUXC_ENERG";
BA_ "ISignalName" SG_ 513 AVL_AUXC_ENERG_BS_LD "AVL_AUXC_ENERG_BS_LD";
BA_ "LongName" SG_ 513 AVL_AUXC_ENERG_BS_LD "actual-value_auxiliary-consumer_Energy_base_load";
BA_ "SysSignalName" SG_ 513 AVL_AUXC_ENERG_BS_LD "AVL_AUXC_ENERG_BS_LD";
BA_ "CompuMethodName" SG_ 513 AVL_AUXC_ENERG "AVL_AUXC_ENERG";
BA_ "ISignalName" SG_ 513 AVL_AUXC_ENERG "AVL_AUXC_ENERG";
BA_ "LongName" SG_ 513 AVL_AUXC_ENERG "Ist_Nebenverbraucher_Energie";
BA_ "SysSignalName" SG_ 513 AVL_AUXC_ENERG "AVL_AUXC_ENERG";
BA_ "CompuMethodName" SG_ 513 V_DRV_EL_MAX "V_DRV_EL_MAX";
BA_ "ISignalName" SG_ 513 V_DRV_EL_MAX "V_DRV_EL_MAX";
BA_ "LongName" SG_ 513 V_DRV_EL_MAX "Geschwindigkeit_Antrieb_Elektrisch_Maximal";
BA_ "SysSignalName" SG_ 513 V_DRV_EL_MAX "V_DRV_EL_MAX";
BA_ "CompuMethodName" SG_ 513 DISP_LIM_V_URB "DISP_LIM_V_URB";
BA_ "ISignalName" SG_ 513 DISP_LIM_V_URB "DISP_LIM_V_URB";
BA_ "LongName" SG_ 513 DISP_LIM_V_URB "Anzeige_Begrenzung_Geschwindigkeit_Urban";
BA_ "SysSignalName" SG_ 513 DISP_LIM_V_URB "DISP_LIM_V_URB";
BA_ "CompuMethodName" SG_ 513 ST_SOC_CLCTR "ST_SOC_CLCTR";
BA_ "ISignalName" SG_ 513 ST_SOC_CLCTR "ST_SOC_CLCTR";
BA_ "LongName" SG_ 513 ST_SOC_CLCTR "Status_SOC_Regelung";
BA_ "SysSignalName" SG_ 513 ST_SOC_CLCTR "ST_SOC_CLCTR";
BA_ "CompuMethodName" SG_ 984 RQ_SW_DXP_KDIS "RQ_SW_DXP_KDIS";
BA_ "ISignalName" SG_ 984 RQ_SW_DXP_KDIS "RQ_SW_DXP_KDIS";
BA_ "LongName" SG_ 984 RQ_SW_DXP_KDIS "Anforderung_Schalter_Fahrerlebnis_Kombi-Display";
BA_ "SysSignalName" SG_ 984 RQ_SW_DXP_KDIS "RQ_SW_DXP_KDIS";
BA_ "CompuMethodName" SG_ 984 AVL_MOD_DXP "AVL_MOD_DXP_2";
BA_ "ISignalName" SG_ 984 AVL_MOD_DXP "AVL_MOD_DXP";
BA_ "LongName" SG_ 984 AVL_MOD_DXP "Ist_Modus_Fahrerlebnis";
BA_ "SysSignalName" SG_ 984 AVL_MOD_DXP "AVL_MOD_DXP";
BA_ "CompuMethodName" SG_ 325 BoostReserve "BoostReserve";
BA_ "ISignalName" SG_ 325 BoostReserve "BoostReserve";
BA_ "LongName" SG_ 325 BoostReserve "BoostReserve";
BA_ "SysSignalName" SG_ 325 BoostReserve "BoostReserve";
BA_ "CompuMethodName" SG_ 325 BoostFunctionState "BoostFunctionState";
BA_ "ISignalName" SG_ 325 BoostFunctionState "BoostFunctionState";
BA_ "LongName" SG_ 325 BoostFunctionState "BoostFunctionState";
BA_ "SysSignalName" SG_ 325 BoostFunctionState "BoostFunctionState";
BA_ "CompuMethodName" SG_ 325 BoostState "BoostState";
BA_ "ISignalName" SG_ 325 BoostState "BoostState";
BA_ "LongName" SG_ 325 BoostState "BoostState";
BA_ "SysSignalName" SG_ 325 BoostState "BoostState";
BA_ "CompuMethodName" SG_ 325 LaunchControlFunctionState "LaunchControlFunctionState";
BA_ "ISignalName" SG_ 325 LaunchControlFunctionState "LaunchControlFunctionState";
BA_ "LongName" SG_ 325 LaunchControlFunctionState "LaunchControlFunctionState";
BA_ "SysSignalName" SG_ 325 LaunchControlFunctionState "LaunchControlFunctionState";
BA_ "CompuMethodName" SG_ 668 DisplayPowerCharging "DisplayPowerCharging";
BA_ "ISignalName" SG_ 668 DisplayPowerCharging "DisplayPowerCharging";
BA_ "LongName" SG_ 668 DisplayPowerCharging "DisplayPowerCharging";
BA_ "SysSignalName" SG_ 668 DisplayPowerCharging "DisplayPowerCharging";
BA_ "CompuMethodName" SG_ 668 DisplayChargeModus "DisplayChargeModus";
BA_ "ISignalName" SG_ 668 DisplayChargeModus "DisplayChargeModus";
BA_ "LongName" SG_ 668 DisplayChargeModus "DisplayChargeModus";
BA_ "SysSignalName" SG_ 668 DisplayChargeModus "DisplayChargeModus";
BA_ "CompuMethodName" SG_ 668 StatusPredictionRangeChargingTar "StatusPredictionRangeChargingTarget";
BA_ "ISignalName" SG_ 668 StatusPredictionRangeChargingTar "StatusPredictionRangeChargingTarget";
BA_ "LongName" SG_ 668 StatusPredictionRangeChargingTar "StatusPredictionRangeChargingTarget";
BA_ "SysSignalName" SG_ 668 StatusPredictionRangeChargingTar "StatusPredictionRangeChargingTarget";
BA_ "SystemSignalLongSymbol" SG_ 668 StatusPredictionRangeChargingTar "StatusPredictionRangeChargingTarget";
BA_ "CompuMethodName" SG_ 668 StatusChargeControlPlug "StatusChargeControlPlug";
BA_ "ISignalName" SG_ 668 StatusChargeControlPlug "StatusChargeControlPlug";
BA_ "LongName" SG_ 668 StatusChargeControlPlug "StatusChargeControlPlug";
BA_ "SysSignalName" SG_ 668 StatusChargeControlPlug "StatusChargeControlPlug";
BA_ "CompuMethodName" SG_ 668 StatusSoeChargingTarget "StatusSoeChargingTarget";
BA_ "ISignalName" SG_ 668 StatusSoeChargingTarget "StatusSoeChargingTarget";
BA_ "LongName" SG_ 668 StatusSoeChargingTarget "StatusSoeChargingTarget";
BA_ "SysSignalName" SG_ 668 StatusSoeChargingTarget "StatusSoeChargingTarget";
BA_ "CompuMethodName" SG_ 839 DisplayPowerChargingDCMax "DisplayPowerChargingDCMax";
BA_ "ISignalName" SG_ 839 DisplayPowerChargingDCMax "DisplayPowerChargingDCMax";
BA_ "LongName" SG_ 839 DisplayPowerChargingDCMax "DisplayPowerChargingDCMax";
BA_ "SysSignalName" SG_ 839 DisplayPowerChargingDCMax "DisplayPowerChargingDCMax";
BA_ "CompuMethodName" SG_ 839 DisplayPowerChargingACMax "DisplayPowerChargingACMax";
BA_ "ISignalName" SG_ 839 DisplayPowerChargingACMax "DisplayPowerChargingACMax";
BA_ "LongName" SG_ 839 DisplayPowerChargingACMax "DisplayPowerChargingACMax";
BA_ "SysSignalName" SG_ 839 DisplayPowerChargingACMax "DisplayPowerChargingACMax";
BA_ "CompuMethodName" SG_ 839 DisplayPowerChargingInfrastructu "DisplayPowerChargingDCMax";
BA_ "ISignalName" SG_ 839 DisplayPowerChargingInfrastructu "DisplayPowerChargingInfrastructureMax";
BA_ "LongName" SG_ 839 DisplayPowerChargingInfrastructu "DisplayPowerChargingInfrastructureMax";
BA_ "SysSignalName" SG_ 839 DisplayPowerChargingInfrastructu "DisplayPowerChargingInfrastructureMax";
BA_ "SystemSignalLongSymbol" SG_ 839 DisplayPowerChargingInfrastructu "DisplayPowerChargingInfrastructureMax";
BA_ "CompuMethodName" SG_ 839 DisplayDegradationInfrastructure "DisplayDegradationInfrastructure";
BA_ "ISignalName" SG_ 839 DisplayDegradationInfrastructure "DisplayDegradationInfrastructure";
BA_ "LongName" SG_ 839 DisplayDegradationInfrastructure "DisplayDegradationInfrastructure";
BA_ "SysSignalName" SG_ 839 DisplayDegradationInfrastructure "DisplayDegradationInfrastructure";
BA_ "CompuMethodName" SG_ 529 CRC_DisplayCheckcontrolDFNS1 "CRC8";
BA_ "ISignalName" SG_ 529 CRC_DisplayCheckcontrolDFNS1 "CRC_DisplayCheckcontrolDFNS1";
BA_ "LongName" SG_ 529 CRC_DisplayCheckcontrolDFNS1 "CRC_DisplayCheckcontrolDFNS1";
BA_ "SysSignalName" SG_ 529 CRC_DisplayCheckcontrolDFNS1 "CRC_DisplayCheckcontrolDFNS1";
BA_ "CompuMethodName" SG_ 529 ALIV_DisplayCheckcontrolDFNS1 "Alive_4_Bit_Unsigned_Integer";
BA_ "ISignalName" SG_ 529 ALIV_DisplayCheckcontrolDFNS1 "ALIV_DisplayCheckcontrolDFNS1";
BA_ "LongName" SG_ 529 ALIV_DisplayCheckcontrolDFNS1 "ALIV_DisplayCheckcontrolDFNS1";
BA_ "SysSignalName" SG_ 529 ALIV_DisplayCheckcontrolDFNS1 "ALIV_DisplayCheckcontrolDFNS1";
BA_ "CompuMethodName" SG_ 529 CHL_DisplayCheckcontrolDFNS1 "CHL_4Uint";
BA_ "ISignalName" SG_ 529 CHL_DisplayCheckcontrolDFNS1 "CHL_DisplayCheckcontrolDFNS1";
BA_ "LongName" SG_ 529 CHL_DisplayCheckcontrolDFNS1 "CHL_DisplayCheckcontrolDFNS1";
BA_ "SysSignalName" SG_ 529 CHL_DisplayCheckcontrolDFNS1 "CHL_DisplayCheckcontrolDFNS1";
BA_ "CompuMethodName" SG_ 529 NumberDisplayCheckcontrolDFNS1 "NumberDisplayCheckcontrolDFNS1";
BA_ "ISignalName" SG_ 529 NumberDisplayCheckcontrolDFNS1 "NumberDisplayCheckcontrolDFNS1";
BA_ "LongName" SG_ 529 NumberDisplayCheckcontrolDFNS1 "NumberDisplayCheckcontrolDFNS1";
BA_ "SysSignalName" SG_ 529 NumberDisplayCheckcontrolDFNS1 "NumberDisplayCheckcontrolDFNS1";
BA_ "CompuMethodName" SG_ 529 StatusDisplayCheckcontrolDFNS1 "StatusDisplayCheckcontrolDFNS1";
BA_ "ISignalName" SG_ 529 StatusDisplayCheckcontrolDFNS1 "StatusDisplayCheckcontrolDFNS1";
BA_ "LongName" SG_ 529 StatusDisplayCheckcontrolDFNS1 "StatusDisplayCheckcontrolDFNS1";
BA_ "SysSignalName" SG_ 529 StatusDisplayCheckcontrolDFNS1 "StatusDisplayCheckcontrolDFNS1";
BA_ "CompuMethodName" SG_ 529 StatusIndicateDisplayCheckcontro "StatusIndicateDisplayCheckcontrolDFNS1";
BA_ "ISignalName" SG_ 529 StatusIndicateDisplayCheckcontro "StatusIndicateDisplayCheckcontrolDFNS1";
BA_ "LongName" SG_ 529 StatusIndicateDisplayCheckcontro "StatusIndicateDisplayCheckcontrolDFNS1";
BA_ "SysSignalName" SG_ 529 StatusIndicateDisplayCheckcontro "StatusIndicateDisplayCheckcontrolDFNS1";
BA_ "SystemSignalLongSymbol" SG_ 529 StatusIndicateDisplayCheckcontro "StatusIndicateDisplayCheckcontrolDFNS1";
BA_ "ISignalName" SG_ 529 DisplayCheckcontrolDFNS1_dummy_3 "DisplayCheckcontrolDFNS1_dummy_38_39";
BA_ "LongName" SG_ 529 DisplayCheckcontrolDFNS1_dummy_3 "DisplayCheckcontrolDFNS1_dummy_38_39";
BA_ "SysSignalName" SG_ 529 DisplayCheckcontrolDFNS1_dummy_3 "DisplayCheckcontrolDFNS1_dummy_38_39";
BA_ "SystemSignalLongSymbol" SG_ 529 DisplayCheckcontrolDFNS1_dummy_3 "DisplayCheckcontrolDFNS1_dummy_38_39";
BA_ "CompuMethodName" SG_ 529 TransmissiontypeDisplayCheckcont "TransmissiontypeDisplayCheckcontrolDFNS1";
BA_ "ISignalName" SG_ 529 TransmissiontypeDisplayCheckcont "TransmissiontypeDisplayCheckcontrolDFNS1";
BA_ "LongName" SG_ 529 TransmissiontypeDisplayCheckcont "TransmissiontypeDisplayCheckcontrolDFNS1";
BA_ "SysSignalName" SG_ 529 TransmissiontypeDisplayCheckcont "TransmissiontypeDisplayCheckcontrolDFNS1";
BA_ "SystemSignalLongSymbol" SG_ 529 TransmissiontypeDisplayCheckcont "TransmissiontypeDisplayCheckcontrolDFNS1";
BA_ "ISignalName" SG_ 529 DisplayCheckcontrolDFNS1_dummy_4 "DisplayCheckcontrolDFNS1_dummy_45_63";
BA_ "LongName" SG_ 529 DisplayCheckcontrolDFNS1_dummy_4 "DisplayCheckcontrolDFNS1_dummy_45_63";
BA_ "SysSignalName" SG_ 529 DisplayCheckcontrolDFNS1_dummy_4 "DisplayCheckcontrolDFNS1_dummy_45_63";
BA_ "SystemSignalLongSymbol" SG_ 529 DisplayCheckcontrolDFNS1_dummy_4 "DisplayCheckcontrolDFNS1_dummy_45_63";
BA_ "CompuMethodName" SG_ 576 CRC_DisplayCheckcontrolSMBF "CRC_8";
BA_ "ISignalName" SG_ 576 CRC_DisplayCheckcontrolSMBF "CRC_DisplayCheckcontrolSMBF";
BA_ "LongName" SG_ 576 CRC_DisplayCheckcontrolSMBF "CRC_DisplayCheckcontrolSMBF";
BA_ "SysSignalName" SG_ 576 CRC_DisplayCheckcontrolSMBF "CRC_DisplayCheckcontrolSMBF";
BA_ "CompuMethodName" SG_ 576 ALIV_DisplayCheckcontrolSMBF "ALIV_4_BIT_UInt";
BA_ "ISignalName" SG_ 576 ALIV_DisplayCheckcontrolSMBF "ALIV_DisplayCheckcontrolSMBF";
BA_ "LongName" SG_ 576 ALIV_DisplayCheckcontrolSMBF "ALIV_DisplayCheckcontrolSMBF";
BA_ "SysSignalName" SG_ 576 ALIV_DisplayCheckcontrolSMBF "ALIV_DisplayCheckcontrolSMBF";
BA_ "CompuMethodName" SG_ 576 CHL_DisplayCheckcontrolSMBF "CHL_4_UInt";
BA_ "ISignalName" SG_ 576 CHL_DisplayCheckcontrolSMBF "CHL_DisplayCheckcontrolSMBF";
BA_ "LongName" SG_ 576 CHL_DisplayCheckcontrolSMBF "CHL_DisplayCheckcontrolSMBF";
BA_ "SysSignalName" SG_ 576 CHL_DisplayCheckcontrolSMBF "CHL_DisplayCheckcontrolSMBF";
BA_ "CompuMethodName" SG_ 576 NumberCheckcontrolSMBF "NumberCheckcontrolSM";
BA_ "ISignalName" SG_ 576 NumberCheckcontrolSMBF "NumberCheckcontrolSMBF";
BA_ "LongName" SG_ 576 NumberCheckcontrolSMBF "NumberCheckcontrolSMBF";
BA_ "SysSignalName" SG_ 576 NumberCheckcontrolSMBF "NumberCheckcontrolSMBF";
BA_ "CompuMethodName" SG_ 576 StatusCheckcontrolSMBF "StatusCheckcontrolSM";
BA_ "ISignalName" SG_ 576 StatusCheckcontrolSMBF "StatusCheckcontrolSMBF";
BA_ "LongName" SG_ 576 StatusCheckcontrolSMBF "StatusCheckcontrolSMBF";
BA_ "SysSignalName" SG_ 576 StatusCheckcontrolSMBF "StatusCheckcontrolSMBF";
BA_ "CompuMethodName" SG_ 576 TransmissiontypeCheckcontrolSMBF "TransmissiontypeCheckcontrolSM";
BA_ "ISignalName" SG_ 576 TransmissiontypeCheckcontrolSMBF "TransmissiontypeCheckcontrolSMBF";
BA_ "LongName" SG_ 576 TransmissiontypeCheckcontrolSMBF "TransmissiontypeCheckcontrolSMBF";
BA_ "SysSignalName" SG_ 576 TransmissiontypeCheckcontrolSMBF "TransmissiontypeCheckcontrolSMBF";
BA_ "CompuMethodName" SG_ 576 StatusIndicateCheckcontrolSMBF "StatusIndicateCheckcontrolSM";
BA_ "ISignalName" SG_ 576 StatusIndicateCheckcontrolSMBF "StatusIndicateCheckcontrolSMBF";
BA_ "LongName" SG_ 576 StatusIndicateCheckcontrolSMBF "StatusIndicateCheckcontrolSMBF";
BA_ "SysSignalName" SG_ 576 StatusIndicateCheckcontrolSMBF "StatusIndicateCheckcontrolSMBF";
BA_ "CompuMethodName" SG_ 587 CRC_DisplayCheckcontrolSMBFH "CRC_8";
BA_ "ISignalName" SG_ 587 CRC_DisplayCheckcontrolSMBFH "CRC_DisplayCheckcontrolSMBFH";
BA_ "LongName" SG_ 587 CRC_DisplayCheckcontrolSMBFH "CRC_DisplayCheckcontrolSMBFH";
BA_ "SysSignalName" SG_ 587 CRC_DisplayCheckcontrolSMBFH "CRC_DisplayCheckcontrolSMBFH";
BA_ "CompuMethodName" SG_ 587 ALIV_DisplayCheckcontrolSMBFH "ALIV_4_BIT_UInt";
BA_ "ISignalName" SG_ 587 ALIV_DisplayCheckcontrolSMBFH "ALIV_DisplayCheckcontrolSMBFH";
BA_ "LongName" SG_ 587 ALIV_DisplayCheckcontrolSMBFH "ALIV_DisplayCheckcontrolSMBFH";
BA_ "SysSignalName" SG_ 587 ALIV_DisplayCheckcontrolSMBFH "ALIV_DisplayCheckcontrolSMBFH";
BA_ "CompuMethodName" SG_ 587 CHL_DisplayCheckcontrolSMBFH "CHL_4_UInt";
BA_ "ISignalName" SG_ 587 CHL_DisplayCheckcontrolSMBFH "CHL_DisplayCheckcontrolSMBFH";
BA_ "LongName" SG_ 587 CHL_DisplayCheckcontrolSMBFH "CHL_DisplayCheckcontrolSMBFH";
BA_ "SysSignalName" SG_ 587 CHL_DisplayCheckcontrolSMBFH "CHL_DisplayCheckcontrolSMBFH";
BA_ "CompuMethodName" SG_ 587 NumberCheckcontrolSMBFH "NumberCheckcontrolSM";
BA_ "ISignalName" SG_ 587 NumberCheckcontrolSMBFH "NumberCheckcontrolSMBFH";
BA_ "LongName" SG_ 587 NumberCheckcontrolSMBFH "NumberCheckcontrolSMBFH";
BA_ "SysSignalName" SG_ 587 NumberCheckcontrolSMBFH "NumberCheckcontrolSMBFH";
BA_ "CompuMethodName" SG_ 587 StatusCheckcontrolSMBFH "StatusCheckcontrolSM";
BA_ "ISignalName" SG_ 587 StatusCheckcontrolSMBFH "StatusCheckcontrolSMBFH";
BA_ "LongName" SG_ 587 StatusCheckcontrolSMBFH "StatusCheckcontrolSMBFH";
BA_ "SysSignalName" SG_ 587 StatusCheckcontrolSMBFH "StatusCheckcontrolSMBFH";
BA_ "CompuMethodName" SG_ 587 TransmissiontypeCheckcontrolSMBF "TransmissiontypeCheckcontrolSM";
BA_ "ISignalName" SG_ 587 TransmissiontypeCheckcontrolSMBF "TransmissiontypeCheckcontrolSMBFH";
BA_ "LongName" SG_ 587 TransmissiontypeCheckcontrolSMBF "TransmissiontypeCheckcontrolSMBFH";
BA_ "SysSignalName" SG_ 587 TransmissiontypeCheckcontrolSMBF "TransmissiontypeCheckcontrolSMBFH";
BA_ "SystemSignalLongSymbol" SG_ 587 TransmissiontypeCheckcontrolSMBF "TransmissiontypeCheckcontrolSMBFH";
BA_ "CompuMethodName" SG_ 587 StatusIndicateCheckcontrolSMBFH "StatusIndicateCheckcontrolSM";
BA_ "ISignalName" SG_ 587 StatusIndicateCheckcontrolSMBFH "StatusIndicateCheckcontrolSMBFH";
BA_ "LongName" SG_ 587 StatusIndicateCheckcontrolSMBFH "StatusIndicateCheckcontrolSMBFH";
BA_ "SysSignalName" SG_ 587 StatusIndicateCheckcontrolSMBFH "StatusIndicateCheckcontrolSMBFH";
BA_ "CompuMethodName" SG_ 564 CRC_DisplayCheckcontrolSMFA "CRC_8";
BA_ "ISignalName" SG_ 564 CRC_DisplayCheckcontrolSMFA "CRC_DisplayCheckcontrolSMFA";
BA_ "LongName" SG_ 564 CRC_DisplayCheckcontrolSMFA "CRC_DisplayCheckcontrolSMFA";
BA_ "SysSignalName" SG_ 564 CRC_DisplayCheckcontrolSMFA "CRC_DisplayCheckcontrolSMFA";
BA_ "CompuMethodName" SG_ 564 ALIV_DisplayCheckcontrolSMFA "ALIV_4_BIT_UInt";
BA_ "ISignalName" SG_ 564 ALIV_DisplayCheckcontrolSMFA "ALIV_DisplayCheckcontrolSMFA";
BA_ "LongName" SG_ 564 ALIV_DisplayCheckcontrolSMFA "ALIV_DisplayCheckcontrolSMFA";
BA_ "SysSignalName" SG_ 564 ALIV_DisplayCheckcontrolSMFA "ALIV_DisplayCheckcontrolSMFA";
BA_ "CompuMethodName" SG_ 564 CHL_DisplayCheckcontrolSMFA "CHL_4_UInt";
BA_ "ISignalName" SG_ 564 CHL_DisplayCheckcontrolSMFA "CHL_DisplayCheckcontrolSMFA";
BA_ "LongName" SG_ 564 CHL_DisplayCheckcontrolSMFA "CHL_DisplayCheckcontrolSMFA";
BA_ "SysSignalName" SG_ 564 CHL_DisplayCheckcontrolSMFA "CHL_DisplayCheckcontrolSMFA";
BA_ "CompuMethodName" SG_ 564 NumberCheckcontrolSMFA "NumberCheckcontrolSM";
BA_ "ISignalName" SG_ 564 NumberCheckcontrolSMFA "NumberCheckcontrolSMFA";
BA_ "LongName" SG_ 564 NumberCheckcontrolSMFA "NumberCheckcontrolSMFA";
BA_ "SysSignalName" SG_ 564 NumberCheckcontrolSMFA "NumberCheckcontrolSMFA";
BA_ "CompuMethodName" SG_ 564 StatusCheckcontrolSMFA "StatusCheckcontrolSM";
BA_ "ISignalName" SG_ 564 StatusCheckcontrolSMFA "StatusCheckcontrolSMFA";
BA_ "LongName" SG_ 564 StatusCheckcontrolSMFA "StatusCheckcontrolSMFA";
BA_ "SysSignalName" SG_ 564 StatusCheckcontrolSMFA "StatusCheckcontrolSMFA";
BA_ "CompuMethodName" SG_ 564 TransmissiontypeCheckcontrolSMFA "TransmissiontypeCheckcontrolSM";
BA_ "ISignalName" SG_ 564 TransmissiontypeCheckcontrolSMFA "TransmissiontypeCheckcontrolSMFA";
BA_ "LongName" SG_ 564 TransmissiontypeCheckcontrolSMFA "TransmissiontypeCheckcontrolSMFA";
BA_ "SysSignalName" SG_ 564 TransmissiontypeCheckcontrolSMFA "TransmissiontypeCheckcontrolSMFA";
BA_ "CompuMethodName" SG_ 564 StatusIndicateCheckcontrolSMFA "StatusIndicateCheckcontrolSM";
BA_ "ISignalName" SG_ 564 StatusIndicateCheckcontrolSMFA "StatusIndicateCheckcontrolSMFA";
BA_ "LongName" SG_ 564 StatusIndicateCheckcontrolSMFA "StatusIndicateCheckcontrolSMFA";
BA_ "SysSignalName" SG_ 564 StatusIndicateCheckcontrolSMFA "StatusIndicateCheckcontrolSMFA";
BA_ "CompuMethodName" SG_ 583 CRC_DisplayCheckcontrolSMFAH "CRC_8";
BA_ "ISignalName" SG_ 583 CRC_DisplayCheckcontrolSMFAH "CRC_DisplayCheckcontrolSMFAH";
BA_ "LongName" SG_ 583 CRC_DisplayCheckcontrolSMFAH "CRC_DisplayCheckcontrolSMFAH";
BA_ "SysSignalName" SG_ 583 CRC_DisplayCheckcontrolSMFAH "CRC_DisplayCheckcontrolSMFAH";
BA_ "CompuMethodName" SG_ 583 ALIV_DisplayCheckcontrolSMFAH "ALIV_4_BIT_UInt";
BA_ "ISignalName" SG_ 583 ALIV_DisplayCheckcontrolSMFAH "ALIV_DisplayCheckcontrolSMFAH";
BA_ "LongName" SG_ 583 ALIV_DisplayCheckcontrolSMFAH "ALIV_DisplayCheckcontrolSMFAH";
BA_ "SysSignalName" SG_ 583 ALIV_DisplayCheckcontrolSMFAH "ALIV_DisplayCheckcontrolSMFAH";
BA_ "CompuMethodName" SG_ 583 CHL_DisplayCheckcontrolSMFAH "CHL_4_UInt";
BA_ "ISignalName" SG_ 583 CHL_DisplayCheckcontrolSMFAH "CHL_DisplayCheckcontrolSMFAH";
BA_ "LongName" SG_ 583 CHL_DisplayCheckcontrolSMFAH "CHL_DisplayCheckcontrolSMFAH";
BA_ "SysSignalName" SG_ 583 CHL_DisplayCheckcontrolSMFAH "CHL_DisplayCheckcontrolSMFAH";
BA_ "CompuMethodName" SG_ 583 NumberCheckcontrolSMFAH "NumberCheckcontrolSM";
BA_ "ISignalName" SG_ 583 NumberCheckcontrolSMFAH "NumberCheckcontrolSMFAH";
BA_ "LongName" SG_ 583 NumberCheckcontrolSMFAH "NumberCheckcontrolSMFAH";
BA_ "SysSignalName" SG_ 583 NumberCheckcontrolSMFAH "NumberCheckcontrolSMFAH";
BA_ "CompuMethodName" SG_ 583 StatusCheckcontrolSMFAH "StatusCheckcontrolSM";
BA_ "ISignalName" SG_ 583 StatusCheckcontrolSMFAH "StatusCheckcontrolSMFAH";
BA_ "LongName" SG_ 583 StatusCheckcontrolSMFAH "StatusCheckcontrolSMFAH";
BA_ "SysSignalName" SG_ 583 StatusCheckcontrolSMFAH "StatusCheckcontrolSMFAH";
BA_ "CompuMethodName" SG_ 583 TransmissiontypeCheckcontrolSMFA "TransmissiontypeCheckcontrolSM";
BA_ "ISignalName" SG_ 583 TransmissiontypeCheckcontrolSMFA "TransmissiontypeCheckcontrolSMFAH";
BA_ "LongName" SG_ 583 TransmissiontypeCheckcontrolSMFA "TransmissiontypeCheckcontrolSMFAH";
BA_ "SysSignalName" SG_ 583 TransmissiontypeCheckcontrolSMFA "TransmissiontypeCheckcontrolSMFAH";
BA_ "SystemSignalLongSymbol" SG_ 583 TransmissiontypeCheckcontrolSMFA "TransmissiontypeCheckcontrolSMFAH";
BA_ "CompuMethodName" SG_ 583 StatusIndicateCheckcontrolSMFAH "StatusIndicateCheckcontrolSM";
BA_ "ISignalName" SG_ 583 StatusIndicateCheckcontrolSMFAH "StatusIndicateCheckcontrolSMFAH";
BA_ "LongName" SG_ 583 StatusIndicateCheckcontrolSMFAH "StatusIndicateCheckcontrolSMFAH";
BA_ "SysSignalName" SG_ 583 StatusIndicateCheckcontrolSMFAH "StatusIndicateCheckcontrolSMFAH";
BA_ "CompuMethodName" SG_ 1174 DisplayRefillVolumeWaterInjectio "DisplayRefillVolumeWaterInjection";
BA_ "ISignalName" SG_ 1174 DisplayRefillVolumeWaterInjectio "DisplayRefillVolumeWaterInjection";
BA_ "LongName" SG_ 1174 DisplayRefillVolumeWaterInjectio "DisplayRefillVolumeWaterInjection";
BA_ "SysSignalName" SG_ 1174 DisplayRefillVolumeWaterInjectio "DisplayRefillVolumeWaterInjection";
BA_ "SystemSignalLongSymbol" SG_ 1174 DisplayRefillVolumeWaterInjectio "DisplayRefillVolumeWaterInjection";
BA_ "CompuMethodName" SG_ 1174 DisplayFluidLevelWaterInjection "DisplayFluidLevelWaterInjection";
BA_ "ISignalName" SG_ 1174 DisplayFluidLevelWaterInjection "DisplayFluidLevelWaterInjection";
BA_ "LongName" SG_ 1174 DisplayFluidLevelWaterInjection "DisplayFluidLevelWaterInjection";
BA_ "SysSignalName" SG_ 1174 DisplayFluidLevelWaterInjection "DisplayFluidLevelWaterInjection";
BA_ "CompuMethodName" SG_ 1174 DispAvailabilityWaterInjection "DispAvailabilityWaterInjection";
BA_ "ISignalName" SG_ 1174 DispAvailabilityWaterInjection "DispAvailabilityWaterInjection";
BA_ "LongName" SG_ 1174 DispAvailabilityWaterInjection "DispAvailabilityWaterInjection";
BA_ "SysSignalName" SG_ 1174 DispAvailabilityWaterInjection "DispAvailabilityWaterInjection";
BA_ "CompuMethodName" SG_ 180 CTR_ECU_CHAS "CTR_ECU_CHAS";
BA_ "ISignalName" SG_ 180 CTR_ECU_CHAS "CTR_ECU_CHAS";
BA_ "LongName" SG_ 180 CTR_ECU_CHAS "Steuerung_STG_Fahrwerk";
BA_ "SysSignalName" SG_ 180 CTR_ECU_CHAS "CTR_ECU_CHAS";
BA_ "CompuMethodName" SG_ 182 CTR_ECU_ENTAI "CTR_ECU_ENTAI";
BA_ "ISignalName" SG_ 182 CTR_ECU_ENTAI "CTR_ECU_ENTAI";
BA_ "LongName" SG_ 182 CTR_ECU_ENTAI "Steuerung_STG_Entertainment";
BA_ "SysSignalName" SG_ 182 CTR_ECU_ENTAI "CTR_ECU_ENTAI";
BA_ "CompuMethodName" SG_ 759 LANG "LANG";
BA_ "ISignalName" SG_ 759 LANG "LANG";
BA_ "LongName" SG_ 759 LANG "Sprache";
BA_ "SysSignalName" SG_ 759 LANG "LANG";
BA_ "CompuMethodName" SG_ 759 UN_DATE "UN_DATE";
BA_ "ISignalName" SG_ 759 UN_DATE "UN_DATE";
BA_ "LongName" SG_ 759 UN_DATE "Einheit_Datum";
BA_ "SysSignalName" SG_ 759 UN_DATE "UN_DATE";
BA_ "CompuMethodName" SG_ 759 UN_T "UN_T";
BA_ "ISignalName" SG_ 759 UN_T "UN_T";
BA_ "LongName" SG_ 759 UN_T "unit-of-measurement_time";
BA_ "SysSignalName" SG_ 759 UN_T "UN_T";
BA_ "CompuMethodName" SG_ 759 UN_TEMP "UN_TEMP";
BA_ "ISignalName" SG_ 759 UN_TEMP "UN_TEMP";
BA_ "LongName" SG_ 759 UN_TEMP "Einheit_Temperatur";
BA_ "SysSignalName" SG_ 759 UN_TEMP "UN_TEMP";
BA_ "CompuMethodName" SG_ 759 UN_SPDM_DGTL "UN_SPDM_DGTL";
BA_ "ISignalName" SG_ 759 UN_SPDM_DGTL "UN_SPDM_DGTL";
BA_ "LongName" SG_ 759 UN_SPDM_DGTL "Einheit_Tacho_Digital";
BA_ "SysSignalName" SG_ 759 UN_SPDM_DGTL "UN_SPDM_DGTL";
BA_ "CompuMethodName" SG_ 759 UN_COSP "UN_COSP";
BA_ "ISignalName" SG_ 759 UN_COSP "UN_COSP";
BA_ "LongName" SG_ 759 UN_COSP "Einheit_Verbrauch";
BA_ "SysSignalName" SG_ 759 UN_COSP "UN_COSP";
BA_ "CompuMethodName" SG_ 759 UN_FU "UN_FU";
BA_ "ISignalName" SG_ 759 UN_FU "UN_FU";
BA_ "LongName" SG_ 759 UN_FU "Einheit_Kraftstoff";
BA_ "SysSignalName" SG_ 759 UN_FU "UN_FU";
BA_ "CompuMethodName" SG_ 759 UN_MILE "UN_MILE";
BA_ "ISignalName" SG_ 759 UN_MILE "UN_MILE";
BA_ "LongName" SG_ 759 UN_MILE "unit-of-measurement_mileage";
BA_ "SysSignalName" SG_ 759 UN_MILE "UN_MILE";
BA_ "CompuMethodName" SG_ 759 UN_AIP "UN_AIP";
BA_ "ISignalName" SG_ 759 UN_AIP "UN_AIP";
BA_ "LongName" SG_ 759 UN_AIP "Einheit_Luftdruck";
BA_ "SysSignalName" SG_ 759 UN_AIP "UN_AIP";
BA_ "CompuMethodName" SG_ 759 UN_DATE_EXT "OP_UN_DATE_EXT";
BA_ "ISignalName" SG_ 759 UN_DATE_EXT "UN_DATE_EXT";
BA_ "LongName" SG_ 759 UN_DATE_EXT "Einheit_Datum_Erweitert";
BA_ "SysSignalName" SG_ 759 UN_DATE_EXT "UN_DATE_EXT";
BA_ "CompuMethodName" SG_ 759 UN_PWR_S_MOD "UN_PWR_S_MOD";
BA_ "ISignalName" SG_ 759 UN_PWR_S_MOD "UN_PWR_S_MOD";
BA_ "LongName" SG_ 759 UN_PWR_S_MOD "Einheit_Leistung_Sport_Modus";
BA_ "SysSignalName" SG_ 759 UN_PWR_S_MOD "UN_PWR_S_MOD";
BA_ "CompuMethodName" SG_ 759 UN_TORQ_S_MOD "UN_TORQ_S_MOD";
BA_ "ISignalName" SG_ 759 UN_TORQ_S_MOD "UN_TORQ_S_MOD";
BA_ "LongName" SG_ 759 UN_TORQ_S_MOD "Einheit_Drehmoment_Sport_Modus";
BA_ "SysSignalName" SG_ 759 UN_TORQ_S_MOD "UN_TORQ_S_MOD";
BA_ "CompuMethodName" SG_ 759 UN_COSP_EL "UN_COSP_EL";
BA_ "ISignalName" SG_ 759 UN_COSP_EL "UN_COSP_EL";
BA_ "LongName" SG_ 759 UN_COSP_EL "Einheit_Verbrauch_Elektrisch";
BA_ "SysSignalName" SG_ 759 UN_COSP_EL "UN_COSP_EL";
BA_ "CompuMethodName" SG_ 589 CTR_ERRM_BN_U "CTR_ERRM_BN_U";
BA_ "ISignalName" SG_ 589 CTR_ERRM_BN_U "CTR_ERRM_BN_U";
BA_ "LongName" SG_ 589 CTR_ERRM_BN_U "Steuerung_Fehlerspeicher_Bordnetz_Spannung";
BA_ "SysSignalName" SG_ 589 CTR_ERRM_BN_U "CTR_ERRM_BN_U";
BA_ "CompuMethodName" SG_ 139 EwsGearbox0 "EWS_BEV";
BA_ "ISignalName" SG_ 139 EwsGearbox0 "EwsGearbox0";
BA_ "LongName" SG_ 139 EwsGearbox0 "EwsGearbox0";
BA_ "SysSignalName" SG_ 139 EwsGearbox0 "EwsGearbox0";
BA_ "CompuMethodName" SG_ 139 EwsGearbox1 "EWS_BEV";
BA_ "ISignalName" SG_ 139 EwsGearbox1 "EwsGearbox1";
BA_ "LongName" SG_ 139 EwsGearbox1 "EwsGearbox1";
BA_ "SysSignalName" SG_ 139 EwsGearbox1 "EwsGearbox1";
BA_ "CompuMethodName" SG_ 139 EwsGearbox2 "EWS_BEV";
BA_ "ISignalName" SG_ 139 EwsGearbox2 "EwsGearbox2";
BA_ "LongName" SG_ 139 EwsGearbox2 "EwsGearbox2";
BA_ "SysSignalName" SG_ 139 EwsGearbox2 "EwsGearbox2";
BA_ "CompuMethodName" SG_ 139 EwsGearbox3 "EWS_BEV";
BA_ "ISignalName" SG_ 139 EwsGearbox3 "EwsGearbox3";
BA_ "LongName" SG_ 139 EwsGearbox3 "EwsGearbox3";
BA_ "SysSignalName" SG_ 139 EwsGearbox3 "EwsGearbox3";
BA_ "CompuMethodName" SG_ 139 EwsGearbox4 "EWS_BEV";
BA_ "ISignalName" SG_ 139 EwsGearbox4 "EwsGearbox4";
BA_ "LongName" SG_ 139 EwsGearbox4 "EwsGearbox4";
BA_ "SysSignalName" SG_ 139 EwsGearbox4 "EwsGearbox4";
BA_ "CompuMethodName" SG_ 139 EwsGearbox5 "EWS_BEV";
BA_ "ISignalName" SG_ 139 EwsGearbox5 "EwsGearbox5";
BA_ "LongName" SG_ 139 EwsGearbox5 "EwsGearbox5";
BA_ "SysSignalName" SG_ 139 EwsGearbox5 "EwsGearbox5";
BA_ "CompuMethodName" SG_ 139 EwsGearbox6 "EWS_BEV";
BA_ "ISignalName" SG_ 139 EwsGearbox6 "EwsGearbox6";
BA_ "LongName" SG_ 139 EwsGearbox6 "EwsGearbox6";
BA_ "SysSignalName" SG_ 139 EwsGearbox6 "EwsGearbox6";
BA_ "CompuMethodName" SG_ 139 EwsGearbox7 "EWS_BEV";
BA_ "ISignalName" SG_ 139 EwsGearbox7 "EwsGearbox7";
BA_ "LongName" SG_ 139 EwsGearbox7 "EwsGearbox7";
BA_ "SysSignalName" SG_ 139 EwsGearbox7 "EwsGearbox7";
BA_ "CompuMethodName" SG_ 135 EwsGearboxAnswer0 "EWS_BEV";
BA_ "ISignalName" SG_ 135 EwsGearboxAnswer0 "EwsGearboxAnswer0";
BA_ "LongName" SG_ 135 EwsGearboxAnswer0 "EwsGearboxAnswer0";
BA_ "SysSignalName" SG_ 135 EwsGearboxAnswer0 "EwsGearboxAnswer0";
BA_ "CompuMethodName" SG_ 135 EwsGearboxAnswer1 "EWS_BEV";
BA_ "ISignalName" SG_ 135 EwsGearboxAnswer1 "EwsGearboxAnswer1";
BA_ "LongName" SG_ 135 EwsGearboxAnswer1 "EwsGearboxAnswer1";
BA_ "SysSignalName" SG_ 135 EwsGearboxAnswer1 "EwsGearboxAnswer1";
BA_ "CompuMethodName" SG_ 135 EwsGearboxAnswer2 "EWS_BEV";
BA_ "ISignalName" SG_ 135 EwsGearboxAnswer2 "EwsGearboxAnswer2";
BA_ "LongName" SG_ 135 EwsGearboxAnswer2 "EwsGearboxAnswer2";
BA_ "SysSignalName" SG_ 135 EwsGearboxAnswer2 "EwsGearboxAnswer2";
BA_ "CompuMethodName" SG_ 135 EwsGearboxAnswer3 "EWS_BEV";
BA_ "ISignalName" SG_ 135 EwsGearboxAnswer3 "EwsGearboxAnswer3";
BA_ "LongName" SG_ 135 EwsGearboxAnswer3 "EwsGearboxAnswer3";
BA_ "SysSignalName" SG_ 135 EwsGearboxAnswer3 "EwsGearboxAnswer3";
BA_ "CompuMethodName" SG_ 135 EwsGearboxAnswer4 "EWS_BEV";
BA_ "ISignalName" SG_ 135 EwsGearboxAnswer4 "EwsGearboxAnswer4";
BA_ "LongName" SG_ 135 EwsGearboxAnswer4 "EwsGearboxAnswer4";
BA_ "SysSignalName" SG_ 135 EwsGearboxAnswer4 "EwsGearboxAnswer4";
BA_ "CompuMethodName" SG_ 135 EwsGearboxAnswer5 "EWS_BEV";
BA_ "ISignalName" SG_ 135 EwsGearboxAnswer5 "EwsGearboxAnswer5";
BA_ "LongName" SG_ 135 EwsGearboxAnswer5 "EwsGearboxAnswer5";
BA_ "SysSignalName" SG_ 135 EwsGearboxAnswer5 "EwsGearboxAnswer5";
BA_ "CompuMethodName" SG_ 135 EwsGearboxAnswer6 "EWS_BEV";
BA_ "ISignalName" SG_ 135 EwsGearboxAnswer6 "EwsGearboxAnswer6";
BA_ "LongName" SG_ 135 EwsGearboxAnswer6 "EwsGearboxAnswer6";
BA_ "SysSignalName" SG_ 135 EwsGearboxAnswer6 "EwsGearboxAnswer6";
BA_ "CompuMethodName" SG_ 135 EwsGearboxAnswer7 "EWS_BEV";
BA_ "ISignalName" SG_ 135 EwsGearboxAnswer7 "EwsGearboxAnswer7";
BA_ "LongName" SG_ 135 EwsGearboxAnswer7 "EwsGearboxAnswer7";
BA_ "SysSignalName" SG_ 135 EwsGearboxAnswer7 "EwsGearboxAnswer7";
BA_ "CompuMethodName" SG_ 224 EwsInverter48No0 "EwsInverter48No0";
BA_ "ISignalName" SG_ 224 EwsInverter48No0 "EwsInverter48No0";
BA_ "LongName" SG_ 224 EwsInverter48No0 "EwsInverter48No0";
BA_ "SysSignalName" SG_ 224 EwsInverter48No0 "EwsInverter48No0";
BA_ "CompuMethodName" SG_ 224 EwsInverter48No1 "EwsInverter48No0";
BA_ "ISignalName" SG_ 224 EwsInverter48No1 "EwsInverter48No1";
BA_ "LongName" SG_ 224 EwsInverter48No1 "EwsInverter48No1";
BA_ "SysSignalName" SG_ 224 EwsInverter48No1 "EwsInverter48No1";
BA_ "CompuMethodName" SG_ 224 EwsInverter48No2 "EwsInverter48No0";
BA_ "ISignalName" SG_ 224 EwsInverter48No2 "EwsInverter48No2";
BA_ "LongName" SG_ 224 EwsInverter48No2 "EwsInverter48No2";
BA_ "SysSignalName" SG_ 224 EwsInverter48No2 "EwsInverter48No2";
BA_ "CompuMethodName" SG_ 224 EwsInverter48No3 "EwsInverter48No0";
BA_ "ISignalName" SG_ 224 EwsInverter48No3 "EwsInverter48No3";
BA_ "LongName" SG_ 224 EwsInverter48No3 "EwsInverter48No3";
BA_ "SysSignalName" SG_ 224 EwsInverter48No3 "EwsInverter48No3";
BA_ "CompuMethodName" SG_ 224 EwsInverter48No4 "EwsInverter48No0";
BA_ "ISignalName" SG_ 224 EwsInverter48No4 "EwsInverter48No4";
BA_ "LongName" SG_ 224 EwsInverter48No4 "EwsInverter48No4";
BA_ "SysSignalName" SG_ 224 EwsInverter48No4 "EwsInverter48No4";
BA_ "CompuMethodName" SG_ 224 EwsInverter48No5 "EwsInverter48No0";
BA_ "ISignalName" SG_ 224 EwsInverter48No5 "EwsInverter48No5";
BA_ "LongName" SG_ 224 EwsInverter48No5 "EwsInverter48No5";
BA_ "SysSignalName" SG_ 224 EwsInverter48No5 "EwsInverter48No5";
BA_ "CompuMethodName" SG_ 224 EwsInverter48No6 "EwsInverter48No0";
BA_ "ISignalName" SG_ 224 EwsInverter48No6 "EwsInverter48No6";
BA_ "LongName" SG_ 224 EwsInverter48No6 "EwsInverter48No6";
BA_ "SysSignalName" SG_ 224 EwsInverter48No6 "EwsInverter48No6";
BA_ "CompuMethodName" SG_ 224 EwsInverter48No7 "EwsInverter48No0";
BA_ "ISignalName" SG_ 224 EwsInverter48No7 "EwsInverter48No7";
BA_ "LongName" SG_ 224 EwsInverter48No7 "EwsInverter48No7";
BA_ "SysSignalName" SG_ 224 EwsInverter48No7 "EwsInverter48No7";
BA_ "CompuMethodName" SG_ 253 EwsInverter48Answer0 "EwsInverter48No0";
BA_ "ISignalName" SG_ 253 EwsInverter48Answer0 "EwsInverter48Answer0";
BA_ "LongName" SG_ 253 EwsInverter48Answer0 "EwsInverter48Answer0";
BA_ "SysSignalName" SG_ 253 EwsInverter48Answer0 "EwsInverter48Answer0";
BA_ "CompuMethodName" SG_ 253 EwsInverter48Answer1 "EwsInverter48No0";
BA_ "ISignalName" SG_ 253 EwsInverter48Answer1 "EwsInverter48Answer1";
BA_ "LongName" SG_ 253 EwsInverter48Answer1 "EwsInverter48Answer1";
BA_ "SysSignalName" SG_ 253 EwsInverter48Answer1 "EwsInverter48Answer1";
BA_ "CompuMethodName" SG_ 253 EwsInverter48Answer2 "EwsInverter48No0";
BA_ "ISignalName" SG_ 253 EwsInverter48Answer2 "EwsInverter48Answer2";
BA_ "LongName" SG_ 253 EwsInverter48Answer2 "EwsInverter48Answer2";
BA_ "SysSignalName" SG_ 253 EwsInverter48Answer2 "EwsInverter48Answer2";
BA_ "CompuMethodName" SG_ 253 EwsInverter48Answer3 "EwsInverter48No0";
BA_ "ISignalName" SG_ 253 EwsInverter48Answer3 "EwsInverter48Answer3";
BA_ "LongName" SG_ 253 EwsInverter48Answer3 "EwsInverter48Answer3";
BA_ "SysSignalName" SG_ 253 EwsInverter48Answer3 "EwsInverter48Answer3";
BA_ "CompuMethodName" SG_ 253 EwsInverter48Answer4 "EwsInverter48No0";
BA_ "ISignalName" SG_ 253 EwsInverter48Answer4 "EwsInverter48Answer4";
BA_ "LongName" SG_ 253 EwsInverter48Answer4 "EwsInverter48Answer4";
BA_ "SysSignalName" SG_ 253 EwsInverter48Answer4 "EwsInverter48Answer4";
BA_ "CompuMethodName" SG_ 253 EwsInverter48Answer5 "EwsInverter48No0";
BA_ "ISignalName" SG_ 253 EwsInverter48Answer5 "EwsInverter48Answer5";
BA_ "LongName" SG_ 253 EwsInverter48Answer5 "EwsInverter48Answer5";
BA_ "SysSignalName" SG_ 253 EwsInverter48Answer5 "EwsInverter48Answer5";
BA_ "CompuMethodName" SG_ 253 EwsInverter48Answer6 "EwsInverter48No0";
BA_ "ISignalName" SG_ 253 EwsInverter48Answer6 "EwsInverter48Answer6";
BA_ "LongName" SG_ 253 EwsInverter48Answer6 "EwsInverter48Answer6";
BA_ "SysSignalName" SG_ 253 EwsInverter48Answer6 "EwsInverter48Answer6";
BA_ "CompuMethodName" SG_ 253 EwsInverter48Answer7 "EwsInverter48No0";
BA_ "ISignalName" SG_ 253 EwsInverter48Answer7 "EwsInverter48Answer7";
BA_ "LongName" SG_ 253 EwsInverter48Answer7 "EwsInverter48Answer7";
BA_ "SysSignalName" SG_ 253 EwsInverter48Answer7 "EwsInverter48Answer7";
BA_ "CompuMethodName" SG_ 140 EwsEngine1_0 "EWS_BEV";
BA_ "ISignalName" SG_ 140 EwsEngine1_0 "EwsEngine1_0";
BA_ "LongName" SG_ 140 EwsEngine1_0 "EwsEngine1_0";
BA_ "SysSignalName" SG_ 140 EwsEngine1_0 "EwsEngine1_0";
BA_ "CompuMethodName" SG_ 140 EwsEngine1_1 "EWS_BEV";
BA_ "ISignalName" SG_ 140 EwsEngine1_1 "EwsEngine1_1";
BA_ "LongName" SG_ 140 EwsEngine1_1 "EwsEngine1_1";
BA_ "SysSignalName" SG_ 140 EwsEngine1_1 "EwsEngine1_1";
BA_ "CompuMethodName" SG_ 140 EwsEngine1_2 "EWS_BEV";
BA_ "ISignalName" SG_ 140 EwsEngine1_2 "EwsEngine1_2";
BA_ "LongName" SG_ 140 EwsEngine1_2 "EwsEngine1_2";
BA_ "SysSignalName" SG_ 140 EwsEngine1_2 "EwsEngine1_2";
BA_ "CompuMethodName" SG_ 140 EwsEngine1_3 "EWS_BEV";
BA_ "ISignalName" SG_ 140 EwsEngine1_3 "EwsEngine1_3";
BA_ "LongName" SG_ 140 EwsEngine1_3 "EwsEngine1_3";
BA_ "SysSignalName" SG_ 140 EwsEngine1_3 "EwsEngine1_3";
BA_ "CompuMethodName" SG_ 140 EwsEngine1_4 "EWS_BEV";
BA_ "ISignalName" SG_ 140 EwsEngine1_4 "EwsEngine1_4";
BA_ "LongName" SG_ 140 EwsEngine1_4 "EwsEngine1_4";
BA_ "SysSignalName" SG_ 140 EwsEngine1_4 "EwsEngine1_4";
BA_ "CompuMethodName" SG_ 140 EwsEngine1_5 "EWS_BEV";
BA_ "ISignalName" SG_ 140 EwsEngine1_5 "EwsEngine1_5";
BA_ "LongName" SG_ 140 EwsEngine1_5 "EwsEngine1_5";
BA_ "SysSignalName" SG_ 140 EwsEngine1_5 "EwsEngine1_5";
BA_ "CompuMethodName" SG_ 140 EwsEngine1_6 "EWS_BEV";
BA_ "ISignalName" SG_ 140 EwsEngine1_6 "EwsEngine1_6";
BA_ "LongName" SG_ 140 EwsEngine1_6 "EwsEngine1_6";
BA_ "SysSignalName" SG_ 140 EwsEngine1_6 "EwsEngine1_6";
BA_ "CompuMethodName" SG_ 140 EwsEngine1_7 "EWS_BEV";
BA_ "ISignalName" SG_ 140 EwsEngine1_7 "EwsEngine1_7";
BA_ "LongName" SG_ 140 EwsEngine1_7 "EwsEngine1_7";
BA_ "SysSignalName" SG_ 140 EwsEngine1_7 "EwsEngine1_7";
BA_ "CompuMethodName" SG_ 144 EwsEngine1answer0 "EWS_BEV";
BA_ "ISignalName" SG_ 144 EwsEngine1answer0 "EwsEngine1answer0";
BA_ "LongName" SG_ 144 EwsEngine1answer0 "EwsEngine1answer0";
BA_ "SysSignalName" SG_ 144 EwsEngine1answer0 "EwsEngine1answer0";
BA_ "CompuMethodName" SG_ 144 EwsEngine1answer1 "EWS_BEV";
BA_ "ISignalName" SG_ 144 EwsEngine1answer1 "EwsEngine1answer1";
BA_ "LongName" SG_ 144 EwsEngine1answer1 "EwsEngine1answer1";
BA_ "SysSignalName" SG_ 144 EwsEngine1answer1 "EwsEngine1answer1";
BA_ "CompuMethodName" SG_ 144 EwsEngine1answer2 "EWS_BEV";
BA_ "ISignalName" SG_ 144 EwsEngine1answer2 "EwsEngine1answer2";
BA_ "LongName" SG_ 144 EwsEngine1answer2 "EwsEngine1answer2";
BA_ "SysSignalName" SG_ 144 EwsEngine1answer2 "EwsEngine1answer2";
BA_ "CompuMethodName" SG_ 144 EwsEngine1answer3 "EWS_BEV";
BA_ "ISignalName" SG_ 144 EwsEngine1answer3 "EwsEngine1answer3";
BA_ "LongName" SG_ 144 EwsEngine1answer3 "EwsEngine1answer3";
BA_ "SysSignalName" SG_ 144 EwsEngine1answer3 "EwsEngine1answer3";
BA_ "CompuMethodName" SG_ 144 EwsEngine1answer4 "EWS_BEV";
BA_ "ISignalName" SG_ 144 EwsEngine1answer4 "EwsEngine1answer4";
BA_ "LongName" SG_ 144 EwsEngine1answer4 "EwsEngine1answer4";
BA_ "SysSignalName" SG_ 144 EwsEngine1answer4 "EwsEngine1answer4";
BA_ "CompuMethodName" SG_ 144 EwsEngine1answer5 "EWS_BEV";
BA_ "ISignalName" SG_ 144 EwsEngine1answer5 "EwsEngine1answer5";
BA_ "LongName" SG_ 144 EwsEngine1answer5 "EwsEngine1answer5";
BA_ "SysSignalName" SG_ 144 EwsEngine1answer5 "EwsEngine1answer5";
BA_ "CompuMethodName" SG_ 144 EwsEngine1answer6 "EWS_BEV";
BA_ "ISignalName" SG_ 144 EwsEngine1answer6 "EwsEngine1answer6";
BA_ "LongName" SG_ 144 EwsEngine1answer6 "EwsEngine1answer6";
BA_ "SysSignalName" SG_ 144 EwsEngine1answer6 "EwsEngine1answer6";
BA_ "CompuMethodName" SG_ 144 EwsEngine1answer7 "EWS_BEV";
BA_ "ISignalName" SG_ 144 EwsEngine1answer7 "EwsEngine1answer7";
BA_ "LongName" SG_ 144 EwsEngine1answer7 "EwsEngine1answer7";
BA_ "SysSignalName" SG_ 144 EwsEngine1answer7 "EwsEngine1answer7";
BA_ "CompuMethodName" SG_ 162 EwsEngine2_0 "EWS_BEV";
BA_ "ISignalName" SG_ 162 EwsEngine2_0 "EwsEngine2_0";
BA_ "LongName" SG_ 162 EwsEngine2_0 "EwsEngine2_0";
BA_ "SysSignalName" SG_ 162 EwsEngine2_0 "EwsEngine2_0";
BA_ "CompuMethodName" SG_ 162 EwsEngine2_1 "EWS_BEV";
BA_ "ISignalName" SG_ 162 EwsEngine2_1 "EwsEngine2_1";
BA_ "LongName" SG_ 162 EwsEngine2_1 "EwsEngine2_1";
BA_ "SysSignalName" SG_ 162 EwsEngine2_1 "EwsEngine2_1";
BA_ "CompuMethodName" SG_ 162 EwsEngine2_2 "EWS_BEV";
BA_ "ISignalName" SG_ 162 EwsEngine2_2 "EwsEngine2_2";
BA_ "LongName" SG_ 162 EwsEngine2_2 "EwsEngine2_2";
BA_ "SysSignalName" SG_ 162 EwsEngine2_2 "EwsEngine2_2";
BA_ "CompuMethodName" SG_ 162 EwsEngine2_3 "EWS_BEV";
BA_ "ISignalName" SG_ 162 EwsEngine2_3 "EwsEngine2_3";
BA_ "LongName" SG_ 162 EwsEngine2_3 "EwsEngine2_3";
BA_ "SysSignalName" SG_ 162 EwsEngine2_3 "EwsEngine2_3";
BA_ "CompuMethodName" SG_ 162 EwsEngine2_4 "EWS_BEV";
BA_ "ISignalName" SG_ 162 EwsEngine2_4 "EwsEngine2_4";
BA_ "LongName" SG_ 162 EwsEngine2_4 "EwsEngine2_4";
BA_ "SysSignalName" SG_ 162 EwsEngine2_4 "EwsEngine2_4";
BA_ "CompuMethodName" SG_ 162 EwsEngine2_5 "EWS_BEV";
BA_ "ISignalName" SG_ 162 EwsEngine2_5 "EwsEngine2_5";
BA_ "LongName" SG_ 162 EwsEngine2_5 "EwsEngine2_5";
BA_ "SysSignalName" SG_ 162 EwsEngine2_5 "EwsEngine2_5";
BA_ "CompuMethodName" SG_ 162 EwsEngine2_6 "EWS_BEV";
BA_ "ISignalName" SG_ 162 EwsEngine2_6 "EwsEngine2_6";
BA_ "LongName" SG_ 162 EwsEngine2_6 "EwsEngine2_6";
BA_ "SysSignalName" SG_ 162 EwsEngine2_6 "EwsEngine2_6";
BA_ "CompuMethodName" SG_ 162 EwsEngine2_7 "EWS_BEV";
BA_ "ISignalName" SG_ 162 EwsEngine2_7 "EwsEngine2_7";
BA_ "LongName" SG_ 162 EwsEngine2_7 "EwsEngine2_7";
BA_ "SysSignalName" SG_ 162 EwsEngine2_7 "EwsEngine2_7";
BA_ "CompuMethodName" SG_ 163 EwsEngine2answer0 "EWS_BEV";
BA_ "ISignalName" SG_ 163 EwsEngine2answer0 "EwsEngine2answer0";
BA_ "LongName" SG_ 163 EwsEngine2answer0 "EwsEngine2answer0";
BA_ "SysSignalName" SG_ 163 EwsEngine2answer0 "EwsEngine2answer0";
BA_ "CompuMethodName" SG_ 163 EwsEngine2answer1 "EWS_BEV";
BA_ "ISignalName" SG_ 163 EwsEngine2answer1 "EwsEngine2answer1";
BA_ "LongName" SG_ 163 EwsEngine2answer1 "EwsEngine2answer1";
BA_ "SysSignalName" SG_ 163 EwsEngine2answer1 "EwsEngine2answer1";
BA_ "CompuMethodName" SG_ 163 EwsEngine2answer2 "EWS_BEV";
BA_ "ISignalName" SG_ 163 EwsEngine2answer2 "EwsEngine2answer2";
BA_ "LongName" SG_ 163 EwsEngine2answer2 "EwsEngine2answer2";
BA_ "SysSignalName" SG_ 163 EwsEngine2answer2 "EwsEngine2answer2";
BA_ "CompuMethodName" SG_ 163 EwsEngine2answer3 "EWS_BEV";
BA_ "ISignalName" SG_ 163 EwsEngine2answer3 "EwsEngine2answer3";
BA_ "LongName" SG_ 163 EwsEngine2answer3 "EwsEngine2answer3";
BA_ "SysSignalName" SG_ 163 EwsEngine2answer3 "EwsEngine2answer3";
BA_ "CompuMethodName" SG_ 163 EwsEngine2answer4 "EWS_BEV";
BA_ "ISignalName" SG_ 163 EwsEngine2answer4 "EwsEngine2answer4";
BA_ "LongName" SG_ 163 EwsEngine2answer4 "EwsEngine2answer4";
BA_ "SysSignalName" SG_ 163 EwsEngine2answer4 "EwsEngine2answer4";
BA_ "CompuMethodName" SG_ 163 EwsEngine2answer5 "EWS_BEV";
BA_ "ISignalName" SG_ 163 EwsEngine2answer5 "EwsEngine2answer5";
BA_ "LongName" SG_ 163 EwsEngine2answer5 "EwsEngine2answer5";
BA_ "SysSignalName" SG_ 163 EwsEngine2answer5 "EwsEngine2answer5";
BA_ "CompuMethodName" SG_ 163 EwsEngine2answer6 "EWS_BEV";
BA_ "ISignalName" SG_ 163 EwsEngine2answer6 "EwsEngine2answer6";
BA_ "LongName" SG_ 163 EwsEngine2answer6 "EwsEngine2answer6";
BA_ "SysSignalName" SG_ 163 EwsEngine2answer6 "EwsEngine2answer6";
BA_ "CompuMethodName" SG_ 163 EwsEngine2answer7 "EWS_BEV";
BA_ "ISignalName" SG_ 163 EwsEngine2answer7 "EwsEngine2answer7";
BA_ "LongName" SG_ 163 EwsEngine2answer7 "EwsEngine2answer7";
BA_ "SysSignalName" SG_ 163 EwsEngine2answer7 "EwsEngine2answer7";
BA_ "CompuMethodName" SG_ 148 EWS_GLB_0 "EWS_BEV";
BA_ "ISignalName" SG_ 148 EWS_GLB_0 "EWS_GLB_0";
BA_ "LongName" SG_ 148 EWS_GLB_0 "EWS_Global_0";
BA_ "SysSignalName" SG_ 148 EWS_GLB_0 "EWS_GLB_0";
BA_ "CompuMethodName" SG_ 148 EWS_GLB_1 "EWS_BEV";
BA_ "ISignalName" SG_ 148 EWS_GLB_1 "EWS_GLB_1";
BA_ "LongName" SG_ 148 EWS_GLB_1 "EWS_Global_1";
BA_ "SysSignalName" SG_ 148 EWS_GLB_1 "EWS_GLB_1";
BA_ "CompuMethodName" SG_ 148 EWS_GLB_2 "EWS_BEV";
BA_ "ISignalName" SG_ 148 EWS_GLB_2 "EWS_GLB_2";
BA_ "LongName" SG_ 148 EWS_GLB_2 "EWS_Global_2";
BA_ "SysSignalName" SG_ 148 EWS_GLB_2 "EWS_GLB_2";
BA_ "CompuMethodName" SG_ 148 EWS_GLB_3 "EWS_BEV";
BA_ "ISignalName" SG_ 148 EWS_GLB_3 "EWS_GLB_3";
BA_ "LongName" SG_ 148 EWS_GLB_3 "EWS_Global_3";
BA_ "SysSignalName" SG_ 148 EWS_GLB_3 "EWS_GLB_3";
BA_ "CompuMethodName" SG_ 148 EWS_GLB_4 "EWS_BEV";
BA_ "ISignalName" SG_ 148 EWS_GLB_4 "EWS_GLB_4";
BA_ "LongName" SG_ 148 EWS_GLB_4 "EWS_Global_4";
BA_ "SysSignalName" SG_ 148 EWS_GLB_4 "EWS_GLB_4";
BA_ "CompuMethodName" SG_ 148 EWS_GLB_5 "EWS_BEV";
BA_ "ISignalName" SG_ 148 EWS_GLB_5 "EWS_GLB_5";
BA_ "LongName" SG_ 148 EWS_GLB_5 "EWS_global_5";
BA_ "SysSignalName" SG_ 148 EWS_GLB_5 "EWS_GLB_5";
BA_ "CompuMethodName" SG_ 148 EWS_GLB_6 "EWS_BEV";
BA_ "ISignalName" SG_ 148 EWS_GLB_6 "EWS_GLB_6";
BA_ "LongName" SG_ 148 EWS_GLB_6 "EWS_Global_6";
BA_ "SysSignalName" SG_ 148 EWS_GLB_6 "EWS_GLB_6";
BA_ "CompuMethodName" SG_ 148 EWS_GLB_7 "EWS_BEV";
BA_ "ISignalName" SG_ 148 EWS_GLB_7 "EWS_GLB_7";
BA_ "LongName" SG_ 148 EWS_GLB_7 "EWS_Global_7";
BA_ "SysSignalName" SG_ 148 EWS_GLB_7 "EWS_GLB_7";
BA_ "CompuMethodName" SG_ 896 NO_VECH_1 "NO_VECH_1";
BA_ "ISignalName" SG_ 896 NO_VECH_1 "NO_VECH_1";
BA_ "LongName" SG_ 896 NO_VECH_1 "Nummer_Fahrgestell_1";
BA_ "SysSignalName" SG_ 896 NO_VECH_1 "NO_VECH_1";
BA_ "CompuMethodName" SG_ 896 NO_VECH_2 "NO_VECH_2";
BA_ "ISignalName" SG_ 896 NO_VECH_2 "NO_VECH_2";
BA_ "LongName" SG_ 896 NO_VECH_2 "Nummer_Fahrgestell_2";
BA_ "SysSignalName" SG_ 896 NO_VECH_2 "NO_VECH_2";
BA_ "CompuMethodName" SG_ 896 NO_VECH_3 "NO_VECH_3";
BA_ "ISignalName" SG_ 896 NO_VECH_3 "NO_VECH_3";
BA_ "LongName" SG_ 896 NO_VECH_3 "Nummer_Fahrgestell_3";
BA_ "SysSignalName" SG_ 896 NO_VECH_3 "NO_VECH_3";
BA_ "CompuMethodName" SG_ 896 NO_VECH_4 "NO_VECH_4";
BA_ "ISignalName" SG_ 896 NO_VECH_4 "NO_VECH_4";
BA_ "LongName" SG_ 896 NO_VECH_4 "Nummer_Fahrgestell_4";
BA_ "SysSignalName" SG_ 896 NO_VECH_4 "NO_VECH_4";
BA_ "CompuMethodName" SG_ 896 NO_VECH_5 "NO_VECH_5";
BA_ "ISignalName" SG_ 896 NO_VECH_5 "NO_VECH_5";
BA_ "LongName" SG_ 896 NO_VECH_5 "Nummer_Fahrgestell_5";
BA_ "SysSignalName" SG_ 896 NO_VECH_5 "NO_VECH_5";
BA_ "CompuMethodName" SG_ 896 NO_VECH_6 "NO_VECH_6";
BA_ "ISignalName" SG_ 896 NO_VECH_6 "NO_VECH_6";
BA_ "LongName" SG_ 896 NO_VECH_6 "Nummer_Fahrgestell_6";
BA_ "SysSignalName" SG_ 896 NO_VECH_6 "NO_VECH_6";
BA_ "CompuMethodName" SG_ 896 NO_VECH_7 "NO_VECH_7";
BA_ "ISignalName" SG_ 896 NO_VECH_7 "NO_VECH_7";
BA_ "LongName" SG_ 896 NO_VECH_7 "Nummer_Fahrgestell_7";
BA_ "SysSignalName" SG_ 896 NO_VECH_7 "NO_VECH_7";
BA_ "CompuMethodName" SG_ 904 TYP_VEH "TYP_VEH";
BA_ "ISignalName" SG_ 904 TYP_VEH "TYP_VEH";
BA_ "LongName" SG_ 904 TYP_VEH "Typ_Fahrzeug";
BA_ "SysSignalName" SG_ 904 TYP_VEH "TYP_VEH";
BA_ "CompuMethodName" SG_ 904 TYP_BODY "TYP_BODY";
BA_ "ISignalName" SG_ 904 TYP_BODY "TYP_BODY";
BA_ "LongName" SG_ 904 TYP_BODY "Typ_Karosserie";
BA_ "SysSignalName" SG_ 904 TYP_BODY "TYP_BODY";
BA_ "CompuMethodName" SG_ 904 QUAN_CYL "QUAN_CYL";
BA_ "ISignalName" SG_ 904 QUAN_CYL "QUAN_CYL";
BA_ "LongName" SG_ 904 QUAN_CYL "Anzahl_Zylinder";
BA_ "SysSignalName" SG_ 904 QUAN_CYL "QUAN_CYL";
BA_ "CompuMethodName" SG_ 904 QUAN_GR "QUAN_GR";
BA_ "ISignalName" SG_ 904 QUAN_GR "QUAN_GR";
BA_ "LongName" SG_ 904 QUAN_GR "Anzahl_Gang";
BA_ "SysSignalName" SG_ 904 QUAN_GR "QUAN_GR";
BA_ "CompuMethodName" SG_ 904 TYP_ENG "TYP_ENG";
BA_ "ISignalName" SG_ 904 TYP_ENG "TYP_ENG";
BA_ "LongName" SG_ 904 TYP_ENG "Typ_Motor";
BA_ "SysSignalName" SG_ 904 TYP_ENG "TYP_ENG";
BA_ "CompuMethodName" SG_ 904 TYP_STE "TYP_STE";
BA_ "ISignalName" SG_ 904 TYP_STE "TYP_STE";
BA_ "LongName" SG_ 904 TYP_STE "Typ_Lenkung";
BA_ "SysSignalName" SG_ 904 TYP_STE "TYP_STE";
BA_ "CompuMethodName" SG_ 904 TYP_GRB "TYP_GRB";
BA_ "ISignalName" SG_ 904 TYP_GRB "TYP_GRB";
BA_ "LongName" SG_ 904 TYP_GRB "Typ_Getriebe";
BA_ "SysSignalName" SG_ 904 TYP_GRB "TYP_GRB";
BA_ "CompuMethodName" SG_ 904 CLAS_PWR "CLAS_PWR";
BA_ "ISignalName" SG_ 904 CLAS_PWR "CLAS_PWR";
BA_ "LongName" SG_ 904 CLAS_PWR "Klasse_Leistung";
BA_ "SysSignalName" SG_ 904 CLAS_PWR "CLAS_PWR";
BA_ "CompuMethodName" SG_ 904 TYP_CNT "TYP_CNT";
BA_ "ISignalName" SG_ 904 TYP_CNT "TYP_CNT";
BA_ "LongName" SG_ 904 TYP_CNT "Typ_Land";
BA_ "SysSignalName" SG_ 904 TYP_CNT "TYP_CNT";
BA_ "CompuMethodName" SG_ 904 TYP_CAPA "TYP_CAPA";
BA_ "ISignalName" SG_ 904 TYP_CAPA "TYP_CAPA";
BA_ "LongName" SG_ 904 TYP_CAPA "Typ_Hubraum";
BA_ "SysSignalName" SG_ 904 TYP_CAPA "TYP_CAPA";
BA_ "CompuMethodName" SG_ 1103 RSU_RLS_FLLUP_FEPM "RSU_RLS_FLLUP_FEPM";
BA_ "GenSigStartValue" SG_ 1103 RSU_RLS_FLLUP_FEPM 1;
BA_ "ISignalName" SG_ 1103 RSU_RLS_FLLUP_FEPM "RSU_RLS_FLLUP_FEPM";
BA_ "LongName" SG_ 1103 RSU_RLS_FLLUP_FEPM "RSU_Freigabe_Nachlauf_FEPM";
BA_ "SysSignalName" SG_ 1103 RSU_RLS_FLLUP_FEPM "RSU_RLS_FLLUP_FEPM";
BA_ "CompuMethodName" SG_ 1103 RSU_RREF_FLLUP_FEPM "RSU_RREF_FLLUP_FEPM";
BA_ "ISignalName" SG_ 1103 RSU_RREF_FLLUP_FEPM "RSU_RREF_FLLUP_FEPM";
BA_ "LongName" SG_ 1103 RSU_RREF_FLLUP_FEPM "RSU_Ablehnungsgrund_Nachlauf_FEPM";
BA_ "SysSignalName" SG_ 1103 RSU_RREF_FLLUP_FEPM "RSU_RREF_FLLUP_FEPM";
BA_ "CompuMethodName" SG_ 1103 RSU_DCHG_COU_BN_BT "RSU_DCHG_COU_BN_BT";
BA_ "GenSigStartValue" SG_ 1103 RSU_DCHG_COU_BN_BT 1;
BA_ "ISignalName" SG_ 1103 RSU_DCHG_COU_BN_BT "RSU_DCHG_COU_BN_BT";
BA_ "LongName" SG_ 1103 RSU_DCHG_COU_BN_BT "RSU_Entladung_Zähler_Bordnetz_Batterie";
BA_ "SysSignalName" SG_ 1103 RSU_DCHG_COU_BN_BT "RSU_DCHG_COU_BN_BT";
BA_ "CompuMethodName" SG_ 1103 ST_ENSU "ST_ENSU";
BA_ "ISignalName" SG_ 1103 ST_ENSU "ST_ENSU";
BA_ "LongName" SG_ 1103 ST_ENSU "status_energy-supply";
BA_ "SysSignalName" SG_ 1103 ST_ENSU "ST_ENSU";
BA_ "CompuMethodName" SG_ 1102 RSU_RQ_FLLUP_FEPM "RSU_RQ_FLLUP_FEPM";
BA_ "GenSigStartValue" SG_ 1102 RSU_RQ_FLLUP_FEPM 1;
BA_ "ISignalName" SG_ 1102 RSU_RQ_FLLUP_FEPM "RSU_RQ_FLLUP_FEPM";
BA_ "LongName" SG_ 1102 RSU_RQ_FLLUP_FEPM "RSU_Anforderung_Nachlauf_FEPM";
BA_ "SysSignalName" SG_ 1102 RSU_RQ_FLLUP_FEPM "RSU_RQ_FLLUP_FEPM";
BA_ "CompuMethodName" SG_ 1102 RSU_ST_FLSH_RSLT "RSU_ST_FLSH_RSLT";
BA_ "ISignalName" SG_ 1102 RSU_ST_FLSH_RSLT "RSU_ST_FLSH_RSLT";
BA_ "LongName" SG_ 1102 RSU_ST_FLSH_RSLT "RSU_Status_Flash_Ergebnis";
BA_ "SysSignalName" SG_ 1102 RSU_ST_FLSH_RSLT "RSU_ST_FLSH_RSLT";
BA_ "CompuMethodName" SG_ 958 FLLUPT_GPWSUP "FollowupTimePowerSupply";
BA_ "ISignalName" SG_ 958 FLLUPT_GPWSUP "FLLUPT_GPWSUP";
BA_ "LongName" SG_ 958 FLLUPT_GPWSUP "Nachlaufzeit_Stromversorgung";
BA_ "SysSignalName" SG_ 958 FLLUPT_GPWSUP "FLLUPT_GPWSUP";
BA_ "CompuMethodName" SG_ 940 FLLUPT_KL_30_ERCTR "FLLUPT_KL_30_ERCTR";
BA_ "ISignalName" SG_ 940 FLLUPT_KL_30_ERCTR "FLLUPT_KL_30_ERCTR";
BA_ "LongName" SG_ 940 FLLUPT_KL_30_ERCTR "Nachlaufzeit_Klemme_30_fehlergesteuert";
BA_ "SysSignalName" SG_ 940 FLLUPT_KL_30_ERCTR "FLLUPT_KL_30_ERCTR";
BA_ "CompuMethodName" SG_ 940 TYP_DSCO_KL_30_ERCTR "TYP_DSCO_KL_30_ERCTR";
BA_ "ISignalName" SG_ 940 TYP_DSCO_KL_30_ERCTR "TYP_DSCO_KL_30_ERCTR";
BA_ "LongName" SG_ 940 TYP_DSCO_KL_30_ERCTR "Typ_Trennung_Klemme_30_fehlergesteuert";
BA_ "SysSignalName" SG_ 940 TYP_DSCO_KL_30_ERCTR "TYP_DSCO_KL_30_ERCTR";
BA_ "CompuMethodName" SG_ 586 FRC_AIC_PWR_RETA_MOD_1 "FRC_AIC_PWR_RETA_MOD";
BA_ "ISignalName" SG_ 586 FRC_AIC_PWR_RETA_MOD_1 "FRC_AIC_PWR_RETA_MOD_1";
BA_ "LongName" SG_ 586 FRC_AIC_PWR_RETA_MOD_1 "Prognose_Klima_Leistung_Halten_Modus_1";
BA_ "SysSignalName" SG_ 586 FRC_AIC_PWR_RETA_MOD_1 "FRC_AIC_PWR_RETA_MOD_1";
BA_ "CompuMethodName" SG_ 586 FRC_AIC_PWR_RETA_MOD_2 "FRC_AIC_PWR_RETA_MOD";
BA_ "ISignalName" SG_ 586 FRC_AIC_PWR_RETA_MOD_2 "FRC_AIC_PWR_RETA_MOD_2";
BA_ "LongName" SG_ 586 FRC_AIC_PWR_RETA_MOD_2 "Prognose_Klima_Leistung_Halten_Modus_2";
BA_ "SysSignalName" SG_ 586 FRC_AIC_PWR_RETA_MOD_2 "FRC_AIC_PWR_RETA_MOD_2";
BA_ "CompuMethodName" SG_ 586 FRC_AIC_PWR_RETA_MOD_3 "FRC_AIC_PWR_RETA_MOD";
BA_ "ISignalName" SG_ 586 FRC_AIC_PWR_RETA_MOD_3 "FRC_AIC_PWR_RETA_MOD_3";
BA_ "LongName" SG_ 586 FRC_AIC_PWR_RETA_MOD_3 "Prognose_Klima_Leistung_Halten_Modus_3";
BA_ "SysSignalName" SG_ 586 FRC_AIC_PWR_RETA_MOD_3 "FRC_AIC_PWR_RETA_MOD_3";
BA_ "CompuMethodName" SG_ 586 FRC_AIC_ENERG_CLDWN_HTUP_MOD_1 "FRC_AIC_PWR_RETA_MOD";
BA_ "ISignalName" SG_ 586 FRC_AIC_ENERG_CLDWN_HTUP_MOD_1 "FRC_AIC_ENERG_CLDWN_HTUP_MOD_1";
BA_ "LongName" SG_ 586 FRC_AIC_ENERG_CLDWN_HTUP_MOD_1 "Prognose_Klima_Energie_Abkühlung_Aufheizung_Modus_1";
BA_ "SysSignalName" SG_ 586 FRC_AIC_ENERG_CLDWN_HTUP_MOD_1 "FRC_AIC_ENERG_CLDWN_HTUP_MOD_1";
BA_ "CompuMethodName" SG_ 586 FRC_AIC_ENERG_CLDWN_HTUP_MOD_2 "FRC_AIC_PWR_RETA_MOD";
BA_ "ISignalName" SG_ 586 FRC_AIC_ENERG_CLDWN_HTUP_MOD_2 "FRC_AIC_ENERG_CLDWN_HTUP_MOD_2";
BA_ "LongName" SG_ 586 FRC_AIC_ENERG_CLDWN_HTUP_MOD_2 "Prognose_Klima_Energie_Abkühlung_Aufheizung_Modus_2";
BA_ "SysSignalName" SG_ 586 FRC_AIC_ENERG_CLDWN_HTUP_MOD_2 "FRC_AIC_ENERG_CLDWN_HTUP_MOD_2";
BA_ "CompuMethodName" SG_ 586 FRC_AIC_ENERG_CLDWN_HTUP_MOD_3 "FRC_AIC_PWR_RETA_MOD";
BA_ "ISignalName" SG_ 586 FRC_AIC_ENERG_CLDWN_HTUP_MOD_3 "FRC_AIC_ENERG_CLDWN_HTUP_MOD_3";
BA_ "LongName" SG_ 586 FRC_AIC_ENERG_CLDWN_HTUP_MOD_3 "forecast_air-conditioning_Energy_cool-down_heat-up_mode_3";
BA_ "SysSignalName" SG_ 586 FRC_AIC_ENERG_CLDWN_HTUP_MOD_3 "FRC_AIC_ENERG_CLDWN_HTUP_MOD_3";
BA_ "CompuMethodName" SG_ 586 COU_OP_AIC "FBK_OP_AIC";
BA_ "ISignalName" SG_ 586 COU_OP_AIC "COU_OP_AIC";
BA_ "LongName" SG_ 586 COU_OP_AIC "Zähler_Bedienung_Klima";
BA_ "SysSignalName" SG_ 586 COU_OP_AIC "COU_OP_AIC";
BA_ "CompuMethodName" SG_ 970 FRC_AVR_HVSTO_PWR "FRC_AVR_HVSTO_PWR";
BA_ "ISignalName" SG_ 970 FRC_AVR_HVSTO_PWR "FRC_AVR_HVSTO_PWR";
BA_ "LongName" SG_ 970 FRC_AVR_HVSTO_PWR "Prognose_Durchschnitt_Hochvoltspeicher_Leistung";
BA_ "SysSignalName" SG_ 970 FRC_AVR_HVSTO_PWR "FRC_AVR_HVSTO_PWR";
BA_ "CompuMethodName" SG_ 970 AVLB_HVSTO_NET "AVLB_HVSTO_NET";
BA_ "ISignalName" SG_ 970 AVLB_HVSTO_NET "AVLB_HVSTO_NET";
BA_ "LongName" SG_ 970 AVLB_HVSTO_NET "Verfügbar_Hochvoltspeicher_Netto";
BA_ "SysSignalName" SG_ 970 AVLB_HVSTO_NET "AVLB_HVSTO_NET";
BA_ "CompuMethodName" SG_ 970 FRC_AUXC_EVEH "FRC_AUXC_EVEH";
BA_ "ISignalName" SG_ 970 FRC_AUXC_EVEH "FRC_AUXC_EVEH";
BA_ "LongName" SG_ 970 FRC_AUXC_EVEH "Prognose_Nebenverbraucher_Elektrisches-Fahrzeug";
BA_ "SysSignalName" SG_ 970 FRC_AUXC_EVEH "FRC_AUXC_EVEH";
BA_ "CompuMethodName" SG_ 970 FRC_AUXC_HYB "FRC_AUXC_HYB";
BA_ "ISignalName" SG_ 970 FRC_AUXC_HYB "FRC_AUXC_HYB";
BA_ "LongName" SG_ 970 FRC_AUXC_HYB "Prognose_Nebenverbraucher_Hybrid";
BA_ "SysSignalName" SG_ 970 FRC_AUXC_HYB "FRC_AUXC_HYB";
BA_ "CompuMethodName" SG_ 970 SYNCN_FRC_RD_INFO "SYNCN_FRC_RD_INFO";
BA_ "ISignalName" SG_ 970 SYNCN_FRC_RD_INFO "SYNCN_FRC_RD_INFO";
BA_ "LongName" SG_ 970 SYNCN_FRC_RD_INFO "synchronization_forecast_ride_information";
BA_ "SysSignalName" SG_ 970 SYNCN_FRC_RD_INFO "SYNCN_FRC_RD_INFO";
BA_ "CompuMethodName" SG_ 970 MUX_FRC_RD_INFO "MUX_FRC_RD_INFO";
BA_ "ISignalName" SG_ 970 MUX_FRC_RD_INFO "MUX_FRC_RD_INFO";
BA_ "LongName" SG_ 970 MUX_FRC_RD_INFO "Multiplexer_Prognose_Fahrt_Information";
BA_ "SysSignalName" SG_ 970 MUX_FRC_RD_INFO "MUX_FRC_RD_INFO";
BA_ "CompuMethodName" SG_ 967 OP_MESS_RT_CHNG "OP_MESS_RT_CHNG";
BA_ "ISignalName" SG_ 967 OP_MESS_RT_CHNG "OP_MESS_RT_CHNG";
BA_ "LongName" SG_ 967 OP_MESS_RT_CHNG "Bedienung_Meldung_Route_Änderung";
BA_ "SysSignalName" SG_ 967 OP_MESS_RT_CHNG "OP_MESS_RT_CHNG";
BA_ "CompuMethodName" SG_ 967 MUX_FRC_RT_DSTN "MUX_FRC_RT_DSTN";
BA_ "ISignalName" SG_ 967 MUX_FRC_RT_DSTN "MUX_FRC_RT_DSTN";
BA_ "LongName" SG_ 967 MUX_FRC_RT_DSTN "Multiplexer_Prognose_Route_Ziel";
BA_ "SysSignalName" SG_ 967 MUX_FRC_RT_DSTN "MUX_FRC_RT_DSTN";
BA_ "CompuMethodName" SG_ 967 FRC_RT_DUR_DSTN "FRC_RT_DUR_DSTN";
BA_ "ISignalName" SG_ 967 FRC_RT_DUR_DSTN "FRC_RT_DUR_DSTN";
BA_ "LongName" SG_ 967 FRC_RT_DUR_DSTN "Prognose_Route_Dauer_Ziel";
BA_ "SysSignalName" SG_ 967 FRC_RT_DUR_DSTN "FRC_RT_DUR_DSTN";
BA_ "CompuMethodName" SG_ 967 FRC_RT_AVR_V "FRC_RT_AVR_V";
BA_ "ISignalName" SG_ 967 FRC_RT_AVR_V "FRC_RT_AVR_V";
BA_ "LongName" SG_ 967 FRC_RT_AVR_V "Prognose_Route_Durchschnitt_Geschwindigkeit";
BA_ "SysSignalName" SG_ 967 FRC_RT_AVR_V "FRC_RT_AVR_V";
BA_ "CompuMethodName" SG_ 967 FRC_RT_AVR_COSP_TRCT "FRC_RT_AVR_COSP_TRCT";
BA_ "ISignalName" SG_ 967 FRC_RT_AVR_COSP_TRCT "FRC_RT_AVR_COSP_TRCT";
BA_ "LongName" SG_ 967 FRC_RT_AVR_COSP_TRCT "Prognose_Route_Durchschnitt_Verbrauch_Traktion";
BA_ "SysSignalName" SG_ 967 FRC_RT_AVR_COSP_TRCT "FRC_RT_AVR_COSP_TRCT";
BA_ "CompuMethodName" SG_ 928 ST_ENERG_FZM "ST_ENERG_FZM";
BA_ "ISignalName" SG_ 928 ST_ENERG_FZM "ST_ENERG_FZM";
BA_ "LongName" SG_ 928 ST_ENERG_FZM "Status_Energie_FZM";
BA_ "SysSignalName" SG_ 928 ST_ENERG_FZM "ST_ENERG_FZM";
BA_ "CompuMethodName" SG_ 928 ST_ILK_ERRM_FZM "ST_ILK_ERRM_FZM";
BA_ "ISignalName" SG_ 928 ST_ILK_ERRM_FZM "ST_ILK_ERRM_FZM";
BA_ "LongName" SG_ 928 ST_ILK_ERRM_FZM "Status_Sperre_Fehlerspeicher_FZM";
BA_ "SysSignalName" SG_ 928 ST_ILK_ERRM_FZM "ST_ILK_ERRM_FZM";
BA_ "CompuMethodName" SG_ 620 GO_PY_AVAI "GO_PY_AVAI";
BA_ "ISignalName" SG_ 620 GO_PY_AVAI "GO_PY_AVAI";
BA_ "LongName" SG_ 620 GO_PY_AVAI "Gong_Player_Verfügbarkeit";
BA_ "SysSignalName" SG_ 620 GO_PY_AVAI "GO_PY_AVAI";
BA_ "CompuMethodName" SG_ 1039 SEC_GPS_CAN "SEC_GPS";
BA_ "ISignalName" SG_ 1039 SEC_GPS_CAN "SEC_GPS_CAN";
BA_ "LongName" SG_ 1039 SEC_GPS_CAN "Sekunde_GPS_CAN";
BA_ "SysSignalName" SG_ 1039 SEC_GPS_CAN "SEC_GPS_CAN";
BA_ "CompuMethodName" SG_ 1039 MN_GPS_CAN "MN_GPS";
BA_ "ISignalName" SG_ 1039 MN_GPS_CAN "MN_GPS_CAN";
BA_ "LongName" SG_ 1039 MN_GPS_CAN "Minute_GPS_CAN";
BA_ "SysSignalName" SG_ 1039 MN_GPS_CAN "MN_GPS_CAN";
BA_ "CompuMethodName" SG_ 1039 HR_GPS_CAN "HR_GPS";
BA_ "ISignalName" SG_ 1039 HR_GPS_CAN "HR_GPS_CAN";
BA_ "LongName" SG_ 1039 HR_GPS_CAN "Stunde_GPS_CAN";
BA_ "SysSignalName" SG_ 1039 HR_GPS_CAN "HR_GPS_CAN";
BA_ "CompuMethodName" SG_ 1039 SRC_GPS_CTI_CAN "SRC_GPS_CTI_CAN";
BA_ "ISignalName" SG_ 1039 SRC_GPS_CTI_CAN "SRC_GPS_CTI_CAN";
BA_ "LongName" SG_ 1039 SRC_GPS_CTI_CAN "Quelle_GPS_Uhrzeit_CAN";
BA_ "SysSignalName" SG_ 1039 SRC_GPS_CTI_CAN "SRC_GPS_CTI_CAN";
BA_ "CompuMethodName" SG_ 1111 SEC_GPS_MOST "SEC_GPS";
BA_ "ISignalName" SG_ 1111 SEC_GPS_MOST "SEC_GPS_MOST";
BA_ "LongName" SG_ 1111 SEC_GPS_MOST "Sekunde_GPS_MOST";
BA_ "SysSignalName" SG_ 1111 SEC_GPS_MOST "SEC_GPS_MOST";
BA_ "CompuMethodName" SG_ 1111 MN_GPS_MOST "MN_GPS";
BA_ "ISignalName" SG_ 1111 MN_GPS_MOST "MN_GPS_MOST";
BA_ "LongName" SG_ 1111 MN_GPS_MOST "Minute_GPS_MOST";
BA_ "SysSignalName" SG_ 1111 MN_GPS_MOST "MN_GPS_MOST";
BA_ "CompuMethodName" SG_ 1111 HR_GPS_MOST "HR_GPS";
BA_ "ISignalName" SG_ 1111 HR_GPS_MOST "HR_GPS_MOST";
BA_ "LongName" SG_ 1111 HR_GPS_MOST "Stunde_GPS_MOST";
BA_ "SysSignalName" SG_ 1111 HR_GPS_MOST "HR_GPS_MOST";
BA_ "CompuMethodName" SG_ 1111 SRC_GPS_CTI_MOST "SRC_GPS_CTI_MOST";
BA_ "ISignalName" SG_ 1111 SRC_GPS_CTI_MOST "SRC_GPS_CTI_MOST";
BA_ "LongName" SG_ 1111 SRC_GPS_CTI_MOST "Quelle_GPS_Uhrzeit_MOST";
BA_ "SysSignalName" SG_ 1111 SRC_GPS_CTI_MOST "SRC_GPS_CTI_MOST";
BA_ "CompuMethodName" SG_ 1041 SEC_GPS_MOST "SEC_GPS";
BA_ "ISignalName" SG_ 1041 SEC_GPS_MOST "SEC_GPS_MOST";
BA_ "LongName" SG_ 1041 SEC_GPS_MOST "Sekunde_GPS_MOST";
BA_ "SysSignalName" SG_ 1041 SEC_GPS_MOST "SEC_GPS_MOST";
BA_ "CompuMethodName" SG_ 1041 MN_GPS_MOST "MN_GPS";
BA_ "ISignalName" SG_ 1041 MN_GPS_MOST "MN_GPS_MOST";
BA_ "LongName" SG_ 1041 MN_GPS_MOST "Minute_GPS_MOST";
BA_ "SysSignalName" SG_ 1041 MN_GPS_MOST "MN_GPS_MOST";
BA_ "CompuMethodName" SG_ 1041 HR_GPS_MOST "HR_GPS";
BA_ "ISignalName" SG_ 1041 HR_GPS_MOST "HR_GPS_MOST";
BA_ "LongName" SG_ 1041 HR_GPS_MOST "Stunde_GPS_MOST";
BA_ "SysSignalName" SG_ 1041 HR_GPS_MOST "HR_GPS_MOST";
BA_ "CompuMethodName" SG_ 1041 SRC_GPS_CTI_MOST "SRC_GPS_CTI_MOST";
BA_ "ISignalName" SG_ 1041 SRC_GPS_CTI_MOST "SRC_GPS_CTI_MOST";
BA_ "LongName" SG_ 1041 SRC_GPS_CTI_MOST "Quelle_GPS_Uhrzeit_MOST";
BA_ "SysSignalName" SG_ 1041 SRC_GPS_CTI_MOST "SRC_GPS_CTI_MOST";
BA_ "CompuMethodName" SG_ 1038 DAY_GPS_CAN "DAY_GPS";
BA_ "ISignalName" SG_ 1038 DAY_GPS_CAN "DAY_GPS_CAN";
BA_ "LongName" SG_ 1038 DAY_GPS_CAN "Tag_GPS_CAN";
BA_ "SysSignalName" SG_ 1038 DAY_GPS_CAN "DAY_GPS_CAN";
BA_ "CompuMethodName" SG_ 1038 MON_GPS_CAN "MON_GPS";
BA_ "ISignalName" SG_ 1038 MON_GPS_CAN "MON_GPS_CAN";
BA_ "LongName" SG_ 1038 MON_GPS_CAN "Monat_GPS_CAN";
BA_ "SysSignalName" SG_ 1038 MON_GPS_CAN "MON_GPS_CAN";
BA_ "CompuMethodName" SG_ 1038 YR_GPS_CAN "YR_GPS";
BA_ "ISignalName" SG_ 1038 YR_GPS_CAN "YR_GPS_CAN";
BA_ "LongName" SG_ 1038 YR_GPS_CAN "Jahr_GPS_CAN";
BA_ "SysSignalName" SG_ 1038 YR_GPS_CAN "YR_GPS_CAN";
BA_ "CompuMethodName" SG_ 1038 SRC_GPS_DATE_CAN "SRC_GPS_DATE_CAN";
BA_ "ISignalName" SG_ 1038 SRC_GPS_DATE_CAN "SRC_GPS_DATE_CAN";
BA_ "LongName" SG_ 1038 SRC_GPS_DATE_CAN "Quelle_GPS_Datum_CAN";
BA_ "SysSignalName" SG_ 1038 SRC_GPS_DATE_CAN "SRC_GPS_DATE_CAN";
BA_ "CompuMethodName" SG_ 1110 DAY_GPS_MOST "DAY_GPS";
BA_ "ISignalName" SG_ 1110 DAY_GPS_MOST "DAY_GPS_MOST";
BA_ "LongName" SG_ 1110 DAY_GPS_MOST "Tag_GPS_MOST";
BA_ "SysSignalName" SG_ 1110 DAY_GPS_MOST "DAY_GPS_MOST";
BA_ "CompuMethodName" SG_ 1110 MON_GPS_MOST "MON_GPS";
BA_ "ISignalName" SG_ 1110 MON_GPS_MOST "MON_GPS_MOST";
BA_ "LongName" SG_ 1110 MON_GPS_MOST "Monat_GPS_MOST";
BA_ "SysSignalName" SG_ 1110 MON_GPS_MOST "MON_GPS_MOST";
BA_ "CompuMethodName" SG_ 1110 YR_GPS_MOST "YR_GPS";
BA_ "ISignalName" SG_ 1110 YR_GPS_MOST "YR_GPS_MOST";
BA_ "LongName" SG_ 1110 YR_GPS_MOST "Jahr_GPS_MOST";
BA_ "SysSignalName" SG_ 1110 YR_GPS_MOST "YR_GPS_MOST";
BA_ "CompuMethodName" SG_ 1110 SRC_GPS_DATE_MOST "SRC_GPS_DATE_MOST";
BA_ "ISignalName" SG_ 1110 SRC_GPS_DATE_MOST "SRC_GPS_DATE_MOST";
BA_ "LongName" SG_ 1110 SRC_GPS_DATE_MOST "Quelle_GPS_Datum_MOST";
BA_ "SysSignalName" SG_ 1110 SRC_GPS_DATE_MOST "SRC_GPS_DATE_MOST";
BA_ "CompuMethodName" SG_ 1040 DAY_GPS_MOST "DAY_GPS";
BA_ "ISignalName" SG_ 1040 DAY_GPS_MOST "DAY_GPS_MOST";
BA_ "LongName" SG_ 1040 DAY_GPS_MOST "Tag_GPS_MOST";
BA_ "SysSignalName" SG_ 1040 DAY_GPS_MOST "DAY_GPS_MOST";
BA_ "CompuMethodName" SG_ 1040 MON_GPS_MOST "MON_GPS";
BA_ "ISignalName" SG_ 1040 MON_GPS_MOST "MON_GPS_MOST";
BA_ "LongName" SG_ 1040 MON_GPS_MOST "Monat_GPS_MOST";
BA_ "SysSignalName" SG_ 1040 MON_GPS_MOST "MON_GPS_MOST";
BA_ "CompuMethodName" SG_ 1040 YR_GPS_MOST "YR_GPS";
BA_ "ISignalName" SG_ 1040 YR_GPS_MOST "YR_GPS_MOST";
BA_ "LongName" SG_ 1040 YR_GPS_MOST "Jahr_GPS_MOST";
BA_ "SysSignalName" SG_ 1040 YR_GPS_MOST "YR_GPS_MOST";
BA_ "CompuMethodName" SG_ 1040 SRC_GPS_DATE_MOST "SRC_GPS_DATE_MOST";
BA_ "ISignalName" SG_ 1040 SRC_GPS_DATE_MOST "SRC_GPS_DATE_MOST";
BA_ "LongName" SG_ 1040 SRC_GPS_DATE_MOST "Quelle_GPS_Datum_MOST";
BA_ "SysSignalName" SG_ 1040 SRC_GPS_DATE_MOST "SRC_GPS_DATE_MOST";
BA_ "CompuMethodName" SG_ 2675460105 GliwaDME1HostTxDummysignal "GliwaDME1HostTxDummysignal";
BA_ "ISignalName" SG_ 2675460105 GliwaDME1HostTxDummysignal "GliwaDME1HostTxDummysignal";
BA_ "LongName" SG_ 2675460105 GliwaDME1HostTxDummysignal "GliwaDME1HostTxDummysignal";
BA_ "SysSignalName" SG_ 2675460105 GliwaDME1HostTxDummysignal "GliwaDME1HostTxDummysignal";
BA_ "CompuMethodName" SG_ 2675460106 GliwaDME1TxDummysignal "GliwaDME1TxDummysignal";
BA_ "ISignalName" SG_ 2675460106 GliwaDME1TxDummysignal "GliwaDME1TxDummysignal";
BA_ "LongName" SG_ 2675460106 GliwaDME1TxDummysignal "GliwaDME1TxDummysignal";
BA_ "SysSignalName" SG_ 2675460106 GliwaDME1TxDummysignal "GliwaDME1TxDummysignal";
BA_ "CompuMethodName" SG_ 2675461120 GliwaDME2HostTxDummysignal "GliwaDME2HostTxDummysignal";
BA_ "ISignalName" SG_ 2675461120 GliwaDME2HostTxDummysignal "GliwaDME2HostTxDummysignal";
BA_ "LongName" SG_ 2675461120 GliwaDME2HostTxDummysignal "GliwaDME2HostTxDummysignal";
BA_ "SysSignalName" SG_ 2675461120 GliwaDME2HostTxDummysignal "GliwaDME2HostTxDummysignal";
BA_ "CompuMethodName" SG_ 2675461121 GliwaDME2TxDummysignal "GliwaDME2TxDummysignal";
BA_ "ISignalName" SG_ 2675461121 GliwaDME2TxDummysignal "GliwaDME2TxDummysignal";
BA_ "LongName" SG_ 2675461121 GliwaDME2TxDummysignal "GliwaDME2TxDummysignal";
BA_ "SysSignalName" SG_ 2675461121 GliwaDME2TxDummysignal "GliwaDME2TxDummysignal";
BA_ "CompuMethodName" SG_ 207 QU_FN_FCM "HDWOBS_QU_FN";
BA_ "ISignalName" SG_ 207 QU_FN_FCM "QU_FN_FCM";
BA_ "LongName" SG_ 207 QU_FN_FCM "Qualifier_Funktion_FCM";
BA_ "SysSignalName" SG_ 207 QU_FN_FCM "QU_FN_FCM";
BA_ "CompuMethodName" SG_ 441 LIM_TORQ_CRSH_ACCM "ACCM_LIM_TORQ";
BA_ "ISignalName" SG_ 441 LIM_TORQ_CRSH_ACCM "LIM_TORQ_CRSH_ACCM";
BA_ "LongName" SG_ 441 LIM_TORQ_CRSH_ACCM "Begrenzung_Drehmoment_Kurbelwelle_Klimakompressor";
BA_ "SysSignalName" SG_ 441 LIM_TORQ_CRSH_ACCM "LIM_TORQ_CRSH_ACCM";
BA_ "CompuMethodName" SG_ 441 RQ_HTFL_DME "Prozent_100_8Bit";
BA_ "ISignalName" SG_ 441 RQ_HTFL_DME "RQ_HTFL_DME";
BA_ "LongName" SG_ 441 RQ_HTFL_DME "Anforderung_Wärmestrom_DME";
BA_ "SysSignalName" SG_ 441 RQ_HTFL_DME "RQ_HTFL_DME";
BA_ "CompuMethodName" SG_ 441 LIM_PWR_ACCM_ENGMG "LIM_PWR_ACCM_ENGMG";
BA_ "ISignalName" SG_ 441 LIM_PWR_ACCM_ENGMG "LIM_PWR_ACCM_ENGMG";
BA_ "LongName" SG_ 441 LIM_PWR_ACCM_ENGMG "Begrenzung_Leistung_Klimakompressor_Motorsteuerung";
BA_ "SysSignalName" SG_ 441 LIM_PWR_ACCM_ENGMG "LIM_PWR_ACCM_ENGMG";
BA_ "CompuMethodName" SG_ 441 RQ_AUWP_DME "RQ_AUWP_DME";
BA_ "ISignalName" SG_ 441 RQ_AUWP_DME "RQ_AUWP_DME";
BA_ "LongName" SG_ 441 RQ_AUWP_DME "Anforderung_Zusatzwasserpumpe_DME";
BA_ "SysSignalName" SG_ 441 RQ_AUWP_DME "RQ_AUWP_DME";
BA_ "CompuMethodName" SG_ 441 ST_BLEED_DME "ST_BLEED_DME";
BA_ "ISignalName" SG_ 441 ST_BLEED_DME "ST_BLEED_DME";
BA_ "LongName" SG_ 441 ST_BLEED_DME "Status_Entlüften_DME";
BA_ "SysSignalName" SG_ 441 ST_BLEED_DME "ST_BLEED_DME";
BA_ "CompuMethodName" SG_ 1067 EnergyDischargeHighVoltageStorag0 "EnergyDischargeHighVoltageStorage";
BA_ "GenSigStartValue" SG_ 1067 EnergyDischargeHighVoltageStorag0 -50;
BA_ "ISignalName" SG_ 1067 EnergyDischargeHighVoltageStorag0 "EnergyDischargeHighVoltageStoragePresentDynamic";
BA_ "LongName" SG_ 1067 EnergyDischargeHighVoltageStorag0 "EnergyDischargeHighVoltageStoragePresentDynamic";
BA_ "SysSignalName" SG_ 1067 EnergyDischargeHighVoltageStorag0 "EnergyDischargeHighVoltageStoragePresentDynamic";
BA_ "SystemSignalLongSymbol" SG_ 1067 EnergyDischargeHighVoltageStorag0 "EnergyDischargeHighVoltageStoragePresentDynamic";
BA_ "CompuMethodName" SG_ 1067 EnergyDischargeHighVoltageStorag1 "EnergyDischargeHighVoltageStorage";
BA_ "GenSigStartValue" SG_ 1067 EnergyDischargeHighVoltageStorag1 -50;
BA_ "ISignalName" SG_ 1067 EnergyDischargeHighVoltageStorag1 "EnergyDischargeHighVoltageStorageMaximalDynamic";
BA_ "LongName" SG_ 1067 EnergyDischargeHighVoltageStorag1 "EnergyDischargeHighVoltageStorageMaximalDynamic";
BA_ "SysSignalName" SG_ 1067 EnergyDischargeHighVoltageStorag1 "EnergyDischargeHighVoltageStorageMaximalDynamic";
BA_ "SystemSignalLongSymbol" SG_ 1067 EnergyDischargeHighVoltageStorag1 "EnergyDischargeHighVoltageStorageMaximalDynamic";
BA_ "CompuMethodName" SG_ 633 DISP_STA_PLG_T_HR "DISP_STA_PLG_T_HR";
BA_ "ISignalName" SG_ 633 DISP_STA_PLG_T_HR "DISP_STA_PLG_T_HR";
BA_ "LongName" SG_ 633 DISP_STA_PLG_T_HR "Anzeige_Start_Stecker_Zeit_Stunde";
BA_ "SysSignalName" SG_ 633 DISP_STA_PLG_T_HR "DISP_STA_PLG_T_HR";
BA_ "CompuMethodName" SG_ 633 DISP_STA_PLG_T_MN "DISP_STA_PLG_T_MN";
BA_ "ISignalName" SG_ 633 DISP_STA_PLG_T_MN "DISP_STA_PLG_T_MN";
BA_ "LongName" SG_ 633 DISP_STA_PLG_T_MN "Anzeige_Start_Stecker_Zeit_Minute";
BA_ "SysSignalName" SG_ 633 DISP_STA_PLG_T_MN "DISP_STA_PLG_T_MN";
BA_ "CompuMethodName" SG_ 633 DISP_STA_PLG_T_WDAY "DISP_STA_PLG_T_WDAY";
BA_ "ISignalName" SG_ 633 DISP_STA_PLG_T_WDAY "DISP_STA_PLG_T_WDAY";
BA_ "LongName" SG_ 633 DISP_STA_PLG_T_WDAY "Anzeige_Start_Stecker_Zeit_Wochentag";
BA_ "SysSignalName" SG_ 633 DISP_STA_PLG_T_WDAY "DISP_STA_PLG_T_WDAY";
BA_ "CompuMethodName" SG_ 633 ST_MAX_EDRV_WARN "ST_MAX_EDRV_WARN";
BA_ "ISignalName" SG_ 633 ST_MAX_EDRV_WARN "ST_MAX_EDRV_WARN";
BA_ "LongName" SG_ 633 ST_MAX_EDRV_WARN "Status_Maximal_E-Fahren_Warnung";
BA_ "SysSignalName" SG_ 633 ST_MAX_EDRV_WARN "ST_MAX_EDRV_WARN";
BA_ "CompuMethodName" SG_ 633 DISP_END_CHGWIN_T_HR "DISP_STA_PLG_T_HR";
BA_ "ISignalName" SG_ 633 DISP_END_CHGWIN_T_HR "DISP_END_CHGWIN_T_HR";
BA_ "LongName" SG_ 633 DISP_END_CHGWIN_T_HR "Anzeige_Ende_Ladefenster_Zeit_Stunde";
BA_ "SysSignalName" SG_ 633 DISP_END_CHGWIN_T_HR "DISP_END_CHGWIN_T_HR";
BA_ "CompuMethodName" SG_ 633 DISP_END_CHGWIN_T_MN "DISP_STA_PLG_T_MN";
BA_ "ISignalName" SG_ 633 DISP_END_CHGWIN_T_MN "DISP_END_CHGWIN_T_MN";
BA_ "LongName" SG_ 633 DISP_END_CHGWIN_T_MN "Anzeige_Ende_Ladefenster_Zeit_Minute";
BA_ "SysSignalName" SG_ 633 DISP_END_CHGWIN_T_MN "DISP_END_CHGWIN_T_MN";
BA_ "CompuMethodName" SG_ 633 DISP_STA_CHGWIN_T_HR "DISP_STA_PLG_T_HR";
BA_ "ISignalName" SG_ 633 DISP_STA_CHGWIN_T_HR "DISP_STA_CHGWIN_T_HR";
BA_ "LongName" SG_ 633 DISP_STA_CHGWIN_T_HR "Anzeige_Start_Ladefenster_Zeit_Stunde";
BA_ "SysSignalName" SG_ 633 DISP_STA_CHGWIN_T_HR "DISP_STA_CHGWIN_T_HR";
BA_ "CompuMethodName" SG_ 633 DISP_STA_CHGWIN_T_MN "DISP_STA_PLG_T_MN";
BA_ "ISignalName" SG_ 633 DISP_STA_CHGWIN_T_MN "DISP_STA_CHGWIN_T_MN";
BA_ "LongName" SG_ 633 DISP_STA_CHGWIN_T_MN "Anzeige_Start_Ladefenster_Zeit_Minute";
BA_ "SysSignalName" SG_ 633 DISP_STA_CHGWIN_T_MN "DISP_STA_CHGWIN_T_MN";
VAL_ 644 ReasonDegradationPowertrain 0 "Keine" 1 "Unspezifisch" 2 "Thermisch" 3 "SOE" 4 "Tank_leer" 5 "Emissionsbedingt" 6 "Safe_share_key" 7 "Zero_Emission_Zone" 13 "SIGNALTAG_FCTIF_NOT_AVAILABLE" 14 "SIGNALTAG_FCT_ERROR" 15 "Sendefunktion nicht in Betrieb";
VAL_ 1062 ST_SAIL_DRV 0 "Anzeige \"Segeln inaktiv\"" 1 "Anzeige \"Segeln inaktiv\"" 2 "Anzeige \"Segeln inaktiv\"" 3 "Anzeige \"Segeln aktiv\"" 4 "Anzeige \"Segeln inaktiv\"" 5 "Gebremstes_Segeln" 13 "Hinweis: Reserviert für funktionale Kennung Signal-Tag." 14 "Hinweis: Reserviert für funktionale Kennung Signal-Tag." 15 "Sendefunktion nicht in Betrieb";
VAL_ 1080 ST_SAIL_DRV 0 "Anzeige \"Segeln inaktiv\"" 1 "Anzeige \"Segeln inaktiv\"" 2 "Anzeige \"Segeln inaktiv\"" 3 "Anzeige \"Segeln aktiv\"" 4 "Anzeige \"Segeln inaktiv\"" 5 "Gebremstes_Segeln" 13 "Hinweis: Reserviert für funktionale Kennung Signal-Tag." 14 "Hinweis: Reserviert für funktionale Kennung Signal-Tag." 15 "Sendefunktion nicht in Betrieb";
VAL_ 849 AVL_CON_BT 0 "Batterie i.O." 1 "Batterie prüfen" 2 "Batterie n.i.O. (tauschen)" 3 "Signal ungültig";
VAL_ 849 ST_CHG_BT 0 "Batterie nicht laden" 1 "Batterie laden" 3 "Signal ungültig";
VAL_ 849 ST_BT_WNG 0 "Zulässige Batterie verbaut" 1 "Unzulässige Batterie verbaut" 3 "Signal ungültig";
VAL_ 849 ST_CEDT 0 "Kein Zelldefekt" 1 "Zelldefekt erkannt" 3 "Signal ungültig";
VAL_ 849 QUAL_CON_BT_CAPE_AVL 0 "Istkapazität nicht zuverlässig ermittelt" 1 "Istkapazität zuverlässig ermittelt" 3 "Signal ungültig";
VAL_ 849 QUAL_CON_BT_CHGCOND 0 "Ladezustand nicht zuverlässig ermittelt" 1 "Ladezustand zuverlässig ermittelt" 3 "Signal ungültig";
VAL_ 849 ST_LSS_WTR 0 "Wasserverlust i.O." 1 "Wasserverlust n.i.O." 3 "Signal ungültig";
VAL_ 849 ST_EXHDCHG 0 "Batterie war nicht tiefenentladen" 1 "Batterie war tiefenentladen" 3 "Signal ungültig";
VAL_ 849 LVBT_PDCHG 65533 "SIGNALTAG_FCTIF_NOT_AVAILABLE" 65534 "SIGNALTAG_FCT_ERROR" 65535 "Sendefunktion nicht in Betrieb";
VAL_ 800 COSP_AVR_EL_BC_1 4093 "Es werden Striche angezeigt." 4094 "Keine_Angabe" 4095 "Sendefunktion nicht in Betrieb";
VAL_ 800 COSP_AVR_EL_BC_2 4093 "Es werden Striche angezeigt." 4094 "Keine_Angabe" 4095 "Sendefunktion nicht in Betrieb";
VAL_ 800 ST_UN_COSP_EL_BC 0 "Default = Keine Angabe" 1 "kWh_100km" 2 "mi_kWh" 3 "Km_kWh" 4 "Wh_km" 5 "Wh_mi" 6 "kWh_per_100mi" 15 "Sendefunktion nicht in Betrieb";
VAL_ 800 COPO_VL_BC 0 "z.B. 555" 1 "z. B. 55,5; (Wertigkeit 10^-1)" 2 "z. B. 5,55; (Wertigkeit 10^-2)" 3 "Sendefunktion nicht in Betrieb";
VAL_ 1021 DISP_GR_GRB 0 "Dunkelschaltung" 1 "1.Gang" 2 "2.Gang" 3 "3.Gang" 4 "4.Gang" 5 "5.Gang" 6 "6.Gang" 7 "7.Gang" 8 "8.Gang" 9 "(wird derzeit nur in Hybridfahrzeugen verwendet)" 15 "Signal ungültig";
VAL_ 1021 DISP_PO_IDC_GRB 0 "Nicht Blinken" 1 "Blinken" 3 "Signal ungültig";
VAL_ 1021 DISP_PO_GRB 0 "Dunkel" 1 "Anzeige dauerhaft" 2 "Anzeige dauerhaft" 3 "Anzeige dauerhaft" 4 "Anzeige dauerhaft" 7 "Signal ungültig";
VAL_ 1021 DISP_SSC_IDC_GRB 0 "Nicht Blinken" 1 "Blinken" 3 "Signal ungültig";
VAL_ 1021 GEN_IDLI 0 "inaktiv" 1 "aktiv" 3 "Signal ungültig";
VAL_ 1021 DISP_RQ_GR_GRB 0 "Dunkelschaltung" 1 "1.Gang" 2 "2.Gang" 3 "3.Gang" 4 "4.Gang" 5 "5.Gang" 6 "6.Gang" 7 "7.Gang" 8 "8.Gang" 9 "(wird derzeit nur in Hybridfahrzeugen verwendet)" 13 "Hinweis: Reserviert für funktionale Kennung Signal-Tag." 14 "Hinweis: Reserviert für funktionale Kennung Signal-Tag." 15 "Sendefunktion nicht in Betrieb";
VAL_ 1021 DISP_DRVLG_GRB 0 "Keine Programmanzeige" 1 "1" 2 "2" 3 "3" 10 "Anzeige des Dünenmodus im RR31" 15 "Signal ungültig";
VAL_ 1021 StatusAvailabilityInterventionPo 0 "Eingriff_nicht_erlaubt_wegen_GWS_Betaetigung" 1 "Getriebeeingriff_erlaubt" 2 "Getriebeeingriff_nicht_erlaubt" 3 "Sendefunktion nicht in Betrieb";
VAL_ 623 FRVEH_OBJ_ID 253 "SIGNALTAG_FCTIF_NOT_AVAILABLE" 254 "SIGNALTAG_FCT_ERROR" 255 "Sendefunktion nicht in Betrieb";
VAL_ 623 FRVEH_V_X 4093 "SIGNALTAG_FCTIF_NOT_AVAILABLE" 4094 "SIGNALTAG_FCT_ERROR" 4095 "Sendefunktion nicht in Betrieb";
VAL_ 623 FRVEH_V_Y 4093 "SIGNALTAG_FCTIF_NOT_AVAILABLE" 4094 "SIGNALTAG_FCT_ERROR" 4095 "Sendefunktion nicht in Betrieb";
VAL_ 623 FRVEH_GAP_X 4093 "SIGNALTAG_FCTIF_NOT_AVAILABLE" 4094 "SIGNALTAG_FCT_ERROR" 4095 "Sendefunktion nicht in Betrieb";
VAL_ 623 FRVEH_GAP_Y 4093 "SIGNALTAG_FCTIF_NOT_AVAILABLE" 4094 "SIGNALTAG_FCT_ERROR" 4095 "Sendefunktion nicht in Betrieb";
VAL_ 623 QualifierEventDataFunctionFrontV 0 "Event Data Available" 1 "Event Data Available - Reduced" 2 "Event Data Not Available";
VAL_ 623 QualifierExtendedFunctionFrontVe 0 "Normal Operation Mode" 1 "Power Up Or Down" 2 "Sensor Not Calibrated" 3 "Sensor Blocked" 4 "Sensor Misaligned" 5 "Bad Sensor Environmental Condition" 6 "Reduced Field Of View" 7 "Input Not Available" 8 "Internal Reason" 9 "External Distortion" 10 "Beginning Blockage" 11 "Selftest" 12 "Standby, valid from SP2018" 13 "External Failure, valid from SP2018" 15 "There is no extendedQualifier information available, due to the event data being invalid (e.g. CRC error) or due to a timeout.";
VAL_ 624 FRVEH_EXT_OBJ_ID 253 "SIGNALTAG_FCTIF_NOT_AVAILABLE" 254 "SIGNALTAG_FCT_ERROR" 255 "Sendefunktion nicht in Betrieb";
VAL_ 624 FRVEH_EXT_OBJ_TYP 0 "Pedestrian" 1 "Cyclist" 2 "Bike_Motorbike_Moped" 3 "Car_With_Or_Without_Trailer" 4 "Truck_Bus_Van" 5 "Other_Vehicle_Customary_Road_User_According_To_Scene_Catalogue" 6 "Road_Boundary" 7 "Bridge" 8 "Unknown" 253 "SIGNALTAG_FCTIF_NOT_AVAILABLE" 254 "SIGNALTAG_FCT_ERROR" 255 "Sendefunktion nicht in Betrieb";
VAL_ 624 FRVEH_EXT_ST_MOV 0 "Stationary_Or_Parking_Object" 1 "Stopped_Object_Movement_Direction_Was Oncoming" 2 "Stopped_Object_Movement_Direction_Was_Same_As_EGOVehicle" 3 "Stopped_Object_Movement_Direction_Was_Unknown" 4 "Moving_Object_Movement_Direction_Oncomming" 5 "Moving_Object_Movement_Direction_Same_As_EGOVehicle" 6 "Moving_Object_Movement_Direction_Unknown" 253 "SIGNALTAG_FCTIF_NOT_AVAILABLE" 254 "SIGNALTAG_FCT_ERROR" 255 "Sendefunktion nicht in Betrieb";
VAL_ 624 FRVEH_EXT_WID 253 "SIGNALTAG_FCTIF_NOT_AVAILABLE" 254 "SIGNALTAG_FCT_ERROR" 255 "Sendefunktion nicht in Betrieb";
VAL_ 1073 ST_SER_DSCO_PLG 1 "Service Disconnector offen" 2 "Service Disconnector steckt" 3 "Signal ungültig";
VAL_ 1073 PRD_DUR_CHGNG 65533 "Hinweis: Reserviert für funktionale Kennung Signal-Tag." 65534 "Hinweis: Reserviert für funktionale Kennung Signal-Tag." 65535 "Sendefunktion nicht in Betrieb.";
VAL_ 569 PRD_ENERG_CHGTAR_2_HVSTO 65533 "Hinweis: Reserviert für funktionale Kennung Signal-Tag." 65534 "Hinweis: Reserviert für funktionale Kennung Signal-Tag." 65535 "Sendefunktion nicht in Betrieb";
VAL_ 569 AVL_ISRE 253 "SIGNALTAG_FCTIF_NOT_AVAILABLE" 254 "SIGNALTAG_FCT_ERROR" 255 "Sendefunktion nicht in Betrieb";
VAL_ 1046 ER_RNG 65533 "Wenn der elektrische Antrieb nicht verfügbar ist müssen Striche angezeigt werden." 65534 "Keine_Angabe" 65535 "Sendefunktion nicht in Betrieb";
VAL_ 1046 ENG_TEMP_EV 0 "Keine_Anzeige" 1 "COLD" 2 "OK" 3 "HOT" 4 "Striche" 15 "Sendefunktion nicht in Betrieb";
VAL_ 1017 ST_MOD_DRV 0 "ST_USECASE_ANTR_DEFAULT" 1 "ST_USECASE_ANTR_SPORT" 2 "ST_USECASE_ANTR_ECO" 3 "ST_USECASE_ANTR_COMFORT" 4 "ST_USECASE_ANTR_EV" 13 "Hinweis: Reserviert für funktionale Kennung Signal-Tag." 14 "Hinweis: Reserviert für funktionale Kennung Signal-Tag." 15 "Sendefunktion nicht in Betrieb";
VAL_ 1017 ST_DRV_VEH 0 "Hochvoltsystem ist aktiv und \"Startwunsch durch Fahrer\" liegt vor." 1 "DME erkennt drehenden Motor und Startendedrehzahl noch nicht erreicht. Kann auch durch Anschleppen des Fahrzeugs entstehen. Es liegt kein MSA Startbefehl vor." 2 "Setzen \"VM läuft\" ab Startendedrehzahl. Zurücknehmen ab \"VM im Auslauf\" (Stoppbefehl vorhanden) oder \"VM steht\" (Abwürgen; Abschnappen = ohne Wunsch)" 4 "Codierung wird nicht verwendet" 6 "Codierung wird nicht verwendet" 8 "DME erkennt stehenden Motor (inkl. Abwürgen, Abschnappen und evtl. Synchronisationsverlust) und ist über MSA startfähig";
VAL_ 1017 ST_ENG_RUN_DRV 0 "Motor aus" 1 "Motor startet" 2 "Motor läuft" 3 "Signal ungültig";
VAL_ 1017 ST_SW_CLT_DRV 0 "Kupplung nicht betätigt" 1 "Kupplung betätigt" 3 "Signal ungültig / Kupplung nicht vorhanden";
VAL_ 1017 ST_IDLG_ENG_DRV 0 "Verbrennungsmotor im Leerlauf" 1 "Verbrennungsmotor nicht im Leerlauf" 3 "Signal ungültig";
VAL_ 1017 RLS_ENGSTA 0 "Kein Motorstart erlaubt. (Drehzahl größergleich Motor-Läuft-Schwelle)" 1 "Anlasseransteuerung wird verzögert, z.B. weil der Diesel noch Vorglühen muss, oder VVT-Relais werden noch angezogen, oder der Motor wird gerade abgestellt, befindet sich im \"Auslaufen\" (Drehzahl größer 32 und kleiner Motor-Läuft-Schwelle)" 2 "Der Motor darf gestartet werden." 3 "Signal ungültig";
VAL_ 1017 RDUC_DOCTR_RPM_DRV_2 0 "in Ordnung" 1 "Entspricht dem bisherigen \"Absenken der Abregeldrehzahl\"" 2 "große Reduzierung der Abregeldrehzahl" 3 "Signal ungültig";
VAL_ 513 V_DRV_EL_MAX 253 "Hinweis: Reserviert für funktionale Kennung Signal-Tag." 254 "Hinweis: Reserviert für funktionale Kennung Signal-Tag." 255 "Sendefunktion nicht in Betrieb";
VAL_ 513 DISP_LIM_V_URB 253 "Hinweis: Reserviert für funktionale Kennung Signal-Tag." 254 "Hinweis: Reserviert für funktionale Kennung Signal-Tag." 255 "Sendefunktion nicht in Betrieb";
VAL_ 984 RQ_SW_DXP_KDIS 0 "Kein Trigger für Kombi Liste und Stellhebeleinstellungen." 1 "Trigger Kombi Liste anzeigen und Stellhebeleinstellungen aktualisieren." 2 "Initialisierung" 3 "Signal ungültig";
VAL_ 984 AVL_MOD_DXP 0 "Initialisierung" 1 "Sport_Dynamic" 2 "Sport_Expert" 3 "Sport_Individual" 4 "Comfort" 5 "Comfort_Plus" 6 "Comfort_Individual" 7 "ECO_PRO_Efficient" 8 "ECO_PRO_Plus" 9 "ECO_PRO_Individual" 10 "SP2018: Dieser FES Modus wird auch im PHEV angesprungen. Kein PHEV-spezifischer Adaptive Modus" 11 "Offroad_Ice" 12 "Offroad_Smooth" 13 "Offroad_Grip" 14 "Offroad_Rough" 15 "Nutzung in PHEVs ab SP2018" 16 "Nutzung in PHEVs ab SP2018" 17 "Nutzung in PHEVs ab SP2018" 18 "Nutzung in PHEVs ab SP2018" 19 "Nutzung in PHEVs ab SP2018" 20 "Nutzung in PHEVs ab SP2018" 21 "Nutzung in PHEVs ab SP2018" 22 "Nutzung in PHEVs ab SP2018" 23 "Nutzung in PHEVs ab SP2018" 24 "Nutzung ab SP2021" 25 "Nutzung ab SP2021" 26 "Nutzung ab SP2021" 27 "Nutzung ab SP2021" 28 "Nutzung ab SP2021" 61 "Hinweis: Reserviert für  funktionale Kennung Signal-Tag." 62 "Hinweis: Reserviert für  funktionale Kennung Signal-Tag." 63 "Sendefunktion nicht in Betrieb";
VAL_ 325 BoostReserve 253 "SIGNALTAG_FCTIF_NOT_AVAILABLE" 254 "SIGNALTAG_FCT_ERROR" 255 "Sendefunktion nicht in Betrieb";
VAL_ 325 BoostFunctionState 0 "Function is not active in \"Sport Individual\"" 1 "Function is active in \"Sport Individual\"" 3 "Sendefunktion nicht in Betrieb";
VAL_ 325 BoostState 0 "Funktion nicht aktiv" 1 "Boost wird nicht abgerufen und ist verfügbar" 2 "Boost wird nicht abgerufen und ist nicht verfügbar" 3 "Boost wird abgerufen" 13 "SIGNALTAG_FCTIF_NOT_AVAILABLE" 14 "SIGNALTAG_FCT_ERROR" 15 "Sendefunktion nicht in Betrieb";
VAL_ 668 DisplayPowerCharging 65533 "SIGNALTAG_FCTIF_NOT_AVAILABLE" 65534 "SIGNALTAG_FCT_ERROR" 65535 "Sendefunktion nicht in Betrieb";
VAL_ 668 DisplayChargeModus 0 "Ladebetriebsmodus_aus" 1 "Ladebetriebsmodus_1_Phase" 2 "Ladebetriebsmodus_3_Phasen" 13 "SIGNALTAG_FCTIF_NOT_AVAILABLE" 14 "SIGNALTAG_FCT_ERROR" 15 "Sendefunktion nicht in Betrieb";
VAL_ 668 StatusPredictionRangeChargingTar 4093 "SIGNALTAG_FCTIF_NOT_AVAILABLE" 4094 "SIGNALTAG_FCT_ERROR" 4095 "Sendefunktion nicht in Betrieb";
VAL_ 668 StatusChargeControlPlug 1 "Ladestecker_entriegelt" 2 "Ladestecker_verriegelt" 3 "Sendefunktion nicht in Betrieb";
VAL_ 668 StatusSoeChargingTarget 125 "SIGNALTAG_FCTIF_NOT_AVAILABLE" 126 "SIGNALTAG_FCT_ERROR" 127 "Sendefunktion nicht in Betrieb";
VAL_ 839 DisplayPowerChargingDCMax 65533 "SIGNALTAG_FCTIF_NOT_AVAILABLE" 65534 "SIGNALTAG_FCT_ERROR" 65535 "Sendefunktion nicht in Betrieb";
VAL_ 839 DisplayPowerChargingACMax 65533 "SIGNALTAG_FCTIF_NOT_AVAILABLE" 65534 "SIGNALTAG_FCT_ERROR" 65535 "Sendefunktion nicht in Betrieb";
VAL_ 839 DisplayPowerChargingInfrastructu 65533 "SIGNALTAG_FCTIF_NOT_AVAILABLE" 65534 "SIGNALTAG_FCT_ERROR" 65535 "Sendefunktion nicht in Betrieb";
VAL_ 839 DisplayDegradationInfrastructure 0 "keine Anzeige" 1 "Anzeige" 5 "SIGNALTAG_FCTIF_NOT_AVAILABLE" 6 "SIGNALTAG_FCT_ERROR" 7 "Sendefunktion nicht in Betrieb";
VAL_ 576 NumberCheckcontrolSMBF 65535 "Signal_unbefuellt";
VAL_ 576 StatusCheckcontrolSMBF 0 "Betreffende CC-Meldung wird gelöscht" 1 "CC-Meldung Anzeige" 3 "Signal_unbefuellt";
VAL_ 576 TransmissiontypeCheckcontrolSMBF 15 "Signal_unbefuellt";
VAL_ 576 StatusIndicateCheckcontrolSMBF 0 "Kein_Blinken" 1 "Langsamer Takt = 1 Hz" 2 "Schneller Takt = 3 Hz" 3 "Signal_unbefuellt";
VAL_ 587 NumberCheckcontrolSMBFH 65535 "Signal_unbefuellt";
VAL_ 587 StatusCheckcontrolSMBFH 0 "Betreffende CC-Meldung wird gelöscht" 1 "CC-Meldung Anzeige" 3 "Signal_unbefuellt";
VAL_ 587 TransmissiontypeCheckcontrolSMBF 15 "Signal_unbefuellt";
VAL_ 587 StatusIndicateCheckcontrolSMBFH 0 "Kein_Blinken" 1 "Langsamer Takt = 1 Hz" 2 "Schneller Takt = 3 Hz" 3 "Signal_unbefuellt";
VAL_ 564 NumberCheckcontrolSMFA 65535 "Signal_unbefuellt";
VAL_ 564 StatusCheckcontrolSMFA 0 "Betreffende CC-Meldung wird gelöscht" 1 "CC-Meldung Anzeige" 3 "Signal_unbefuellt";
VAL_ 564 TransmissiontypeCheckcontrolSMFA 15 "Signal_unbefuellt";
VAL_ 564 StatusIndicateCheckcontrolSMFA 0 "Kein_Blinken" 1 "Langsamer Takt = 1 Hz" 2 "Schneller Takt = 3 Hz" 3 "Signal_unbefuellt";
VAL_ 583 NumberCheckcontrolSMFAH 65535 "Signal_unbefuellt";
VAL_ 583 StatusCheckcontrolSMFAH 0 "Betreffende CC-Meldung wird gelöscht" 1 "CC-Meldung Anzeige" 3 "Signal_unbefuellt";
VAL_ 583 TransmissiontypeCheckcontrolSMFA 15 "Signal_unbefuellt";
VAL_ 583 StatusIndicateCheckcontrolSMFAH 0 "Kein_Blinken" 1 "Langsamer Takt = 1 Hz" 2 "Schneller Takt = 3 Hz" 3 "Signal_unbefuellt";
VAL_ 1174 DisplayRefillVolumeWaterInjectio 253 "Begründung für Entfall der funktionalen Kennung" 254 "Begründung für Entfall der funktionalen Kennung" 255 "Sendefunktion nicht in Betrieb";
VAL_ 1174 DisplayFluidLevelWaterInjection 13 "SIGNALTAG_FCTIF_NOT_AVAILABLE" 14 "SIGNALTAG_FCT_ERROR" 15 "Sendefunktion nicht in Betrieb";
VAL_ 1174 DispAvailabilityWaterInjection 0 "Keine_Einschraenkung" 1 "System_ist_defekt" 2 "Wasser_wegen_Vereisung_nicht_verfuegbar" 4 "Wasserqualitaet_unzureichend" 8 "Wassertank_leer" 16 "Wasserqualitaet_maessig" 32 "Fuellstand_Wassertank_gering" 64 "Anzeige_Nachfuellmenge_und_Fuellstand_fuer_Wassereinspritzung_deaktivieren" 1021 "Reserviert_nicht_verfuegbar" 1022 "Reserviert_meldet_Fehler" 1023 "Sendefunktion nicht in Betrieb";
VAL_ 180 CTR_ECU_CHAS 0 "HSR aus" 1 "EKP ein" 2 "USS ein" 4 "KAFAS/FLA ein" 8 "NiVi ein" 16 "HC2 ein" 32 "iCAM 2 / iCAM_RFK  ein" 64 "ACSM ein" 128 "SAS ein" 256 "DSC_Modul ein" 512 "EPS ein" 1024 "HSR ein" 2048 "LMV ein" 4096 "QSG ein" 8192 "ASA ein" 16384 "VDP ein" 32768 "VDP_h ein" 65536 "IKE_3D / IKE_Basis ein" 131072 "FRR_MRR_ein" 524288 "emARS_v ein" 1048576 "emARS_h ein" 2097152 "DCS ein" 4194304 "RSR / RSL ein" 8388608 "ELV ein" 16777216 "Gilt ab SP2018" 33554432 "GSD_ein" 67108864 "Gilt ab SP 2018" 134217728 "Gilt ab SP 2018" 268435456 "Gilt ab SP 2018" 4294967295 "Signal_unbefuellt";
VAL_ 182 CTR_ECU_ENTAI 0 "ETC_aus" 1 "ZBE ein" 2 "ZBE_Fond ein" 8 "VideoSwitch ein" 16 "TPL ein" 32 "ATM_ATM_Basis_ein" 64 "ASD ein" 128 "GEK ein" 256 "Head_Unit_Radio_MGU_BIS_ein" 512 "Gilt ab SP 2018" 1024 "Gilt ab SP 2018" 2048 "Analoguhr_ein" 4096 "Gilt ab SP 2018" 8192 "Gilt ab SP 2018" 32768 "NFC_ein" 65536 "WCA_ein" 131072 "ETC_ein" 16777215 "Signal_unbefuellt";
VAL_ 759 LANG 0 "Keine Sprache" 1 "Deutsch" 2 "Englisch (UK)" 3 "Englisch (US)" 4 "Spanisch" 5 "Italienisch" 6 "Französisch" 7 "Flämisch" 8 "Niederländisch" 9 "Arabisch" 10 "Chinesisch Traditionell" 11 "Chinesisch Simple" 12 "Koreanisch" 13 "Japanisch" 14 "Russisch" 15 "Französisch (CA)" 16 "Spanisch (US)" 17 "Portugiesisch" 18 "Polnisch" 19 "Griechisch" 20 "Türkisch" 21 "Ungarisch" 22 "Rumänisch" 23 "Schwedisch" 24 "Portugiesisch (BR)" 25 "Es handelt sich bei dieser Codierung um einen Vorhalt für die Sprachverarbeitung. Die Sprache ist nicht für die Anzeige vorgesehen." 26 "Es handelt sich bei dieser Codierung um einen Vorhalt für die Sprachverarbeitung. Die Sprache ist nicht für die Anzeige vorgesehen." 27 "Ab BN2020 gültig" 28 "Ab BN2020 gültig" 29 "Ab BN2020 gültig" 30 "Ab BN2020 gültig" 31 "Ab BN2020 gültig" 32 "Ab BN2020 gültig" 33 "Indonesisch" 34 "Thai" 35 "Hebraeisch_Ivrit" 36 "Vietnamesisch" 37 "Ukrainisch" 255 "Signal ungültig";
VAL_ 759 UN_DATE 0 "Default = Keine Angabe" 1 "Reihenfolge: Tag.Monat.Jahr" 2 "Reihenfolge: Monat/Tag/Jahr" 3 "Signal ungültig";
VAL_ 759 UN_SPDM_DGTL 0 "Default = Keine Angabe" 1 "Kilometer" 2 "Meilen" 3 "Signal ungültig";
VAL_ 759 UN_COSP 0 "Default = Keine Angabe" 1 "l/100km" 2 "mpg (UK)" 3 "mpg (US)" 4 "km/l" 7 "Signal ungültig";
VAL_ 759 UN_FU 0 "Default = Keine Angabe" 1 "Liter" 2 "Galonen (UK)" 3 "Galonen (US)" 7 "Signal ungültig";
VAL_ 759 UN_DATE_EXT 0 "Default = Keine Änderung" 1 "ECE" 2 "US" 3 "Reihenfolge: Tag/Monat/Jahr" 4 "Reihenfolge: Tag-Monat-Jahr" 5 "Arabien" 6 "Asien" 7 "Reihenfolge: Jahr-Monat-Tag" 31 "Signal ungültig";
VAL_ 759 UN_PWR_S_MOD 0 "Default = Keine Angabe" 1 "Kilowatt" 2 "Pferdestärken" 15 "Signal ungültig";
VAL_ 759 UN_TORQ_S_MOD 0 "Default = Keine Angabe" 1 "Nm" 2 "lb-ft" 3 "kgm" 15 "Signal ungültig";
VAL_ 759 UN_COSP_EL 0 "Default = Keine Angabe" 1 "kWh / 100km" 2 "mi / kWh" 3 "Km / kWh" 4 "wird nur in SP2013 (ohne 444, F15-F16, UKL) verwendet" 5 "wird nur in SP2013 (ohne 444, F15-F16, UKL) verwendet" 6 "Gilt ab SP2015" 15 "Signal ungültig";
VAL_ 589 CTR_ERRM_BN_U 0 "Überspannungsschwelle nicht erreicht." 1 "Unterspannungsschwelle für Normalbetrieb unterschritten." 2 "Unterspannungsschwelle für MSA-Start Festigkeit unterschritten." 4 "Überspannungsschwelle überschritten." 61 "SIGNALTAG_FCTIF_NOT_AVAILABLE" 62 "SIGNALTAG_FCT_ERROR" 63 "Sendefunktion nicht in Betrieb";
VAL_ 904 TYP_VEH 0 "Keine Angabe" 1 "E65" 2 "E66" 3 "E67" 4 "E60" 5 "E61" 6 "E63" 7 "E64" 8 "E90" 9 "RR01" 10 "E81" 11 "E82" 12 "E87" 13 "E91" 14 "E92" 15 "E93" 16 "E70" 17 "E71" 18 "E88" 19 "R55" 20 "Verwendung auch für R58" 21 "Verwendung auch für R59" 22 "E89" 23 "E72" 24 "F01" 25 "F02" 26 "F03" 27 "F07" 28 "F10" 29 "F11" 30 "F12" 31 "F13" 32 "F04" 33 "F31" 34 "F32" 35 "F33" 36 "F20" 37 "F30" 38 "F22" 39 "F23" 40 "Verwendung auch für M12" 41 "F25" 42 "R60" 43 "RR4" 44 "F21" 45 "E70NF" 46 "E71NF" 47 "5er_lang in China" 48 "5 türiger F56" 49 "R56NF" 50 "6er Coupé 4-türig" 51 "F34" 52 "F35" 53 "RR5" 54 "CAT (Compact Activity Tourer)" 55 "MCV" 56 "444" 57 "M3 Limousine" 58 "M3 Coupé" 59 "M3 Cabrio" 60 "X5-M" 61 "X6-M" 62 "R61" 63 "FaST" 64 "X1 lang für China" 65 "4er Compact" 66 "V-Reihe" 67 "Advanced Sports Tourer (AST)" 68 "X4" 69 "3er Fünftürer Coupé" 70 "MINI" 71 "MINI" 72 "Joy 3 Door" 73 "Joy 5 Door" 74 "MAT" 75 "7er" 76 "7er lang" 77 "5er GT" 78 "5er Limousine" 79 "5er Limousine lang China" 80 "5er Touring" 81 "X3" 82 "3er Limousine" 83 "X5" 84 "6er Cabrio" 85 "6er Cabrio 4-Türer" 86 "3er Limousine China" 87 "6er Coupé 2-Türer" 88 "3er Touring" 89 "X6" 90 "RR6" 91 "3er GT" 92 "3er Coupé" 93 "3er Cabrio" 94 "4er Coupé" 95 "F47" 96 "F48" 97 "MINI" 98 "1er Limousine" 99 "X1 China lang elektrisch" 100 "F87" 101 "F39" 102 "1er (5-Türer)" 103 "1er (3-Türer)" 104 "M5" 105 "M6 Cabrio" 106 "M6 Coupe" 107 "M6 Grand Coupe" 110 "X4" 111 "X7" 112 "X3 China" 113 "Z4" 114 "RR Phantom" 115 "RR Phantom lang" 116 "RR Ghost" 117 "RR Ghost lang" 118 "RR Wraith" 119 "RR Cabrio" 120 "RR Cullinan" 121 "M3" 122 "M4 Coupe" 123 "M4 Cabrio" 124 "X5 M" 125 "X6 M" 126 "X3 M" 127 "X4 M" 128 "F03 NF" 129 "J29" 130 "I8 Spyder" 131 "M2 Cabrio" 132 "2er Gran Coupé" 133 "2er Coupe" 134 "2er Cabrio" 135 "iNEXT" 136 "7er Limousine (Lang)" 137 "7er Limousine" 138 "2er Active Tourer" 139 "X1" 140 "I8 Coupé" 141 "5er Limousine" 142 "X5 Lang-Version" 143 "X8" 144 "5er Limousine lang China NF" 145 "Mini (3-Türer)" 146 "Mini (5-Türer)" 147 "WEY GWM (5-Türer)" 148 "Mini Countryman" 149 "M3 Touring" 150 "M2 Coupe" 151 "5er Touring (G31NF)" 152 "X5 (G05NF)" 153 "X6 (G06NF)" 154 "X7 (G07NF)" 155 "8er Gran Coupe (G16NF)" 156 "M5" 157 "M5 Touring" 158 "M8 Grand Coupe" 159 "X3 (G01 NF)" 160 "X1 China lang" 161 "MINI Hatchback 5-tuerig (F55GEN)" 162 "MINI Hatchback 3-tuerig alt (F56GEN)" 163 "MINI Cabrio (F57 NF)" 164 "1er Reihe Hatchback 5-tuerig (F40NG)" 165 "2er Reihe Coupe 4-tuerig (F44NG)" 166 "2er Reihe Coupe 4-tuerig lang" 167 "X2 (F39NF)" 168 "7er Sicherheitsfahrzeug" 169 "M5 Touring" 170 "G97" 171 "G98" 172 "MINI SAV 5-tuerig" 173 "X4 Coupe 5-tuerig" 174 "X3 SAV 5-tuerig" 255 "Sendefunktion nicht in Betrieb";
VAL_ 904 TYP_BODY 1 "Limousine" 2 "Coupe" 3 "Touring" 4 "Cabrio" 5 "Roadster" 6 "Compact" 7 "Sicherheitsfahrzeug" 8 "Light Protection" 9 "Sport-Coupe (Z3 Coupe)" 10 "4 x 4 single piece tailgate" 11 "4 x 4 two piece tailgate" 33 "ab SP2013 gültig" 34 "ab SP2013 gültig" 35 "Sports Touring (ab SP2013 gültig)" 38 "Sports Compact (ab SP2013 gültig)" 39 "Multi Purpose Vehicle" 50 "Compact Coupe (ab SP2013 gültig)" 51 "Mini Touring (ab SP2013 gültig)" 54 "Mini Compact (ab SP2013 gültig)" 255 "Signal ungültig";
VAL_ 904 QUAN_CYL 0 "wird nur in rein elektrischen Fahrzeugen ab SP2013 versendet" 3 "3 Zylinder" 4 "4 Zylinder" 5 "5 Zylinder" 6 "6 Zylinder" 8 "8 Zylinder" 10 "10 Zylinder" 12 "12 Zylinder" 15 "Signal ungültig";
VAL_ 904 QUAN_GR 0 "Stufenlos" 4 "4 Gänge" 5 "5 Gänge" 6 "6 Gänge" 7 "Wird derzeit nur in M-Fahrzeugen genutzt! (Für SMG Mk3)" 8 "8 Gänge" 15 "Signal ungültig";
VAL_ 904 TYP_ENG 0 "Keine Angabe über den Motor" 4 "Benzin Direkteinspritzung" 5 "Benzin konventionell" 6 "Diesel Direkteinspritzung" 7 "Diesel konventionell" 8 "ab SP2013 gültig" 9 "ab SP2013 gültig" 15 "Signal ungültig";
VAL_ 904 TYP_STE 1 "Linkslenker" 2 "Rechtslenker" 15 "Signal ungültig";
VAL_ 904 CLAS_PWR 0 "Gilt ab SP2021" 3 "Steht nicht in BN2000 zur Verfügung" 7 "Steht nicht in BN2000 zur Verfügung" 11 "Steht nicht in BN2000 zur Verfügung" 12 "Untere Leistungsklasse (UL)" 13 "Mittlere Leistungsklasse (ML)" 14 "Obere Leistungsklasse (OL)" 15 "Signal ungültig";
VAL_ 1103 RSU_RLS_FLLUP_FEPM 0 "Keine_Freigabe" 255 "Signal_unbefuellt";
VAL_ 1103 RSU_RREF_FLLUP_FEPM 0 "Wird gesetzt bei Freigabe erteilt" 1 "Keine Nachlaufanforderung gestellt" 2 "Batterie wird geladen" 3 "Temporaere_Ablehnung_Batterietemperatur" 4 "Temporaere_Ablehnung_Nachlauf" 5 "Hardware defekt" 6 "Zaehler_RSU_Anforderungen_ueberschritten" 12 "Sonstiger Grund für Ablehnung" 15 "Signal_unbefuellt";
VAL_ 1103 RSU_DCHG_COU_BN_BT 0 "Keine_Funktion" 16777215 "Sendefunktion nicht in Betrieb";
VAL_ 1103 ST_ENSU 0 "Energie-Management auf dem Antriebssteuergerät hat keine relevanten aktiven Fehlerspeicher bzgl. Energieversorgung" 1 "Energie-Management hat mindestens einen relevanten aktiven Fehlerspeicher bzgl. Energieversorgung" 13 "Hinweis: Reserviert für funktionale Kennung Signal-Tag." 14 "SIGNALTAG_FCT_ERROR" 15 "Sendefunktion nicht in Betrieb";
VAL_ 1102 RSU_ST_FLSH_RSLT 0 "SW Update läuft" 1 "Letztes_Software_Update_i_O" 2 "Letztes_Software_Update_n_i_O" 5 "SIGNALTAG_FCTIF_NOT_AVAILABLE" 6 "SIGNALTAG_FCT_ERROR" 7 "Sendefunktion nicht in Betrieb";
VAL_ 958 FLLUPT_GPWSUP 4094 "Dauer EIN" 4095 "Signal ungültig";
VAL_ 940 FLLUPT_KL_30_ERCTR 4094 "Dauer EIN" 4095 "Signal ungültig";
VAL_ 940 TYP_DSCO_KL_30_ERCTR 0 "Keine Abschaltung" 1 "Reset" 2 "Dauerhafte Abschaltung" 3 "Signal ungültig";
VAL_ 970 MUX_FRC_RD_INFO 3 "Komfort" 4 "Sport" 5 "Sport+" 7 "ECO Pro" 8 "ECO Pro+" 15 "Signal ungültig";
VAL_ 967 MUX_FRC_RT_DSTN 3 "Komfort" 4 "Sport" 5 "Sport+" 7 "Eco Pro" 8 "Eco Pro+" 15 "Signal ungültig";
VAL_ 928 ST_ENERG_FZM 0 "ENSTATE_GOOD" 1 "ENSTATE_OK" 2 "ENSTATE_SHORTAGE" 3 "ENSTATE_SEVERE_SHORTAGE" 15 "Signal ungültig";
VAL_ 928 ST_ILK_ERRM_FZM 0 "Eintrag von Fehlern uneingeschränkt" 1 "Bereich Netzwerkfehler ist zu sperren" 2 "reserviert für zukünftige Erweiterungen" 3 "Signal ungültig";
VAL_ 620 GO_PY_AVAI 0 "Fehler im Audiosystem oder Verstärker überhitzt" 1 "Verfuegbar" 3 "Sendefunktion nicht in Betrieb";
VAL_ 1039 SRC_GPS_CTI_CAN 0 "GPS-Abgleich ist nicht aktuell" 1 "GPS-Abgleich ist aktuell" 13 "SIGNALTAG_FCTIF_NOT_AVAILABLE" 14 "SIGNALTAG_FCT_ERROR" 15 "Sendefunktion nicht in Betrieb";
VAL_ 1111 SRC_GPS_CTI_MOST 0 "GPS-Abgleich ist nicht aktuell" 1 "GPS-Abgleich ist aktuell" 13 "SIGNALTAG_FCTIF_NOT_AVAILABLE" 14 "SIGNALTAG_FCT_ERROR" 15 "Sendefunktion nicht in Betrieb";
VAL_ 1041 SRC_GPS_CTI_MOST 0 "GPS-Abgleich ist nicht aktuell" 1 "GPS-Abgleich ist aktuell" 13 "SIGNALTAG_FCTIF_NOT_AVAILABLE" 14 "SIGNALTAG_FCT_ERROR" 15 "Sendefunktion nicht in Betrieb";
VAL_ 1038 SRC_GPS_DATE_CAN 0 "GPS-Abgleich ist nicht aktuell" 1 "GPS-Abgleich ist  aktuell" 13 "SIGNALTAG_FCTIF_NOT_AVAILABLE" 14 "SIGNALTAG_FCT_ERROR" 15 "Sendefunktion nicht in Betrieb";
VAL_ 1110 SRC_GPS_DATE_MOST 0 "GPS-Abgleich ist nicht aktuell" 1 "GPS-Abgleich ist aktuell" 13 "SIGNALTAG_FCTIF_NOT_AVAILABLE" 14 "SIGNALTAG_FCT_ERROR" 15 "Sendefunktion nicht in Betrieb";
VAL_ 1040 SRC_GPS_DATE_MOST 0 "GPS-Abgleich ist nicht aktuell" 1 "GPS-Abgleich ist aktuell" 13 "SIGNALTAG_FCTIF_NOT_AVAILABLE" 14 "SIGNALTAG_FCT_ERROR" 15 "Sendefunktion nicht in Betrieb";
VAL_ 2675460105 GliwaDME1HostTxDummysignal 253 "SIGNALTAG_FCTIF_NOT_AVAILABLE" 254 "SIGNALTAG_FCT_ERROR" 255 "Sendefunktion nicht in Betrieb";
VAL_ 2675460106 GliwaDME1TxDummysignal 253 "SIGNALTAG_FCTIF_NOT_AVAILABLE" 254 "SIGNALTAG_FCT_ERROR" 255 "Sendefunktion nicht in Betrieb";
VAL_ 2675461120 GliwaDME2HostTxDummysignal 253 "SIGNALTAG_FCTIF_NOT_AVAILABLE" 254 "SIGNALTAG_FCT_ERROR" 255 "Sendefunktion nicht in Betrieb";
VAL_ 2675461121 GliwaDME2TxDummysignal 253 "SIGNALTAG_FCTIF_NOT_AVAILABLE" 254 "SIGNALTAG_FCT_ERROR" 255 "Sendefunktion nicht in Betrieb";
VAL_ 441 LIM_TORQ_CRSH_ACCM 253 "SIGNALTAG_FCTIF_NOT_AVAILABLE" 254 "SIGNALTAG_FCT_ERROR" 255 "Sendefunktion nicht in Betrieb";
VAL_ 441 LIM_PWR_ACCM_ENGMG 253 "Hinweis: Reserviert für funktionale Kennung Signal-Tag." 254 "Hinweis: Reserviert für funktionale Kennung Signal-Tag." 255 "Sendefunktion nicht in Betrieb";
VAL_ 441 RQ_AUWP_DME 61 "Hinweis: Reserviert für funktionale Kennung Signal-Tag." 62 "Hinweis: Reserviert für funktionale Kennung Signal-Tag." 63 "Sendefunktion nicht in Betrieb";
VAL_ 441 ST_BLEED_DME 0 "Nicht aktiv" 1 "Aktiv" 3 "Signal ungültig";
VAL_ 1067 EnergyDischargeHighVoltageStorag0 65533 "SIGNALTAG_FCTIF_NOT_AVAILABLE" 65534 "SIGNALTAG_FCT_ERROR" 65535 "Sendefunktion nicht in Betrieb";
VAL_ 1067 EnergyDischargeHighVoltageStorag1 65533 "SIGNALTAG_FCTIF_NOT_AVAILABLE" 65534 "SIGNALTAG_FCT_ERROR" 65535 "Sendefunktion nicht in Betrieb";
VAL_ 633 DISP_STA_PLG_T_HR 253 "Hinweis: Reserviert für funktionale Kennung Signal-Tag" 254 "Hinweis: Reserviert für funktionale Kennung Signal-Tag" 255 "Sendefunktion nicht in Betrieb";
VAL_ 633 DISP_STA_PLG_T_MN 253 "Hinweis: Reserviert für funktionale Kennung Signal-Tag" 254 "Hinweis: Reserviert für funktionale Kennung Signal-Tag" 255 "Sendefunktion nicht in Betrieb";
VAL_ 633 DISP_STA_PLG_T_WDAY 1 "Montag" 2 "Dienstag" 3 "Mittwoch" 4 "Donnerstag" 5 "Freitag" 6 "Samstag" 7 "Sonntag" 13 "Hinweis: Reserviert für funktionale Kennung Signal-Tag." 14 "Hinweis: Reserviert für funktionale Kennung Signal-Tag." 15 "Sendefunktion nicht in Betrieb";
VAL_ 633 ST_MAX_EDRV_WARN 0 "Max_EDRIVE_Warn_inaktiv" 1 "Max_EDRIVE_Warn_aktiv" 3 "Signal_unbefuellt";
VAL_ 633 DISP_END_CHGWIN_T_HR 253 "Hinweis: Reserviert für funktionale Kennung Signal-Tag" 254 "Hinweis: Reserviert für funktionale Kennung Signal-Tag" 255 "Sendefunktion nicht in Betrieb";
VAL_ 633 DISP_END_CHGWIN_T_MN 253 "Hinweis: Reserviert für funktionale Kennung Signal-Tag" 254 "Hinweis: Reserviert für funktionale Kennung Signal-Tag" 255 "Sendefunktion nicht in Betrieb";
VAL_ 633 DISP_STA_CHGWIN_T_HR 253 "Hinweis: Reserviert für funktionale Kennung Signal-Tag" 254 "Hinweis: Reserviert für funktionale Kennung Signal-Tag" 255 "Sendefunktion nicht in Betrieb";
VAL_ 633 DISP_STA_CHGWIN_T_MN 253 "Hinweis: Reserviert für funktionale Kennung Signal-Tag" 254 "Hinweis: Reserviert für funktionale Kennung Signal-Tag" 255 "Sendefunktion nicht in Betrieb";
SIG_GROUP_ 1021 e2eGrp_DT_DISP_GRDT 1 : CRC_DT_DISP_GRDT ALIV_DT_DISP_GRDT DISP_GR_GRB DISP_PRG_GRB DISP_PO_IDC_GRB DISP_PO_GRB DISP_SSC_IDC_GRB GEN_IDLI DISP_RQ_GR_GRB DISP_DRVLG_GRB StatusAvailabilityInterventionPo DT_DISP_GRDT_dummy_38_39;
SIG_GROUP_ 1017 e2eGrp_DT_PT_2 1 : CRC_DT_PT_2 ALIV_DT_PT_2 ST_MOD_DRV ST_DRV_VEH ST_ENG_RUN_DRV ST_SW_CLT_DRV ST_ILK_STRT_DRV ST_IDLG_ENG_DRV TEMP_ENG_DRV TEMP_EOI_DRV ST_GRSEL_DRV RLS_ENGSTA RDUC_DOCTR_RPM_DRV_2 RPM_ENG_MAX_ALW;
SIG_GROUP_ 529 e2eGrp_DisplayCheckcontrolDFNS1 1 : CRC_DisplayCheckcontrolDFNS1 ALIV_DisplayCheckcontrolDFNS1 CHL_DisplayCheckcontrolDFNS1 NumberDisplayCheckcontrolDFNS1 StatusDisplayCheckcontrolDFNS1 StatusIndicateDisplayCheckcontro DisplayCheckcontrolDFNS1_dummy_3 TransmissiontypeDisplayCheckcont DisplayCheckcontrolDFNS1_dummy_4;
SIG_GROUP_ 576 e2eGrp_DisplayCheckcontrolSMBF 1 : CRC_DisplayCheckcontrolSMBF ALIV_DisplayCheckcontrolSMBF CHL_DisplayCheckcontrolSMBF NumberCheckcontrolSMBF StatusCheckcontrolSMBF TransmissiontypeCheckcontrolSMBF StatusIndicateCheckcontrolSMBF;
SIG_GROUP_ 587 e2eGrp_DisplayCheckcontrolSMBFH 1 : CRC_DisplayCheckcontrolSMBFH ALIV_DisplayCheckcontrolSMBFH CHL_DisplayCheckcontrolSMBFH NumberCheckcontrolSMBFH StatusCheckcontrolSMBFH TransmissiontypeCheckcontrolSMBF StatusIndicateCheckcontrolSMBFH;
SIG_GROUP_ 564 e2eGrp_DisplayCheckcontrolSMFA 1 : CRC_DisplayCheckcontrolSMFA ALIV_DisplayCheckcontrolSMFA CHL_DisplayCheckcontrolSMFA NumberCheckcontrolSMFA StatusCheckcontrolSMFA TransmissiontypeCheckcontrolSMFA StatusIndicateCheckcontrolSMFA;
SIG_GROUP_ 583 e2eGrp_DisplayCheckcontrolSMFAH 1 : CRC_DisplayCheckcontrolSMFAH ALIV_DisplayCheckcontrolSMFAH CHL_DisplayCheckcontrolSMFAH NumberCheckcontrolSMFAH StatusCheckcontrolSMFAH TransmissiontypeCheckcontrolSMFA StatusIndicateCheckcontrolSMFAH;
SIG_GROUP_ 896 signalGrp_FAHRGESTELLNUMMER 1 : NO_VECH_1 NO_VECH_2 NO_VECH_3 NO_VECH_4 NO_VECH_5 NO_VECH_6 NO_VECH_7;
